VERSION "HNNBNNNYNNNNNNNNNNNNNNNNNNNNNNNNNNNNNNNNNN/4/%%%/4/'%**4NNN///"

NS_ :

BS_:

BU_: ABT_1_MIB_ab_Gen3 ABT_1_MQB BAP_Tester BT_1_MQB DU_1_MQB DU_2 DU_3 DU_4 ExBox Kombi_TT3 LSR_1 SCC1 SCC2 SDC1 SDC2 SFA TVTuner_ab_Gen3_JPN WLC_01 WLC_02 ZR_Entry ZR_High ZR_High_Korea ZR_High_TT3 ZR_MIB_OPTION_ab_Gen3 ZR_MIB_TOP_ab_Gen3 ZR_Standard

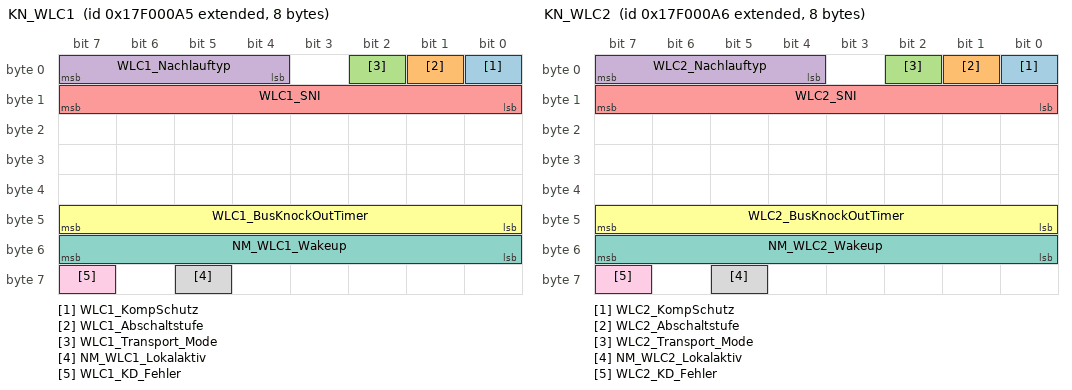
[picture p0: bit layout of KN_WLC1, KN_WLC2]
BO_ 2549088421 KN_WLC1: 8 WLC_01
 SG_ WLC1_KompSchutz : 0|1@1+ (1,0) [0|1] "" Vector__XXX
 SG_ WLC1_Abschaltstufe : 1|1@1+ (1,0) [0|1] "" Vector__XXX
 SG_ WLC1_Transport_Mode : 2|1@1+ (1,0) [0|1] "" Vector__XXX
 SG_ WLC1_Nachlauftyp : 4|4@1+ (1,0) [0|15] ""  ZR_High,ZR_High_Korea,ZR_MIB_OPTION_ab_Gen3,ZR_MIB_TOP_ab_Gen3,ZR_Standard
 SG_ WLC1_SNI : 8|8@1+ (1,0) [0|255] ""  ZR_High,ZR_High_Korea,ZR_MIB_OPTION_ab_Gen3,ZR_MIB_TOP_ab_Gen3,ZR_Standard
 SG_ WLC1_BusKnockOutTimer : 40|8@1+ (1,0) [0|254] "" Vector__XXX
 SG_ NM_WLC1_Wakeup : 48|8@1+ (1,0) [0|255] "" Vector__XXX
 SG_ NM_WLC1_Lokalaktiv : 61|1@1+ (1,0) [0|1] ""  ZR_High,ZR_High_Korea,ZR_MIB_OPTION_ab_Gen3,ZR_MIB_TOP_ab_Gen3,ZR_Standard
 SG_ WLC1_KD_Fehler : 63|1@1+ (1,0) [0|1] ""  ZR_High,ZR_High_Korea,ZR_MIB_OPTION_ab_Gen3,ZR_MIB_TOP_ab_Gen3,ZR_Standard

BO_ 2549088422 KN_WLC2: 8 WLC_02
 SG_ WLC2_KompSchutz : 0|1@1+ (1,0) [0|1] "" Vector__XXX
 SG_ WLC2_Abschaltstufe : 1|1@1+ (1,0) [0|1] "" Vector__XXX
 SG_ WLC2_Transport_Mode : 2|1@1+ (1,0) [0|1] "" Vector__XXX
 SG_ WLC2_Nachlauftyp : 4|4@1+ (1,0) [0|15] ""  ZR_High,ZR_High_Korea,ZR_MIB_OPTION_ab_Gen3,ZR_MIB_TOP_ab_Gen3,ZR_Standard
 SG_ WLC2_SNI : 8|8@1+ (1,0) [0|255] ""  ZR_High,ZR_High_Korea,ZR_MIB_OPTION_ab_Gen3,ZR_MIB_TOP_ab_Gen3,ZR_Standard
 SG_ WLC2_BusKnockOutTimer : 40|8@1+ (1,0) [0|254] "" Vector__XXX
 SG_ NM_WLC2_Wakeup : 48|8@1+ (1,0) [0|255] "" Vector__XXX
 SG_ NM_WLC2_Lokalaktiv : 61|1@1+ (1,0) [0|1] ""  ZR_High,ZR_High_Korea,ZR_MIB_OPTION_ab_Gen3,ZR_MIB_TOP_ab_Gen3,ZR_Standard
 SG_ WLC2_KD_Fehler : 63|1@1+ (1,0) [0|1] ""  ZR_High,ZR_High_Korea,ZR_MIB_OPTION_ab_Gen3,ZR_MIB_TOP_ab_Gen3,ZR_Standard

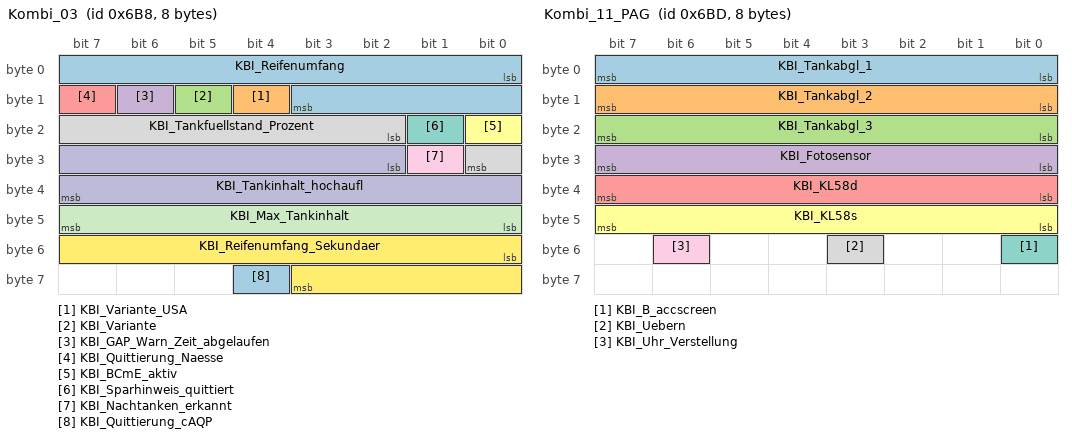
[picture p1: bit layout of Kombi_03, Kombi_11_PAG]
BO_ 1720 Kombi_03: 8 ZR_High_Korea
 SG_ KBI_Reifenumfang : 0|12@1+ (1,0) [0|4095] "Unit_MilliMeter"  ExBox
 SG_ KBI_Variante_USA : 12|1@1+ (1,0) [0|1] "" Vector__XXX
 SG_ KBI_Variante : 13|1@1+ (1,0) [0|1] "" Vector__XXX
 SG_ KBI_GAP_Warn_Zeit_abgelaufen : 14|1@1+ (1,0) [0|1] "" Vector__XXX
 SG_ KBI_Quittierung_Naesse : 15|1@1+ (1,0) [0|1] "" Vector__XXX
 SG_ KBI_BCmE_aktiv : 16|1@1+ (1,0) [0|1] "" Vector__XXX
 SG_ KBI_Sparhinweis_quittiert : 17|1@1+ (1,0) [0|1] "" Vector__XXX
 SG_ KBI_Tankfuellstand_Prozent : 18|7@1+ (1,0) [0|100] "Unit_PerCent" Vector__XXX
 SG_ KBI_Nachtanken_erkannt : 25|1@1+ (1,0) [0|1] "" Vector__XXX
 SG_ KBI_Tankinhalt_hochaufl : 26|14@1+ (0.01,0) [0|163.81] "Unit_Liter" Vector__XXX
 SG_ KBI_Max_Tankinhalt : 40|8@1+ (0.5,0) [0|126.5] "" Vector__XXX
 SG_ KBI_Reifenumfang_Sekundaer : 48|12@1+ (1,0) [0|4095] "Unit_MilliMeter" Vector__XXX
 SG_ KBI_Quittierung_cAQP : 60|1@1+ (1,0) [0|1] "" Vector__XXX

BO_ 1725 Kombi_11_PAG: 8 ZR_High
 SG_ KBI_Tankabgl_1 : 0|8@1+ (1,0) [0|255] "" Vector__XXX
 SG_ KBI_Tankabgl_2 : 8|8@1+ (1,0) [0|255] "" Vector__XXX
 SG_ KBI_Tankabgl_3 : 16|8@1+ (1,0) [0|255] "" Vector__XXX
 SG_ KBI_Fotosensor : 24|8@1+ (0.1,0) [0|25.3] "Unit_WattPerMeterSquar"  ABT_1_MQB
 SG_ KBI_KL58d : 32|8@1+ (0.4,0) [0|100] "Unit_PerCent" Vector__XXX
 SG_ KBI_KL58s : 40|8@1+ (1,0) [0|100] "Unit_PerCent"  ABT_1_MQB
 SG_ KBI_B_accscreen : 48|1@1+ (1,0) [0|1] "" Vector__XXX
 SG_ KBI_Uebern : 51|1@1+ (1,0) [0|1] "" Vector__XXX
 SG_ KBI_Uhr_Verstellung : 54|1@1+ (1,0) [0|1] "" Vector__XXX

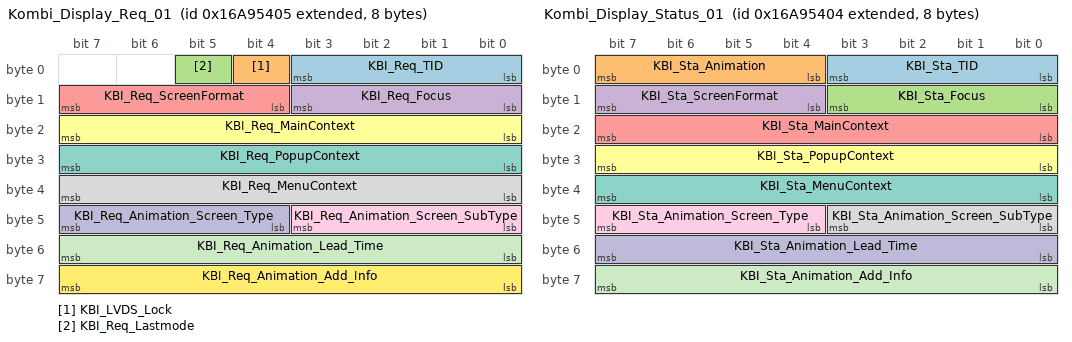
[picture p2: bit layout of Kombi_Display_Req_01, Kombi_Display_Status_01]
BO_ 2527679493 Kombi_Display_Req_01: 8 Kombi_TT3
 SG_ KBI_Req_TID : 0|4@1+ (1,0) [1|15] ""  ZR_High_TT3
 SG_ KBI_LVDS_Lock : 4|1@1+ (1,0) [0|1] ""  ZR_High_TT3
 SG_ KBI_Req_Lastmode : 5|1@1+ (1,0) [0|1] ""  ZR_High_TT3
 SG_ KBI_Req_Focus : 8|4@1+ (1,0) [0|15] ""  ZR_High_TT3
 SG_ KBI_Req_ScreenFormat : 12|4@1+ (1,0) [0|15] ""  ZR_High_TT3
 SG_ KBI_Req_MainContext : 16|8@1+ (1,0) [0|255] ""  ZR_High_TT3
 SG_ KBI_Req_PopupContext : 24|8@1+ (1,0) [2|255] ""  ZR_High_TT3
 SG_ KBI_Req_MenuContext : 32|8@1+ (1,0) [0|255] ""  ZR_High_TT3
 SG_ KBI_Req_Animation_Screen_SubType : 40|4@1+ (1,0) [0|15] ""  ZR_High_TT3
 SG_ KBI_Req_Animation_Screen_Type : 44|4@1+ (1,0) [0|15] ""  ZR_High_TT3
 SG_ KBI_Req_Animation_Lead_Time : 48|8@1+ (10,0) [0|2540] "Unit_MilliSecon"  ZR_High_TT3
 SG_ KBI_Req_Animation_Add_Info : 56|8@1+ (1,0) [0|255] ""  ZR_High_TT3

BO_ 2527679492 Kombi_Display_Status_01: 8 Kombi_TT3
 SG_ KBI_Sta_TID : 0|4@1+ (1,0) [1|15] ""  ZR_High_TT3
 SG_ KBI_Sta_Animation : 4|4@1+ (1,0) [0|15] ""  ZR_High_TT3
 SG_ KBI_Sta_Focus : 8|4@1+ (1,0) [0|15] ""  ZR_High_TT3
 SG_ KBI_Sta_ScreenFormat : 12|4@1+ (1,0) [0|15] ""  ZR_High_TT3
 SG_ KBI_Sta_MainContext : 16|8@1+ (1,0) [0|255] ""  ZR_High_TT3
 SG_ KBI_Sta_PopupContext : 24|8@1+ (1,0) [0|255] ""  ZR_High_TT3
 SG_ KBI_Sta_MenuContext : 32|8@1+ (1,0) [0|255] ""  ZR_High_TT3
 SG_ KBI_Sta_Animation_Screen_SubType : 40|4@1+ (1,0) [0|15] ""  ZR_High_TT3
 SG_ KBI_Sta_Animation_Screen_Type : 44|4@1+ (1,0) [0|15] ""  ZR_High_TT3
 SG_ KBI_Sta_Animation_Lead_Time : 48|8@1+ (10,0) [0|2540] "Unit_MilliSecon"  ZR_High_TT3
 SG_ KBI_Sta_Animation_Add_Info : 56|8@1+ (1,0) [0|255] ""  ZR_High_TT3

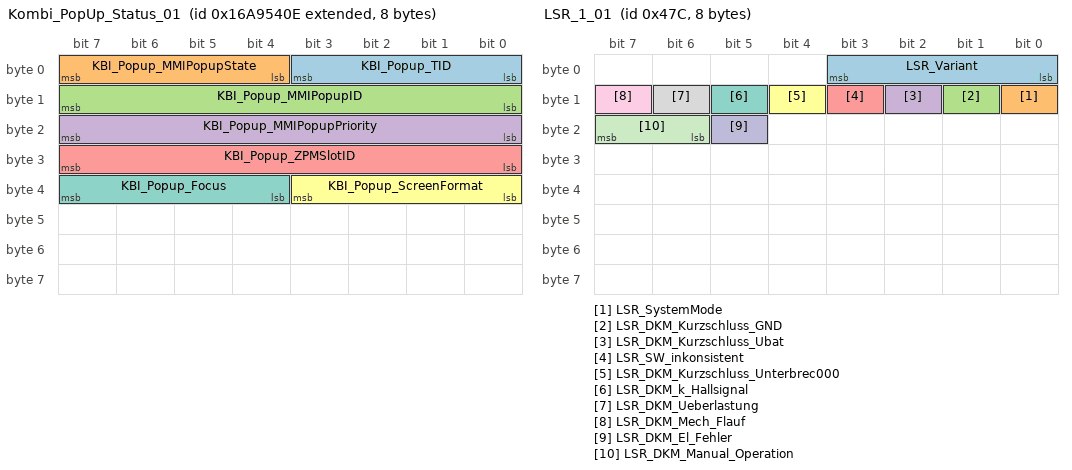
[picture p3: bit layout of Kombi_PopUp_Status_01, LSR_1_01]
BO_ 2527679502 Kombi_PopUp_Status_01: 8 Kombi_TT3
 SG_ KBI_Popup_TID : 0|4@1+ (1,0) [0|15] ""  ZR_High_TT3
 SG_ KBI_Popup_MMIPopupState : 4|4@1+ (1,0) [0|15] ""  ZR_High_TT3
 SG_ KBI_Popup_MMIPopupID : 8|8@1+ (1,0) [0|255] ""  ZR_High_TT3
 SG_ KBI_Popup_MMIPopupPriority : 16|8@1+ (1,0) [0|255] ""  ZR_High_TT3
 SG_ KBI_Popup_ZPMSlotID : 24|8@1+ (1,0) [0|255] ""  ZR_High_TT3
 SG_ KBI_Popup_ScreenFormat : 32|4@1+ (1,0) [0|15] ""  ZR_High_TT3
 SG_ KBI_Popup_Focus : 36|4@1+ (1,0) [0|15] ""  ZR_High_TT3

BO_ 2549899278 KS_SSN_ABT_1_Req: 8 Vector__XXX
 SG_ KS_SSN_ABT_1_Req_Data : 0|64@1+ (1,0) [0|1.84467440737096E+019] ""  ABT_1_MIB_ab_Gen3

BO_ 2550030350 KS_SSN_ABT_1_Resp: 8 ABT_1_MIB_ab_Gen3
 SG_ KS_SSN_ABT_1_Resp_Data : 0|64@1+ (1,0) [0|1.84467440737096E+019] "" Vector__XXX

BO_ 1148 LSR_1_01: 8 LSR_1
 SG_ LSR_Variant : 0|4@1+ (1,0) [1|15] ""  ZR_High,ZR_MIB_OPTION_ab_Gen3,ZR_MIB_TOP_ab_Gen3,ZR_Standard
 SG_ LSR_SystemMode : 8|1@1+ (1,0) [0|1] ""  ZR_High,ZR_MIB_OPTION_ab_Gen3,ZR_MIB_TOP_ab_Gen3,ZR_Standard
 SG_ LSR_DKM_Kurzschluss_GND : 9|1@1+ (1,0) [0|1] ""  ZR_High,ZR_MIB_OPTION_ab_Gen3,ZR_MIB_TOP_ab_Gen3,ZR_Standard
 SG_ LSR_DKM_Kurzschluss_Ubat : 10|1@1+ (1,0) [0|1] ""  ZR_High,ZR_MIB_OPTION_ab_Gen3,ZR_MIB_TOP_ab_Gen3,ZR_Standard
 SG_ LSR_SW_inkonsistent : 11|1@1+ (1,0) [0|1] ""  ZR_High,ZR_MIB_OPTION_ab_Gen3,ZR_MIB_TOP_ab_Gen3,ZR_Standard
 SG_ LSR_DKM_Kurzschluss_Unterbrec000 : 12|1@1+ (1,0) [0|1] ""  ZR_High,ZR_MIB_OPTION_ab_Gen3,ZR_MIB_TOP_ab_Gen3,ZR_Standard
 SG_ LSR_DKM_k_Hallsignal : 13|1@1+ (1,0) [0|1] ""  ZR_High,ZR_MIB_OPTION_ab_Gen3,ZR_MIB_TOP_ab_Gen3,ZR_Standard
 SG_ LSR_DKM_Ueberlastung : 14|1@1+ (1,0) [0|1] ""  ZR_High,ZR_MIB_OPTION_ab_Gen3,ZR_MIB_TOP_ab_Gen3,ZR_Standard
 SG_ LSR_DKM_Mech_Flauf : 15|1@1+ (1,0) [0|1] ""  ZR_High,ZR_MIB_OPTION_ab_Gen3,ZR_MIB_TOP_ab_Gen3,ZR_Standard
 SG_ LSR_DKM_El_Fehler : 21|1@1+ (1,0) [0|1] ""  ZR_High,ZR_MIB_OPTION_ab_Gen3,ZR_MIB_TOP_ab_Gen3,ZR_Standard
 SG_ LSR_DKM_Manual_Operation : 22|2@1+ (1,0) [0|3] ""  ZR_High,ZR_MIB_OPTION_ab_Gen3,ZR_MIB_TOP_ab_Gen3,ZR_Standard

BO_ 2583754245 LSR_1_SWDL_Req: 8 LSR_1
 SG_ LSR_1_SWDL_Req_Data : 0|64@1+ (1,0) [0|1.84467440737096E+019] ""  ZR_High,ZR_MIB_OPTION_ab_Gen3,ZR_MIB_TOP_ab_Gen3,ZR_Standard

BO_ 2583885317 LSR_1_SWDL_Resp: 8 ZR_High
 SG_ LSR_1_SWDL_Resp_Data : 0|64@1+ (1,0) [0|1.84467440737096E+019] ""  LSR_1

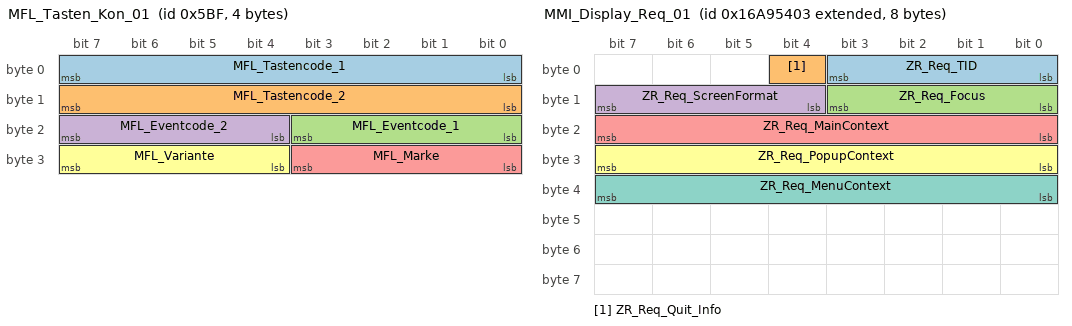
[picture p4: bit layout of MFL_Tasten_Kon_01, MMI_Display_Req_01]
BO_ 1471 MFL_Tasten_Kon_01: 4 ZR_High_Korea
 SG_ MFL_Tastencode_1 : 0|8@1+ (1,0) [0|255] ""  Kombi_TT3
 SG_ MFL_Tastencode_2 : 8|8@1+ (1,0) [0|255] ""  ExBox,Kombi_TT3
 SG_ MFL_Eventcode_1 : 16|4@1+ (1,0) [0|15] ""  ExBox,Kombi_TT3
 SG_ MFL_Eventcode_2 : 20|4@1+ (1,0) [0|15] ""  ExBox,Kombi_TT3
 SG_ MFL_Marke : 24|4@1+ (1,0) [0|15] ""  ExBox,Kombi_TT3
 SG_ MFL_Variante : 28|4@1+ (1,0) [0|15] ""  ExBox,Kombi_TT3

BO_ 2527679491 MMI_Display_Req_01: 8 ZR_High_TT3
 SG_ ZR_Req_TID : 0|4@1+ (1,0) [1|15] ""  Kombi_TT3
 SG_ ZR_Req_Quit_Info : 4|1@1+ (1,0) [0|1] ""  Kombi_TT3
 SG_ ZR_Req_Focus : 8|4@1+ (1,0) [0|15] ""  Kombi_TT3
 SG_ ZR_Req_ScreenFormat : 12|4@1+ (1,0) [0|15] ""  Kombi_TT3
 SG_ ZR_Req_MainContext : 16|8@1+ (1,0) [0|255] ""  Kombi_TT3
 SG_ ZR_Req_PopupContext : 24|8@1+ (1,0) [0|255] ""  Kombi_TT3
 SG_ ZR_Req_MenuContext : 32|8@1+ (1,0) [0|255] ""  Kombi_TT3

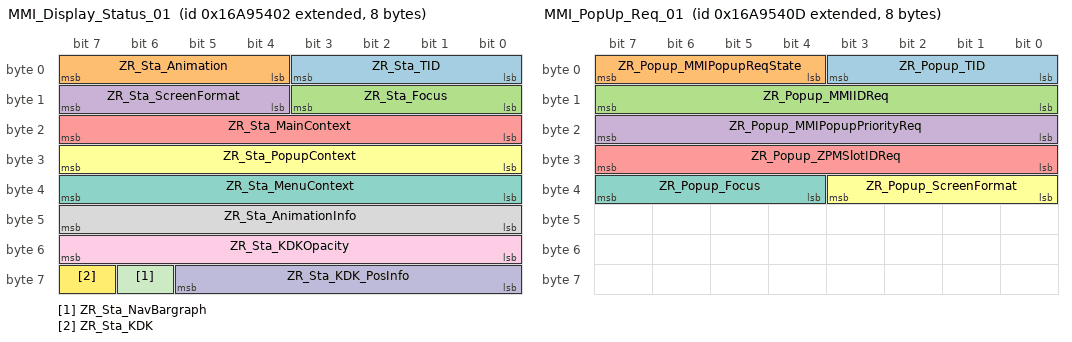
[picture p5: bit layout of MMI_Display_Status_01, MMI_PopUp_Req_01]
BO_ 2527679490 MMI_Display_Status_01: 8 ZR_High_TT3
 SG_ ZR_Sta_TID : 0|4@1+ (1,0) [1|15] ""  Kombi_TT3
 SG_ ZR_Sta_Animation : 4|4@1+ (1,0) [0|15] ""  Kombi_TT3
 SG_ ZR_Sta_Focus : 8|4@1+ (1,0) [0|15] ""  Kombi_TT3
 SG_ ZR_Sta_ScreenFormat : 12|4@1+ (1,0) [0|15] ""  Kombi_TT3
 SG_ ZR_Sta_MainContext : 16|8@1+ (1,0) [0|255] ""  Kombi_TT3
 SG_ ZR_Sta_PopupContext : 24|8@1+ (1,0) [0|255] ""  Kombi_TT3
 SG_ ZR_Sta_MenuContext : 32|8@1+ (1,0) [0|255] ""  Kombi_TT3
 SG_ ZR_Sta_AnimationInfo : 40|8@1+ (1,0) [1|255] ""  Kombi_TT3
 SG_ ZR_Sta_KDKOpacity : 48|8@1+ (1,0) [1|255] ""  Kombi_TT3
 SG_ ZR_Sta_KDK_PosInfo : 56|6@1+ (1,0) [1|63] ""  Kombi_TT3
 SG_ ZR_Sta_NavBargraph : 62|1@1+ (1,0) [0|1] ""  Kombi_TT3
 SG_ ZR_Sta_KDK : 63|1@1+ (1,0) [0|1] ""  Kombi_TT3

BO_ 2527679501 MMI_PopUp_Req_01: 8 ZR_High_TT3
 SG_ ZR_Popup_TID : 0|4@1+ (1,0) [0|15] ""  Kombi_TT3
 SG_ ZR_Popup_MMIPopupReqState : 4|4@1+ (1,0) [0|15] ""  Kombi_TT3
 SG_ ZR_Popup_MMIIDReq : 8|8@1+ (1,0) [0|255] ""  Kombi_TT3
 SG_ ZR_Popup_MMIPopupPriorityReq : 16|8@1+ (1,0) [0|255] ""  Kombi_TT3
 SG_ ZR_Popup_ZPMSlotIDReq : 24|8@1+ (1,0) [0|255] ""  Kombi_TT3
 SG_ ZR_Popup_ScreenFormat : 32|4@1+ (1,0) [0|15] ""  Kombi_TT3
 SG_ ZR_Popup_Focus : 36|4@1+ (1,0) [0|15] ""  Kombi_TT3

BO_ 2527679499 MMI_Status: 8 ZR_High_TT3
 SG_ ZR_Sta_360_View : 0|2@1+ (1,0) [0|3] ""  Kombi_TT3
 SG_ ZR_Sta_Favoriten : 2|2@1+ (1,0) [0|3] ""  Kombi_TT3
 SG_ ZR_Sta_Laden : 4|2@1+ (1,0) [0|3] ""  Kombi_TT3
 SG_ ZR_Sta_FAS : 6|2@1+ (1,0) [0|3] ""  Kombi_TT3
 SG_ ZR_Sta_Fzg_Einst : 8|2@1+ (1,0) [0|3] ""  Kombi_TT3
 SG_ ZR_Sta_Klima : 10|2@1+ (1,0) [0|3] ""  Kombi_TT3
 SG_ ZR_Sta_Standhzg : 12|2@1+ (1,0) [0|3] ""  Kombi_TT3
 SG_ ZR_Sta_Service : 14|2@1+ (1,0) [0|3] ""  Kombi_TT3
 SG_ ZR_Sta_Fahrprofil : 16|2@1+ (1,0) [0|3] ""  Kombi_TT3
 SG_ ZR_Sta_Race : 18|2@1+ (1,0) [0|3] ""  Kombi_TT3
 SG_ ZR_Sta_Office : 20|2@1+ (1,0) [0|3] ""  Kombi_TT3
 SG_ ZR_Sta_Bordbuch : 22|2@1+ (1,0) [0|3] ""  Kombi_TT3
 SG_ ZR_Sta_Profile : 24|2@1+ (1,0) [0|3] ""  Kombi_TT3
 SG_ ZR_Sta_Connect : 26|2@1+ (1,0) [0|3] ""  Kombi_TT3
 SG_ ZR_Sta_Klang : 28|2@1+ (1,0) [0|3] ""  Kombi_TT3
 SG_ ZR_Sta_Systemeinst : 30|2@1+ (1,0) [0|3] ""  Kombi_TT3
 SG_ ZR_Sta_ConnectivityManager : 32|2@1+ (1,0) [0|3] ""  Kombi_TT3
 SG_ ZR_Sta_ETC : 34|2@1+ (1,0) [0|3] ""  Kombi_TT3
 SG_ ZR_Sta_SmartPhone : 36|2@1+ (1,0) [0|3] ""  Kombi_TT3
 SG_ ZR_Sta_B_Call : 40|2@1+ (1,0) [0|3] ""  Kombi_TT3
 SG_ ZR_Sta_C_Call : 42|2@1+ (1,0) [0|3] ""  Kombi_TT3
 SG_ ZR_Sta_VICS : 44|2@1+ (1,0) [0|3] ""  Kombi_TT3
 SG_ ZR_Sta_TPEG : 46|2@1+ (1,0) [0|3] ""  Kombi_TT3

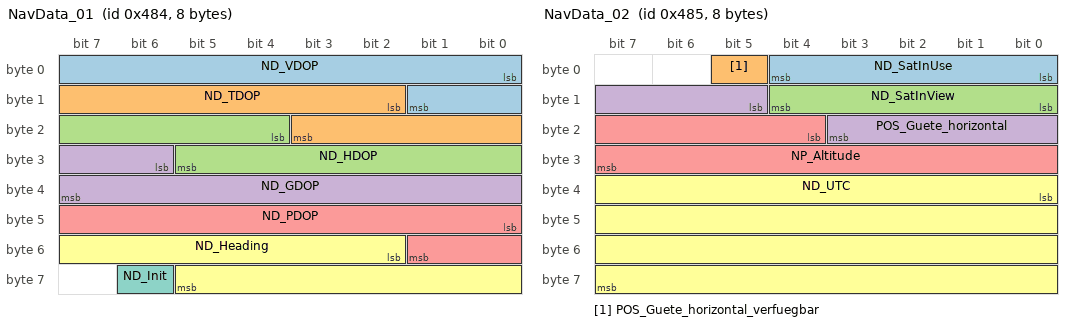
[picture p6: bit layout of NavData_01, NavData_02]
BO_ 1156 NavData_01: 8 ExBox
 SG_ ND_VDOP : 0|10@1+ (0.025,0) [0|25] ""  ZR_High_Korea
 SG_ ND_TDOP : 10|10@1+ (0.025,0) [0|25] ""  ZR_High_Korea
 SG_ ND_HDOP : 20|10@1+ (0.025,0) [0|25] ""  ZR_High_Korea
 SG_ ND_GDOP : 30|10@1+ (0.025,0) [0|25] ""  ZR_High_Korea
 SG_ ND_PDOP : 40|10@1+ (0.025,0) [0|25] ""  ZR_High_Korea
 SG_ ND_Heading : 50|12@1+ (0.1,0) [0|359.9] "Unit_DegreOfArc"  ZR_High_Korea
 SG_ ND_Init : 62|1@1+ (1,0) [0|1] ""  ZR_High_Korea

BO_ 1157 NavData_02: 8 ExBox
 SG_ ND_SatInUse : 0|5@1+ (1,0) [0|29] ""  ZR_High_Korea
 SG_ POS_Guete_horizontal_verfuegbar : 5|1@1+ (1,0) [0|1] ""  ZR_High_Korea
 SG_ ND_SatInView : 8|5@1+ (1,0) [0|29] ""  ZR_High_Korea
 SG_ POS_Guete_horizontal : 13|7@1+ (2,0) [0|246] "Unit_Meter"  ZR_High_Korea
 SG_ NP_Altitude : 20|12@1+ (2,-500) [-500|7686] "Unit_Meter"  ZR_High_Korea
 SG_ ND_UTC : 32|32@1+ (1,0) [0|4294967293] "Unit_Secon"  ZR_High_Korea

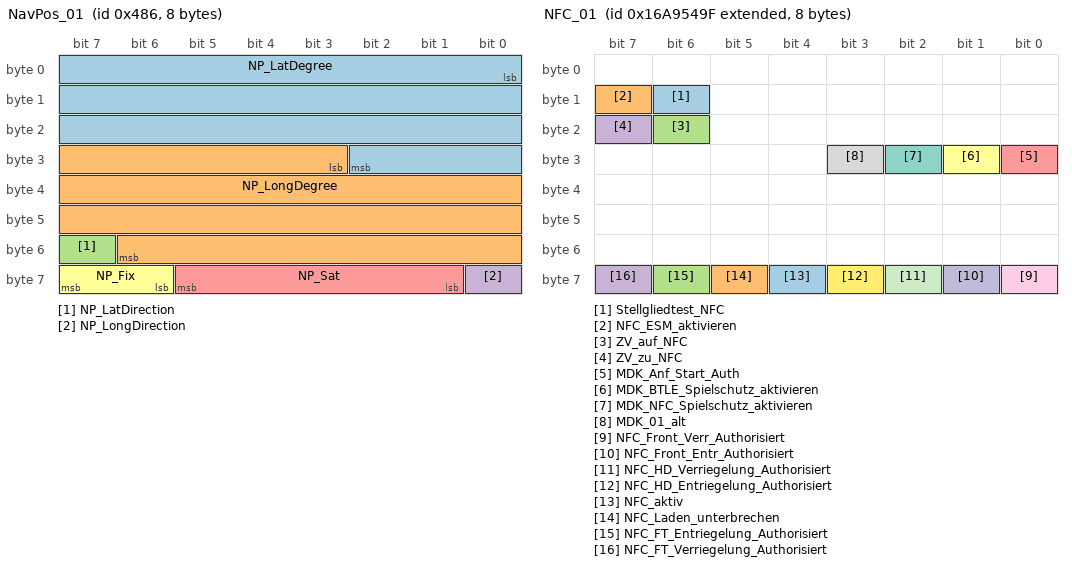
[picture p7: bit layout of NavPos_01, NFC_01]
BO_ 1158 NavPos_01: 8 ExBox
 SG_ NP_LatDegree : 0|27@1+ (1E-006,0) [0|90] "Unit_DegreOfArc"  ZR_High_Korea
 SG_ NP_LongDegree : 27|28@1+ (1E-006,0) [0|180] "Unit_DegreOfArc"  ZR_High_Korea
 SG_ NP_LatDirection : 55|1@1+ (1,0) [0|1] ""  ZR_High_Korea
 SG_ NP_LongDirection : 56|1@1+ (1,0) [0|1] ""  ZR_High_Korea
 SG_ NP_Sat : 57|5@1+ (1,0) [0|29] ""  ZR_High_Korea
 SG_ NP_Fix : 62|2@1+ (1,0) [0|3] ""  ZR_High_Korea

BO_ 2589283496 NavPos_02_Map_Matched: 8 ExBox
 SG_ POS_MUX M : 0|2@1+ (1,0) [0|3] ""  ZR_High_Korea
 SG_ POS_ODD_EVEN : 2|1@1+ (1,0) [0|1] ""  ZR_High_Korea
 SG_ POS_PosStati m0 : 3|4@1+ (1,0) [0|15] ""  ZR_High_Korea
 SG_ POS_Heading m1 : 4|12@1+ (0.1,0) [0|409.5] "Unit_DegreOfArc"  ZR_High_Korea
 SG_ POS_LatDirection m0 : 7|1@1+ (1,0) [0|1] ""  ZR_High_Korea
 SG_ POS_LatDegree m0 : 8|27@1+ (1E-006,0) [0|90] "Unit_DegreOfArc"  ZR_High_Korea
 SG_ POS_Last_GPS_Sync m1 : 16|14@1+ (1,0) [0|16383] "Unit_Secon"  ZR_High_Korea
 SG_ POS_Heading_Trust m1 : 30|2@1+ (1,0) [0|3] ""  ZR_High_Korea
 SG_ POS_UTC_REF m1 : 32|32@1+ (1,0) [0|4294967295] "Unit_Secon"  ZR_High_Korea
 SG_ POS_LongDirection m0 : 35|1@1+ (1,0) [0|1] ""  ZR_High_Korea
 SG_ POS_LongDegree m0 : 36|28@1+ (1E-006,0) [0|180] "Unit_DegreOfArc"  ZR_High_Korea

BO_ 2527679647 NFC_01: 8 ZR_High
 SG_ Stellgliedtest_NFC : 14|1@1+ (1,0) [0|1] "" Vector__XXX
 SG_ NFC_ESM_aktivieren : 15|1@1+ (1,0) [0|1] "" Vector__XXX
 SG_ ZV_auf_NFC : 22|1@1+ (1,0) [0|1] "" Vector__XXX
 SG_ ZV_zu_NFC : 23|1@1+ (1,0) [0|1] "" Vector__XXX
 SG_ MDK_Anf_Start_Auth : 24|1@1+ (1,0) [0|1] "" Vector__XXX
 SG_ MDK_BTLE_Spielschutz_aktivieren : 25|1@1+ (1,0) [0|1] "" Vector__XXX
 SG_ MDK_NFC_Spielschutz_aktivieren : 26|1@1+ (1,0) [0|1] "" Vector__XXX
 SG_ MDK_01_alt : 27|1@1+ (1,0) [0|1] "" Vector__XXX
 SG_ NFC_Front_Verr_Authorisiert : 56|1@1+ (1,0) [0|1] "" Vector__XXX
 SG_ NFC_Front_Entr_Authorisiert : 57|1@1+ (1,0) [0|1] "" Vector__XXX
 SG_ NFC_HD_Verriegelung_Authorisiert : 58|1@1+ (1,0) [0|1] "" Vector__XXX
 SG_ NFC_HD_Entriegelung_Authorisiert : 59|1@1+ (1,0) [0|1] "" Vector__XXX
 SG_ NFC_aktiv : 60|1@1+ (1,0) [0|1] "" Vector__XXX
 SG_ NFC_Laden_unterbrechen : 61|1@1+ (1,0) [0|1] ""  WLC_02,WLC_01
 SG_ NFC_FT_Entriegelung_Authorisiert : 62|1@1+ (1,0) [0|1] "" Vector__XXX
 SG_ NFC_FT_Verriegelung_Authorisiert : 63|1@1+ (1,0) [0|1] "" Vector__XXX

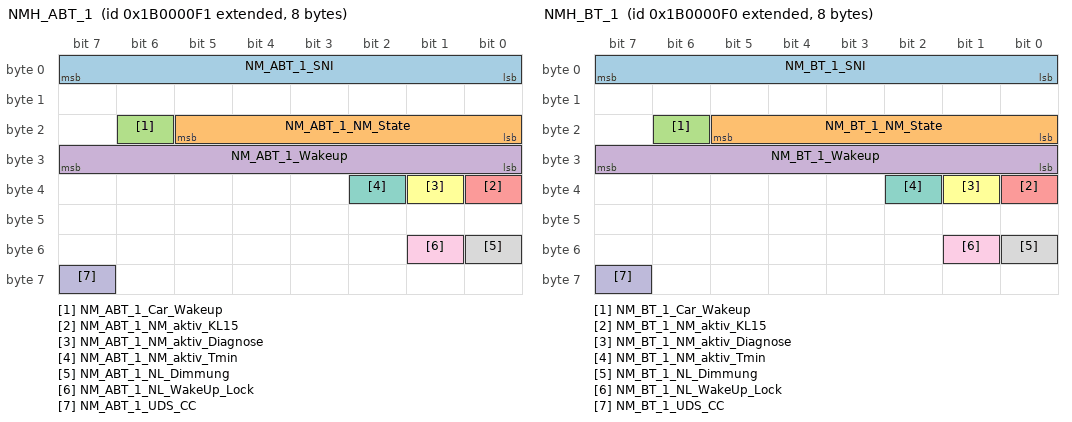
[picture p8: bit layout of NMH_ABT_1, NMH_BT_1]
BO_ 2600468721 NMH_ABT_1: 8 ABT_1_MIB_ab_Gen3
 SG_ NM_ABT_1_SNI : 0|8@1+ (1,0) [0|255] "" Vector__XXX
 SG_ NM_ABT_1_NM_State : 16|6@1+ (1,0) [0|63] ""  ABT_1_MIB_ab_Gen3,ABT_1_MQB,BT_1_MQB,DU_1_MQB,DU_2,DU_3,DU_4,ExBox,Kombi_TT3,LSR_1,SCC1,SCC2,SDC1,SDC2,SFA,TVTuner_ab_Gen3_JPN,WLC_01,WLC_02,ZR_Entry,ZR_High,ZR_High_Korea,ZR_High_TT3,ZR_MIB_OPTION_ab_Gen3,ZR_MIB_TOP_ab_Gen3,ZR_Standard
 SG_ NM_ABT_1_Car_Wakeup : 22|1@1+ (1,0) [0|1] "" Vector__XXX
 SG_ NM_ABT_1_Wakeup : 24|8@1+ (1,0) [0|255] "" Vector__XXX
 SG_ NM_ABT_1_NM_aktiv_KL15 : 32|1@1+ (1,0) [0|1] "" Vector__XXX
 SG_ NM_ABT_1_NM_aktiv_Diagnose : 33|1@1+ (1,0) [0|1] "" Vector__XXX
 SG_ NM_ABT_1_NM_aktiv_Tmin : 34|1@1+ (1,0) [0|1] "" Vector__XXX
 SG_ NM_ABT_1_NL_Dimmung : 48|1@1+ (1,0) [0|1] "" Vector__XXX
 SG_ NM_ABT_1_NL_WakeUp_Lock : 49|1@1+ (1,0) [0|1] "" Vector__XXX
 SG_ NM_ABT_1_UDS_CC : 63|1@1+ (1,0) [0|1] "" Vector__XXX

BO_ 2600468720 NMH_BT_1: 8 BT_1_MQB
 SG_ NM_BT_1_SNI : 0|8@1+ (1,0) [0|255] "" Vector__XXX
 SG_ NM_BT_1_NM_State : 16|6@1+ (1,0) [0|63] ""  ABT_1_MIB_ab_Gen3,ABT_1_MQB,BT_1_MQB,DU_1_MQB,DU_2,DU_3,DU_4,ExBox,Kombi_TT3,LSR_1,SCC1,SCC2,SDC1,SDC2,SFA,TVTuner_ab_Gen3_JPN,WLC_01,WLC_02,ZR_Entry,ZR_High,ZR_High_Korea,ZR_High_TT3,ZR_MIB_OPTION_ab_Gen3,ZR_MIB_TOP_ab_Gen3,ZR_Standard
 SG_ NM_BT_1_Car_Wakeup : 22|1@1+ (1,0) [0|1] "" Vector__XXX
 SG_ NM_BT_1_Wakeup : 24|8@1+ (1,0) [0|255] "" Vector__XXX
 SG_ NM_BT_1_NM_aktiv_KL15 : 32|1@1+ (1,0) [0|1] "" Vector__XXX
 SG_ NM_BT_1_NM_aktiv_Diagnose : 33|1@1+ (1,0) [0|1] "" Vector__XXX
 SG_ NM_BT_1_NM_aktiv_Tmin : 34|1@1+ (1,0) [0|1] "" Vector__XXX
 SG_ NM_BT_1_NL_Dimmung : 48|1@1+ (1,0) [0|1] "" Vector__XXX
 SG_ NM_BT_1_NL_WakeUp_Lock : 49|1@1+ (1,0) [0|1] "" Vector__XXX
 SG_ NM_BT_1_UDS_CC : 63|1@1+ (1,0) [0|1] "" Vector__XXX

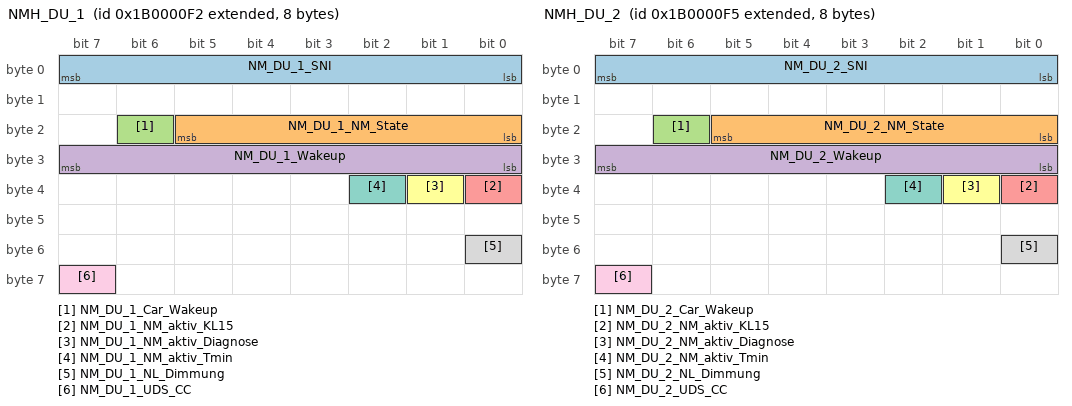
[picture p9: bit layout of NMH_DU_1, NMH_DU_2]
BO_ 2600468722 NMH_DU_1: 8 DU_1_MQB
 SG_ NM_DU_1_SNI : 0|8@1+ (1,0) [0|255] "" Vector__XXX
 SG_ NM_DU_1_NM_State : 16|6@1+ (1,0) [0|63] ""  ABT_1_MIB_ab_Gen3,ABT_1_MQB,BT_1_MQB,DU_1_MQB,DU_2,DU_3,DU_4,ExBox,Kombi_TT3,LSR_1,SCC1,SCC2,SDC1,SDC2,SFA,TVTuner_ab_Gen3_JPN,WLC_01,WLC_02,ZR_Entry,ZR_High,ZR_High_Korea,ZR_High_TT3,ZR_MIB_OPTION_ab_Gen3,ZR_MIB_TOP_ab_Gen3,ZR_Standard
 SG_ NM_DU_1_Car_Wakeup : 22|1@1+ (1,0) [0|1] "" Vector__XXX
 SG_ NM_DU_1_Wakeup : 24|8@1+ (1,0) [0|255] "" Vector__XXX
 SG_ NM_DU_1_NM_aktiv_KL15 : 32|1@1+ (1,0) [0|1] "" Vector__XXX
 SG_ NM_DU_1_NM_aktiv_Diagnose : 33|1@1+ (1,0) [0|1] "" Vector__XXX
 SG_ NM_DU_1_NM_aktiv_Tmin : 34|1@1+ (1,0) [0|1] "" Vector__XXX
 SG_ NM_DU_1_NL_Dimmung : 48|1@1+ (1,0) [0|1] "" Vector__XXX
 SG_ NM_DU_1_UDS_CC : 63|1@1+ (1,0) [0|1] "" Vector__XXX

BO_ 2600468725 NMH_DU_2: 8 DU_2
 SG_ NM_DU_2_SNI : 0|8@1+ (1,0) [0|255] "" Vector__XXX
 SG_ NM_DU_2_NM_State : 16|6@1+ (1,0) [0|63] ""  ABT_1_MIB_ab_Gen3,ABT_1_MQB,BT_1_MQB,DU_1_MQB,DU_2,DU_3,DU_4,ExBox,Kombi_TT3,LSR_1,SCC1,SCC2,SDC1,SDC2,SFA,TVTuner_ab_Gen3_JPN,WLC_01,WLC_02,ZR_Entry,ZR_High,ZR_High_Korea,ZR_High_TT3,ZR_MIB_OPTION_ab_Gen3,ZR_MIB_TOP_ab_Gen3,ZR_Standard
 SG_ NM_DU_2_Car_Wakeup : 22|1@1+ (1,0) [0|1] "" Vector__XXX
 SG_ NM_DU_2_Wakeup : 24|8@1+ (1,0) [0|255] "" Vector__XXX
 SG_ NM_DU_2_NM_aktiv_KL15 : 32|1@1+ (1,0) [0|1] "" Vector__XXX
 SG_ NM_DU_2_NM_aktiv_Diagnose : 33|1@1+ (1,0) [0|1] "" Vector__XXX
 SG_ NM_DU_2_NM_aktiv_Tmin : 34|1@1+ (1,0) [0|1] "" Vector__XXX
 SG_ NM_DU_2_NL_Dimmung : 48|1@1+ (1,0) [0|1] "" Vector__XXX
 SG_ NM_DU_2_UDS_CC : 63|1@1+ (1,0) [0|1] "" Vector__XXX

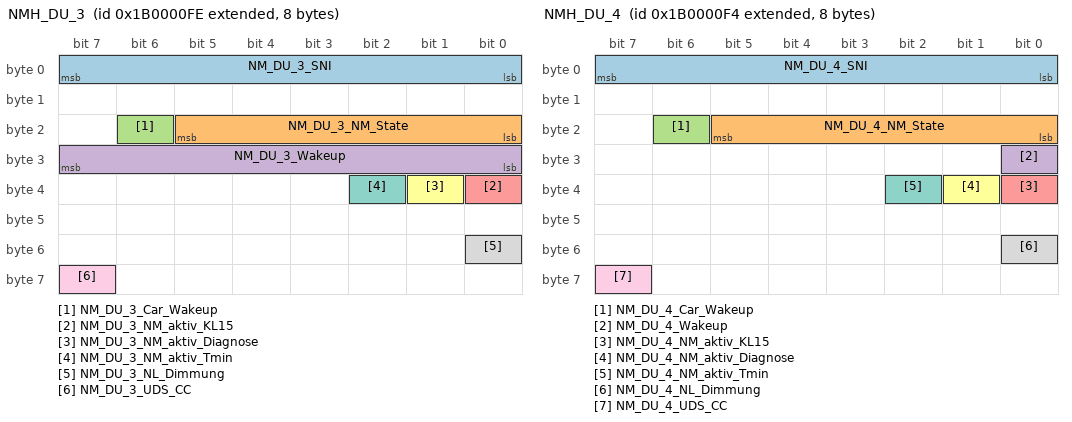
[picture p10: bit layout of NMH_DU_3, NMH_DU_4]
BO_ 2600468734 NMH_DU_3: 8 DU_3
 SG_ NM_DU_3_SNI : 0|8@1+ (1,0) [0|255] "" Vector__XXX
 SG_ NM_DU_3_NM_State : 16|6@1+ (1,0) [0|63] ""  ABT_1_MIB_ab_Gen3,ABT_1_MQB,BT_1_MQB,DU_1_MQB,DU_2,DU_3,DU_4,ExBox,Kombi_TT3,LSR_1,SCC1,SCC2,SDC1,SDC2,SFA,TVTuner_ab_Gen3_JPN,WLC_01,WLC_02,ZR_Entry,ZR_High,ZR_High_Korea,ZR_High_TT3,ZR_MIB_OPTION_ab_Gen3,ZR_MIB_TOP_ab_Gen3,ZR_Standard
 SG_ NM_DU_3_Car_Wakeup : 22|1@1+ (1,0) [0|1] "" Vector__XXX
 SG_ NM_DU_3_Wakeup : 24|8@1+ (1,0) [0|255] "" Vector__XXX
 SG_ NM_DU_3_NM_aktiv_KL15 : 32|1@1+ (1,0) [0|1] "" Vector__XXX
 SG_ NM_DU_3_NM_aktiv_Diagnose : 33|1@1+ (1,0) [0|1] "" Vector__XXX
 SG_ NM_DU_3_NM_aktiv_Tmin : 34|1@1+ (1,0) [0|1] "" Vector__XXX
 SG_ NM_DU_3_NL_Dimmung : 48|1@1+ (1,0) [0|1] "" Vector__XXX
 SG_ NM_DU_3_UDS_CC : 63|1@1+ (1,0) [0|1] "" Vector__XXX

BO_ 2600468724 NMH_DU_4: 8 DU_4
 SG_ NM_DU_4_SNI : 0|8@1+ (1,0) [0|255] "" Vector__XXX
 SG_ NM_DU_4_NM_State : 16|6@1+ (1,0) [0|63] ""  ABT_1_MIB_ab_Gen3,ABT_1_MQB,BT_1_MQB,DU_1_MQB,DU_2,DU_3,DU_4,ExBox,Kombi_TT3,LSR_1,SCC1,SCC2,SDC1,SDC2,SFA,TVTuner_ab_Gen3_JPN,WLC_01,WLC_02,ZR_Entry,ZR_High,ZR_High_Korea,ZR_High_TT3,ZR_MIB_OPTION_ab_Gen3,ZR_MIB_TOP_ab_Gen3,ZR_Standard
 SG_ NM_DU_4_Car_Wakeup : 22|1@1+ (1,0) [0|1] "" Vector__XXX
 SG_ NM_DU_4_Wakeup : 24|1@1+ (1,0) [0|1] "" Vector__XXX
 SG_ NM_DU_4_NM_aktiv_KL15 : 32|1@1+ (1,0) [0|1] "" Vector__XXX
 SG_ NM_DU_4_NM_aktiv_Diagnose : 33|1@1+ (1,0) [0|1] "" Vector__XXX
 SG_ NM_DU_4_NM_aktiv_Tmin : 34|1@1+ (1,0) [0|1] "" Vector__XXX
 SG_ NM_DU_4_NL_Dimmung : 48|1@1+ (1,0) [0|1] "" Vector__XXX
 SG_ NM_DU_4_UDS_CC : 63|1@1+ (1,0) [0|1] "" Vector__XXX

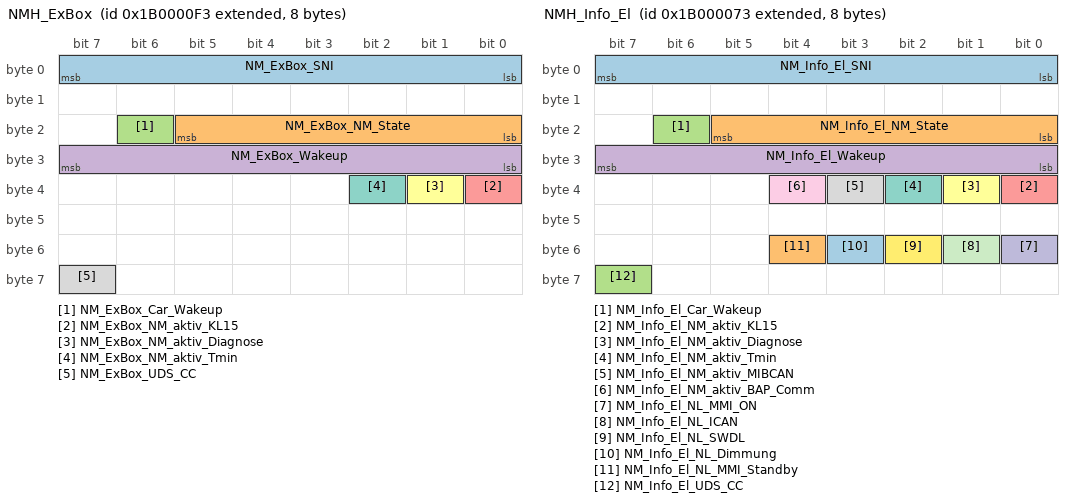
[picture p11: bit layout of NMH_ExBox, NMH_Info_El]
BO_ 2600468723 NMH_ExBox: 8 ExBox
 SG_ NM_ExBox_SNI : 0|8@1+ (1,0) [0|255] "" Vector__XXX
 SG_ NM_ExBox_NM_State : 16|6@1+ (1,0) [0|63] ""  ABT_1_MIB_ab_Gen3,ABT_1_MQB,BT_1_MQB,DU_1_MQB,DU_2,DU_3,DU_4,ExBox,Kombi_TT3,LSR_1,SCC1,SCC2,SDC1,SDC2,SFA,TVTuner_ab_Gen3_JPN,WLC_01,WLC_02,ZR_Entry,ZR_High,ZR_High_Korea,ZR_High_TT3,ZR_MIB_OPTION_ab_Gen3,ZR_MIB_TOP_ab_Gen3,ZR_Standard
 SG_ NM_ExBox_Car_Wakeup : 22|1@1+ (1,0) [0|1] "" Vector__XXX
 SG_ NM_ExBox_Wakeup : 24|8@1+ (1,0) [0|255] "" Vector__XXX
 SG_ NM_ExBox_NM_aktiv_KL15 : 32|1@1+ (1,0) [0|1] "" Vector__XXX
 SG_ NM_ExBox_NM_aktiv_Diagnose : 33|1@1+ (1,0) [0|1] "" Vector__XXX
 SG_ NM_ExBox_NM_aktiv_Tmin : 34|1@1+ (1,0) [0|1] "" Vector__XXX
 SG_ NM_ExBox_UDS_CC : 63|1@1+ (1,0) [0|1] "" Vector__XXX

BO_ 2600468595 NMH_Info_El: 8 ZR_Entry
 SG_ NM_Info_El_SNI : 0|8@1+ (1,0) [0|255] "" Vector__XXX
 SG_ NM_Info_El_NM_State : 16|6@1+ (1,0) [0|63] ""  ABT_1_MIB_ab_Gen3,ABT_1_MQB,BT_1_MQB,DU_1_MQB,DU_2,DU_3,DU_4,ExBox,Kombi_TT3,LSR_1,SCC1,SCC2,SDC1,SDC2,SFA,TVTuner_ab_Gen3_JPN,WLC_01,WLC_02,ZR_Entry,ZR_High,ZR_High_Korea,ZR_High_TT3,ZR_MIB_OPTION_ab_Gen3,ZR_MIB_TOP_ab_Gen3,ZR_Standard
 SG_ NM_Info_El_Car_Wakeup : 22|1@1+ (1,0) [0|1] "" Vector__XXX
 SG_ NM_Info_El_Wakeup : 24|8@1+ (1,0) [0|255] "" Vector__XXX
 SG_ NM_Info_El_NM_aktiv_KL15 : 32|1@1+ (1,0) [0|1] "" Vector__XXX
 SG_ NM_Info_El_NM_aktiv_Diagnose : 33|1@1+ (1,0) [0|1] "" Vector__XXX
 SG_ NM_Info_El_NM_aktiv_Tmin : 34|1@1+ (1,0) [0|1] "" Vector__XXX
 SG_ NM_Info_El_NM_aktiv_MIBCAN : 35|1@1+ (1,0) [0|1] "" Vector__XXX
 SG_ NM_Info_El_NM_aktiv_BAP_Comm : 36|1@1+ (1,0) [0|1] "" Vector__XXX
 SG_ NM_Info_El_NL_MMI_ON : 48|1@1+ (1,0) [0|1] "" Vector__XXX
 SG_ NM_Info_El_NL_ICAN : 49|1@1+ (1,0) [0|1] "" Vector__XXX
 SG_ NM_Info_El_NL_SWDL : 50|1@1+ (1,0) [0|1] "" Vector__XXX
 SG_ NM_Info_El_NL_Dimmung : 51|1@1+ (1,0) [0|1] "" Vector__XXX
 SG_ NM_Info_El_NL_MMI_Standby : 52|1@1+ (1,0) [0|1] "" Vector__XXX
 SG_ NM_Info_El_UDS_CC : 63|1@1+ (1,0) [0|1] "" Vector__XXX

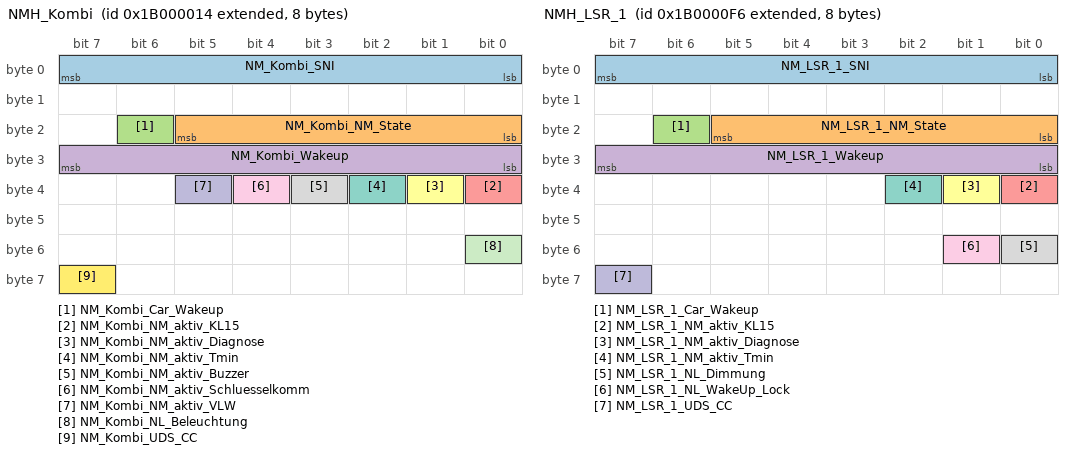
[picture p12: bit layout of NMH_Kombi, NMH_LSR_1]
BO_ 2600468500 NMH_Kombi: 8 Kombi_TT3
 SG_ NM_Kombi_SNI : 0|8@1+ (1,0) [0|255] "" Vector__XXX
 SG_ NM_Kombi_NM_State : 16|6@1+ (1,0) [0|63] ""  ABT_1_MIB_ab_Gen3,ABT_1_MQB,BT_1_MQB,DU_1_MQB,DU_2,DU_3,DU_4,ExBox,Kombi_TT3,LSR_1,SCC1,SCC2,SDC1,SDC2,SFA,TVTuner_ab_Gen3_JPN,WLC_01,WLC_02,ZR_Entry,ZR_High,ZR_High_Korea,ZR_High_TT3,ZR_MIB_OPTION_ab_Gen3,ZR_MIB_TOP_ab_Gen3,ZR_Standard
 SG_ NM_Kombi_Car_Wakeup : 22|1@1+ (1,0) [0|1] "" Vector__XXX
 SG_ NM_Kombi_Wakeup : 24|8@1+ (1,0) [0|255] "" Vector__XXX
 SG_ NM_Kombi_NM_aktiv_KL15 : 32|1@1+ (1,0) [0|1] "" Vector__XXX
 SG_ NM_Kombi_NM_aktiv_Diagnose : 33|1@1+ (1,0) [0|1] "" Vector__XXX
 SG_ NM_Kombi_NM_aktiv_Tmin : 34|1@1+ (1,0) [0|1] "" Vector__XXX
 SG_ NM_Kombi_NM_aktiv_Buzzer : 35|1@1+ (1,0) [0|1] "" Vector__XXX
 SG_ NM_Kombi_NM_aktiv_Schluesselkomm : 36|1@1+ (1,0) [0|1] "" Vector__XXX
 SG_ NM_Kombi_NM_aktiv_VLW : 37|1@1+ (1,0) [0|1] "" Vector__XXX
 SG_ NM_Kombi_NL_Beleuchtung : 48|1@1+ (1,0) [0|1] "" Vector__XXX
 SG_ NM_Kombi_UDS_CC : 63|1@1+ (1,0) [0|1] "" Vector__XXX

BO_ 2600468726 NMH_LSR_1: 8 LSR_1
 SG_ NM_LSR_1_SNI : 0|8@1+ (1,0) [0|255] "" Vector__XXX
 SG_ NM_LSR_1_NM_State : 16|6@1+ (1,0) [0|63] ""  ABT_1_MIB_ab_Gen3,ABT_1_MQB,BT_1_MQB,DU_1_MQB,DU_2,DU_3,DU_4,ExBox,Kombi_TT3,LSR_1,SCC1,SCC2,SDC1,SDC2,SFA,TVTuner_ab_Gen3_JPN,WLC_01,WLC_02,ZR_Entry,ZR_High,ZR_High_Korea,ZR_High_TT3,ZR_MIB_OPTION_ab_Gen3,ZR_MIB_TOP_ab_Gen3,ZR_Standard
 SG_ NM_LSR_1_Car_Wakeup : 22|1@1+ (1,0) [0|1] "" Vector__XXX
 SG_ NM_LSR_1_Wakeup : 24|8@1+ (1,0) [0|255] "" Vector__XXX
 SG_ NM_LSR_1_NM_aktiv_KL15 : 32|1@1+ (1,0) [0|1] "" Vector__XXX
 SG_ NM_LSR_1_NM_aktiv_Diagnose : 33|1@1+ (1,0) [0|1] "" Vector__XXX
 SG_ NM_LSR_1_NM_aktiv_Tmin : 34|1@1+ (1,0) [0|1] "" Vector__XXX
 SG_ NM_LSR_1_NL_Dimmung : 48|1@1+ (1,0) [0|1] "" Vector__XXX
 SG_ NM_LSR_1_NL_WakeUp_Lock : 49|1@1+ (1,0) [0|1] "" Vector__XXX
 SG_ NM_LSR_1_UDS_CC : 63|1@1+ (1,0) [0|1] "" Vector__XXX

BO_TX_BU_ 1725 : ZR_High,ZR_MIB_OPTION_ab_Gen3,ZR_MIB_TOP_ab_Gen3,ZR_Standard;
BO_TX_BU_ 2583885317 : ZR_High,ZR_MIB_OPTION_ab_Gen3,ZR_MIB_TOP_ab_Gen3,ZR_Standard;
BO_TX_BU_ 1471 : ZR_High_Korea,ZR_High_TT3,ZR_MIB_OPTION_ab_Gen3,ZR_MIB_TOP_ab_Gen3;
BO_TX_BU_ 2527679647 : ZR_High,ZR_High_Korea,ZR_MIB_OPTION_ab_Gen3,ZR_MIB_TOP_ab_Gen3,ZR_Standard;
BO_TX_BU_ 2600468721 : ABT_1_MIB_ab_Gen3,ABT_1_MQB;
BO_TX_BU_ 2600468595 : ZR_Entry,ZR_High,ZR_High_Korea,ZR_High_TT3,ZR_MIB_OPTION_ab_Gen3,ZR_MIB_TOP_ab_Gen3,ZR_Standard;
CM_ SG_ 2549088421 WLC1_KompSchutz "Funktionseinschränkung aufgrund Komponentenschutz aktiv";
CM_ SG_ 2549088421 WLC1_Abschaltstufe "Funktionseinschränkung aufgrund aktiver Abschaltstufe";
CM_ SG_ 2549088421 WLC1_Transport_Mode "Funktionseinschränkung aufgrund aktivem Transport Mode und/oder Transport Schutz";
CM_ SG_ 2549088421 WLC1_Nachlauftyp "Abgebildet wird die von der Hardware vorgegebene Möglichkeit, die Kommunikation nach Klemme 15 = AUS aufrecht zu erhalten. Es wird ein Init-Wert gesendet.
0 = Kommunikation nur bei KL15=EIN (kein Nachlauf, nicht weckfähig)
1 = Kommunikation nach KL15=AU";
CM_ SG_ 2549088421 WLC1_SNI "Das Signal beinhaltet den Source Node Identifier (Knotenadresse, die auch in der Abbildungsvorschrift zur CAN-ID für die NM-High Botschaft verwendet wird).";
CM_ SG_ 2549088421 WLC1_BusKnockOutTimer "Ausgabe des BusKnockOut-Timer in der Knotenbotschaft";
CM_ SG_ 2549088421 NM_WLC1_Wakeup "
    enth&#228;lt die Weckursache; stehen mehrere Weckursachen parallel an, dann 
    muss der kleinste Wert &#252;bertragen werden
  ";
CM_ SG_ 2549088421 NM_WLC1_Lokalaktiv "Zeigt an ob das SG nach Klemme15 AUS und nach entsprechender MAX Aktivzeit noch aktiv war";
CM_ SG_ 2549088422 WLC2_KompSchutz "Funktionseinschränkung aufgrund Komponentenschutz aktiv";
CM_ SG_ 2549088422 WLC2_Abschaltstufe "Funktionseinschränkung aufgrund aktiver Abschaltstufe";
CM_ SG_ 2549088422 WLC2_Transport_Mode "Funktionseinschränkung aufgrund aktivem Transport Mode und/oder Transport Schutz";
CM_ SG_ 2549088422 WLC2_Nachlauftyp "Abgebildet wird die von der Hardware vorgegebene Möglichkeit, die Kommunikation nach Klemme 15 = AUS aufrecht zu erhalten. Es wird ein Init-Wert gesendet.
0 = Kommunikation nur bei KL15=EIN (kein Nachlauf, nicht weckfähig)
1 = Kommunikation nach KL15=AU";
CM_ SG_ 2549088422 WLC2_SNI "Das Signal beinhaltet den Source Node Identifier (Knotenadresse, die auch in der Abbildungsvorschrift zur CAN-ID für die NM-High Botschaft verwendet wird).";
CM_ SG_ 2549088422 WLC2_BusKnockOutTimer "Ausgabe des BusKnockOut-Timer in der Knotenbotschaft";
CM_ SG_ 2549088422 NM_WLC2_Wakeup "enthält die Weckursache; stehen mehrere Weckursachen parallel an, dann muss der kleinste Wert übertragen werden";
CM_ SG_ 2549088422 NM_WLC2_Lokalaktiv "Zeigt an ob das SG nach Klemme15 AUS und nach entsprechender MAX Aktivzeit noch aktiv war";
CM_ SG_ 1720 KBI_Reifenumfang "Mittlerer Radumfang aus der K-Zahl gerechnet in Millimeter.  Byte 2 Bit 5,4 reserviert, Byte 2 Bit 3..0 und Byte 1 Bit 7..0; Wertebereich 0..4096 mm
";
CM_ SG_ 1720 KBI_Variante_USA "In diesem Signal wird die HW-Variante des Kombis ausgegeben, ACC plausibilisiert auf dieses Signal hin seine US-Codierung";
CM_ SG_ 1720 KBI_Variante "Zeigt an ob es sich um ein konventionelles Zeiger-Kombiinstrument handelt oder um eine Volldisplay-Kombiinstrument";
CM_ SG_ 1720 KBI_GAP_Warn_Zeit_abgelaufen "Die Zeit, z.B. 1460 Tage, bis zur finalen Warnstufe der Gasanlagenprüfung wurde berechnet. Berechnung erfolgt auf Basis der aktuellen Uhrzeit mit einem Tageszähler. Keine Berechnung des Zählers bei Kl.30 AUS.";
CM_ SG_ 1720 KBI_Quittierung_Naesse "Quittierungsbestätigung vom Fahrer";
CM_ SG_ 1720 KBI_BCmE_aktiv "Anzeige BCmE aktiv (BCmE-Screen oder Einsparhinweis in der Anzeige)";
CM_ SG_ 1720 KBI_Sparhinweis_quittiert "angezeigter Sparhinweis ist quittiert. Signal wird nach zwei Sendebotschaften wieder auf '0' gesetzt.";
CM_ SG_ 1720 KBI_Tankfuellstand_Prozent "Tankfüllstand in %";
CM_ SG_ 1720 KBI_Nachtanken_erkannt "Statusinformation Nachtankmodus";
CM_ SG_ 1720 KBI_Tankinhalt_hochaufl "angezeigter Tankinhalt hochauflösend zur Restreichweitenberechnung";
CM_ SG_ 1720 KBI_Max_Tankinhalt "Mitteilung des maximalen Tankinhalts an das Reichweitenmodul";
CM_ SG_ 1720 KBI_Reifenumfang_Sekundaer "Fahrzeuge mit unterschiedlichen Reifenumfängen Vorderachse / Hinterachse:

Primärachse: KBI_Reifenumfang
Sekundärachse: KBI_Reifenumfang_Sekundaer
";
CM_ SG_ 1720 KBI_Quittierung_cAQP "Quittierungsbestätigung vom Fahrer für Funktion cAQP";
CM_ SG_ 1725 KBI_Tankabgl_1 "Tankabgleichswert Kombi (Geber 1)
";
CM_ SG_ 1725 KBI_Tankabgl_2 "Tankabgleichswert Kombi (Geber 2)
";
CM_ SG_ 1725 KBI_Tankabgl_3 "Tankabgleichswert Kombi (Geber 3)

																		 
";
CM_ SG_ 1725 KBI_Fotosensor "Sonnenintensität Kombi";
CM_ SG_ 1725 KBI_KL58d "Kombi-Display-Dimmung
";
CM_ SG_ 1725 KBI_KL58s "Auffindbeleuchtung 
Jede Änderung löst OnChange Versand aus!
";
CM_ SG_ 1725 KBI_B_accscreen "ACC_Screen im Kombi aktivieren/deaktivieren
";
CM_ SG_ 1725 KBI_Uebern "Zeit im Gateway übernehmen
";
CM_ SG_ 1725 KBI_Uhr_Verstellung "Eine Uhrzeitverstellung im Kombi erfordert eine sofortige Übernahme der Zeit im Gateway (ausserhalb der Synchronisation beim Übergang von 29 nach 30 Sek.) ";
CM_ SG_ 2527679493 KBI_Req_TID "Transaktions ID 
0x0: Init / Aktion ohne Request
0x1- 0xF: Gültige TIDs für Request";
CM_ SG_ 2527679493 KBI_LVDS_Lock "Dient zur Synchronisation der Anzeige zwischen Kombi und ZR";
CM_ SG_ 2527679493 KBI_Req_Lastmode "0 =  KBI_Req_MainContext wird ganz normal als Request interpretiert
1 =  KBI_Req_MainContext ist lediglich als Lastmode-Info zu interpretieren
";
CM_ SG_ 2527679493 KBI_Req_Focus "Mit dem Focus teilt das Kombi der Head-Unit mit, wer für den neu angeforderten Screen die Tasten auswerten soll (Tastenfocus).";
CM_ SG_ 2527679493 KBI_Req_ScreenFormat "Geforderter Anzeigeview im Kombi-Display";
CM_ SG_ 2527679493 KBI_Req_MainContext "Rückspiegelung Aktueller bzw aktuell geforderter Hauptcontext an MainUnit
0x00 = keine Anzeige / Init 0x10 = Navi
0x20 = Media / Radio
0x30 = Telefon
0x50 = Klangeinstellung
0x60 = Apps
0x70 = Connect / Office
0x81 = CAR-360°-View
0x82 = CAR-Favor";
CM_ SG_ 2527679493 KBI_Req_PopupContext "Liefert aktuell überlagerte Popup Anzeigen, falls vorhanden
0x00 = kein Pop-Up gefordert
0x2x = geöffnete Audio-Statusleiste 
0x3x = geöffnete Telefon-Statusleiste 
0x46 = teilflächiger Pop-Up hochprior Typ A
0x47 = teilflächiger Pop-Up hochprior Typ";
CM_ SG_ 2527679493 KBI_Req_MenuContext "Mittels MenuContext übermittelt das Kombi dem MMI, wie für den angeforderten Main- oder auch Popup-Kontext die Seitenmenüs bzw. das Audio-Menü angefordert werden";
CM_ SG_ 2527679493 KBI_Req_Animation_Screen_SubType "Anzeige Animationssubtyp";
CM_ SG_ 2527679493 KBI_Req_Animation_Screen_Type "Anzeige Animationstyp";
CM_ SG_ 2527679493 KBI_Req_Animation_Lead_Time "Animationszeit für Animationssynchronisation";
CM_ SG_ 2527679493 KBI_Req_Animation_Add_Info "Animationsinformation";
CM_ SG_ 2527679492 KBI_Sta_TID "Transaktions ID 
0x0: Init / Aktion ohne Request
0x1- 0xF: Gültige TIDs für Request";
CM_ SG_ 2527679492 KBI_Sta_Animation "0x0 = Faktor 1 (normale Animationsgeschwindigkeit) (dreifache Animationsgeschwindigkeit)
0x1 = Faktor 1,25 
0x2 = Faktor 1,5 
0x3 = Faktor 1,75 
0x4 = Faktor 2 (doppelte Animationsgeschwindigkeit)
0x5 = Faktor 2,25 
0x6 = Faktor 2,5 
0x7 = Faktor 2";
CM_ SG_ 2527679492 KBI_Sta_Focus "Anzeige der Bedienhoheit im Kombi-Display";
CM_ SG_ 2527679492 KBI_Sta_ScreenFormat "Geforderter Anzeigeview im Kombi-Display";
CM_ SG_ 2527679492 KBI_Sta_MainContext "Aktueller bzw aktuell geforderter Hauptcontext.
0x00 = keine Anzeige / Init 
0x10 ¿ 0x1F = Navi
0x20 ¿ 0x2F = Media / Radio
0x30 ¿ 0x3F = Telefon
0x40 ¿ 0x45 = vollflächiger PopUp 
0x4A = Entwicklerframe MMI
0x4B = SW-Download-Frame MMI
0x50 ¿ 0x5";
CM_ SG_ 2527679492 KBI_Sta_PopupContext "Liefert aktuell überlagerte Popup Anzeigen, falls vorhanden
0x00 = kein Pop-Up vorhanden
0x01 = Kombi-PopUp
0x02 ... 0XFF = MMI-PopUp (MMI-PopUp-ID)";
CM_ SG_ 2527679492 KBI_Sta_MenuContext "Gibt das angezeigte Menu wieder";
CM_ SG_ 2527679492 KBI_Sta_Animation_Screen_SubType "Anzeige Animationssubtyp";
CM_ SG_ 2527679492 KBI_Sta_Animation_Screen_Type "Anzeige Animationstyp";
CM_ SG_ 2527679492 KBI_Sta_Animation_Lead_Time "Animationszeit zur Anzeigesynchronisation";
CM_ SG_ 2527679492 KBI_Sta_Animation_Add_Info "Animationsinformation";
CM_ SG_ 2527679502 KBI_Popup_TID "Die Transaction-ID (TID) in der Botschaft KombiPopUpStatus enthält die TID der Anforderung über MMIPopUpRequest";
CM_ SG_ 2527679502 KBI_Popup_MMIPopupState "Dieses Signal kennzeichnet den Status des jeweiligen PopUps. ";
CM_ SG_ 2527679502 KBI_Popup_MMIPopupID "Die MMI_PopupID kennzeichnet eindeutig den PopUp lt. Head-Unit Nomenklatur. ";
CM_ SG_ 2527679502 KBI_Popup_MMIPopupPriority "Mit MMI_PopupPriority spiegelt nochmal die zuletzt angeforderte Priorität zur PopUp-ID lt. MMI_PopUp_ID zurück.";
CM_ SG_ 2527679502 KBI_Popup_ZPMSlotID "Mit ZPM_SlotID spiegelt das Kombi nochmal die zuletzt für den PopUp-ID lt. MMI_PopUp_ID angeforderte Slot-ID zurück.";
CM_ SG_ 2527679502 KBI_Popup_ScreenFormat "Geforderter Anzeigeview im Kombi-Display";
CM_ SG_ 2527679502 KBI_Popup_Focus "Signal gibt den angemeldeten Tastenfocus zum Popup an.";
CM_ SG_ 2549899278 KS_SSN_ABT_1_Req_Data "Kompontenschutz DK2 ABT1";
CM_ SG_ 2550030350 KS_SSN_ABT_1_Resp_Data "Komponentenschutz DK2 ABT";
CM_ SG_ 1148 LSR_Variant "Identifiziert die Variante des MMI-Bedienteils";
CM_ SG_ 1148 LSR_DKM_Kurzschluss_GND "Drehkinematik Fehler - Rechte oder Linke Seite an GND kurzgeschlossen";
CM_ SG_ 1148 LSR_DKM_Kurzschluss_Ubat "Drehkinematik Fehler - Rechte oder Linke Seite an Ubat kurzgeschlossen";
CM_ SG_ 1148 LSR_SW_inkonsistent "SW_inkonsistent= 1 SW Status ist inkonsistent - Fehler
SW_inkonsistent = 0 kien Fehler - SW ist konsistent";
CM_ SG_ 1148 LSR_DKM_Kurzschluss_Unterbrec000 "Drehkinematik Fehler- Unterbrechung der Motorleitung
Bürsten abgenutzt; Bedingung: Minimalstrom wird nicht erreicht";
CM_ SG_ 1148 LSR_DKM_k_Hallsignal "Drehkinematik Fehler- Mechanik Blockade / kein Hallsignal";
CM_ SG_ 1148 LSR_DKM_Ueberlastung "Drehkinematik Fehler- Motor-Übertemperatur
Schwergängigkeit, zu häufige Benutzung";
CM_ SG_ 1148 LSR_DKM_Mech_Flauf "Drehkinematik Fehler - Mechanischer Fehler: Gerissenes Seil, Zahnrad lose auf Achse, etc.";
CM_ SG_ 1148 LSR_DKM_El_Fehler "Drehkinematik Fehler - Kurzschluss Motorleitung";
CM_ SG_ 1148 LSR_DKM_Manual_Operation "(1) Der Benutzer hat am ausgefahrenen Display gedrückt und die DKM fährt selbsttätig ein. !!! Spec Änderung: Display fährt selber ein !!!
(2) Der Benutzer hat das eingefahrene Display berührt und die DKM fährt selbsttätig aus. !!! Vorhalt für zukünftige ";
CM_ SG_ 2583754245 LSR_1_SWDL_Req_Data "Softwaredownload über ISO TP.";
CM_ SG_ 2583885317 LSR_1_SWDL_Resp_Data "Softwaredownload über ISO TP.";
CM_ SG_ 1471 MFL_Tastencode_1 "Beschreibt die Funktion einer fest zugeordneten Taste/Walze auf dem MFL. Bei Betätigung ändert sich der Wert von 0x0 auf den jeweiligen Tastencode.";
CM_ SG_ 1471 MFL_Tastencode_2 "Beschreibt die Funktion einer fest zugeordneten Taste/Walze auf dem MFL. Ist MFL_Tastencode_1 wegen Betätigung einer Taste/Walze bereits mit einem Wert ungleich 0x0 belegt, so ändert sich bei Betätigung einer weiteren Taste/Walze der Wert dieses Signals v";
CM_ SG_ 1471 MFL_Eventcode_1 "Siehe Q-LAH MFL-Protokoll";
CM_ SG_ 1471 MFL_Eventcode_2 "Siehe Q-LAH MFL-Protokoll";
CM_ SG_ 1471 MFL_Variante "Markenspezifische Variantennummer des MFL";
CM_ SG_ 2527679491 ZR_Req_TID "Transaktions ID 
0x0: Init / Aktion ohne Request
0x1- 0xF: Gültige TIDs für Request";
CM_ SG_ 2527679491 ZR_Req_Quit_Info "Signalisierung ob zusätzliche Quittierung zum Kontext/PopUp-Request gefordert ist";
CM_ SG_ 2527679491 ZR_Req_Focus "Mit dem Focus teilt die Head-Unit dem Kombi mit, wer für den neu angeforderten Screen die Tasten auswerten soll (Tastenfocus).";
CM_ SG_ 2527679491 ZR_Req_ScreenFormat "Feedback Anzeigeview für Kombi-Display";
CM_ SG_ 2527679491 ZR_Req_MainContext "Aktueller bzw aktuell geforderter Hauptcontext.
0x00 = keine Anzeige (Init bzw. Kombi-Display aus)
0x10 = Navi
0x20 = Media / Radio
0x30 = Telefon
0x41 = Vollflächiger Pop-Up (mittlere Prio) 
0x42 = Vollflächiger Pop-Up (niedrige Prio) 
0x4A = Entw";
CM_ SG_ 2527679491 ZR_Req_PopupContext "Quittierwunsch wird normal über ZR_Req_Quit_Info gesteuert
0x00 = kein Pop-Up vorhanden
0x01 = Kombi-PopUp in Verbindung mit Kontextwechselanforderung beibehalten
0x02 = MMI-PopUp in Verbindung mit Kontextwechselanforderung beibehalten
0x41 = Vollf. P";
CM_ SG_ 2527679491 ZR_Req_MenuContext "Mittels MenuContext übermittelt die Headunit (MMI) dem Kombi, wie für den angeforderten Main- oder auch Popup-Kontext die Seitenmenüs bzw. das Audio-Menü angefordert werden.";
CM_ SG_ 2527679490 ZR_Sta_TID "Transaktions ID 
											   
0x0: Init / Aktion ohne Request
0x1- 0xF: Gültige TIDs für Request";
CM_ SG_ 2527679490 ZR_Sta_Animation "0x0 = Faktor 1 (normale Animationsgeschwindigkeit) (dreifache Animationsgeschwindigkeit)
0x1 = Faktor 1,25 
0x2 = Faktor 1,5 
0x3 = Faktor 1,75 
0x4 = Faktor 2 (doppelte Animationsgeschwindigkeit)
0x5 = Faktor 2,25 
0x6 = Faktor 2,5 
0x7 = Faktor 2";
CM_ SG_ 2527679490 ZR_Sta_Focus "Der Focus im MMIDisplayStatus teilt dem Kombi mit, mit welchem (Tasten-)Focus das MMI gerade arbeitet. ";
CM_ SG_ 2527679490 ZR_Sta_ScreenFormat "Feedback Anzeigeview für Kombi-Display";
CM_ SG_ 2527679490 ZR_Sta_MainContext "Aktueller bzw aktuell geforderter Hauptcontext.
0x00 = keine Anzeige / Init
0x10 = Navi
0x20 = Media / Radio
0x30 = Telefon
0x40 ¿ 0x45 = vollflächiger PopUp 
0x4A = Entwicklerframe MMI
0x4B = SW-Download-Frame MMI
0x50 = Klangeinstellung
0x60 = ";
CM_ SG_ 2527679490 ZR_Sta_PopupContext "Liefert aktuell überlagerte Popup Anzeigen, falls vorhanden
0x00 = kein Pop-Up vorhanden
0x01 = Kombi PopUp";
CM_ SG_ 2527679490 ZR_Sta_MenuContext "Mittels MenuContext übermittelt die Headunit (MMI) dem Kombi den aktuellen Status der Seiten- bzw. des Audiomenüs.";
CM_ SG_ 2527679490 ZR_Sta_AnimationInfo "Fortschritt der aktuell laufenden Hauptanimation";
CM_ SG_ 2527679490 ZR_Sta_KDKOpacity "Transparenzfaktor für KDK-Ausstanzung in Kombitube.";
CM_ SG_ 2527679490 ZR_Sta_KDK_PosInfo "Position der KDK in Abhängigkeit große/kleine Bühne.";
CM_ SG_ 2527679490 ZR_Sta_NavBargraph "Info ob Navi-Bargraph aktiv ist.";
CM_ SG_ 2527679490 ZR_Sta_KDK "Info ob KDK aktiv ist oder nicht";
CM_ SG_ 2527679501 ZR_Popup_TID "Die Transaction-ID (TID) im MMIPopupRequest dient der späteren Zuordenbarkeit der Antwort vom Kombi (im KombiPopupStatus)";
CM_ SG_ 2527679501 ZR_Popup_MMIPopupReqState "Dieses Signal kennzeichnet, ob der PopUp angefordert oder gelöscht (zurückgenommen) werden soll.";
CM_ SG_ 2527679501 ZR_Popup_MMIIDReq "Die MMI_PopupID_Req kennzeichnet eindeutig den von der Head-Unit angeforderten PopUp";
CM_ SG_ 2527679501 ZR_Popup_MMIPopupPriorityReq "Mit MMI_PopupPriority_Req gibt das MMI die Priorität an, mit der ein Popup für den Slot angefordert wird.";
CM_ SG_ 2527679501 ZR_Popup_ZPMSlotIDReq "Das Signal ZPM_SlotID_Req bestimmt, als welcher Typ und mit welcher globalen Priorität der PopUp
im Zentralen-Prio-Manager angemeldet wird. Der Slot-ID wird vom Kombi auf die für das MMI reservierten ZPM-ID's gemappt.
0=ungültige Anforderung";
CM_ SG_ 2527679501 ZR_Popup_ScreenFormat "Geforderter Anzeigeview im Kombi-Display";
CM_ SG_ 2527679501 ZR_Popup_Focus "Signal stellt den benötigten Tastenfocus für den angemeldeten Popup dar.";
CM_ SG_ 2527679499 ZR_Sta_360_View "Info von ZR an Kombi ob 360_View Auswahlmenü im Konfigurationsstatus des Fzg anwählbar ist.";
CM_ SG_ 2527679499 ZR_Sta_Favoriten "Info von ZR an Kombi ob Favoriten Auswahlmenü im Konfigurationsstatus des Fzg anwählbar ist.";
CM_ SG_ 2527679499 ZR_Sta_Laden "Info von ZR an Kombi ob Laden Auswahlmenü im Konfigurationsstatus des Fzg anwählbar ist.";
CM_ SG_ 2527679499 ZR_Sta_FAS "Info von ZR an Kombi ob FAS  Auswahlmenü im Konfigurationsstatus des Fzg anwählbar ist.";
CM_ SG_ 2527679499 ZR_Sta_Fzg_Einst "Info von ZR an Kombi ob Fahrzeug Einstellungen Auswahlmenü im Konfigurationsstatus des Fzg anwählbar ist.";
CM_ SG_ 2527679499 ZR_Sta_Klima "Info von ZR an Kombi ob Klima Auswahlmenü im Konfigurationsstatus des Fzg anwählbar ist.";
CM_ SG_ 2527679499 ZR_Sta_Standhzg "Info von ZR an Kombi ob Standheizung Auswahlmenü im Konfigurationsstatus des Fzg anwählbar ist.";
CM_ SG_ 2527679499 ZR_Sta_Service "Info von ZR an Kombi ob Service Auswahlmenü im Konfigurationsstatus des Fzg anwählbar ist.";
CM_ SG_ 2527679499 ZR_Sta_Fahrprofil "Info von ZR an Kombi ob Fahrprofil Auswahlmenü im Konfigurationsstatus des Fzg anwählbar ist.

--> Signal ersetzt ZR_Sta_Statistik";
CM_ SG_ 2527679499 ZR_Sta_Race "Info von ZR an Kombi ob Race Auswahlmenü im Konfigurationsstatus des Fzg anwählbar ist.";
CM_ SG_ 2527679499 ZR_Sta_Office "Info von ZR an Kombi ob Office Auswahlmenü im Konfigurationsstatus des Fzg anwählbar ist.";
CM_ SG_ 2527679499 ZR_Sta_Bordbuch "Info von ZR an Kombi, ob die Funktion zur Anzeige in Menüs verbaut und verfügbar ist.";
CM_ SG_ 2527679499 ZR_Sta_Profile "Info von ZR an Kombi ob Profile Auswahlmenü im Konfigurationsstatus des Fzg anwählbar ist";
CM_ SG_ 2527679499 ZR_Sta_Connect "Info von ZR an Kombi ob Connect Auswahlmenü im Konfigurationsstatus des Fzg anwählbar ist";
CM_ SG_ 2527679499 ZR_Sta_Klang "Info von ZR an Kombi ob Klang Auswahlmenü im Konfigurationsstatus des Fzg anwählbar ist";
CM_ SG_ 2527679499 ZR_Sta_Systemeinst "Info von ZR an Kombi ob Systemeinstellung Auswahlmenü im Konfigurationsstatus des Fzg anwählbar ist.";
CM_ SG_ 2527679499 ZR_Sta_ConnectivityManager "Info von ZR an Kombi, ob die Funktion zur Anzeige in Menüs verbaut und verfügbar ist.";
CM_ SG_ 2527679499 ZR_Sta_ETC "Info von ZR an Kombi ob ETC Auswahlmenü im Konfigurationsstatus des Fzg anwählbar ist";
CM_ SG_ 2527679499 ZR_Sta_SmartPhone "Info von ZR an Kombi ob SmartPhone im Konfigurationsstatus des Fzg anwählbar ist";
CM_ SG_ 2527679499 ZR_Sta_B_Call "Info von ZR an Kombi ob B-Call Auswahlmenü im Konfigurationsstatus des Fzg anwählbar ist";
CM_ SG_ 2527679499 ZR_Sta_C_Call "Info von ZR an Kombi ob C-Call Auswahlmenü im Konfigurationsstatus des Fzg anwählbar ist";
CM_ SG_ 2527679499 ZR_Sta_VICS "Info von ZR an Kombi ob VICS Auswahlmenü im Konfigurationsstatus des Fzg anwählbar ist";
CM_ SG_ 2527679499 ZR_Sta_TPEG "Info von ZR an Kombi ob TPEG Auswahlmenü im Konfigurationsstatus des Fzg anwählbar ist";
CM_ SG_ 1156 ND_VDOP "vertical dilution of precision (Vertikalrichtung, 1D)
";
CM_ SG_ 1156 ND_TDOP "time dilution of precision (Zeitgenauigkeit)
";
CM_ SG_ 1156 ND_HDOP "horizontal dilution of precision (Horizontalrichtung, 2D)
";
CM_ SG_ 1156 ND_GDOP "geometric dilution of precision (Gesamtgenauigkeit, 3D und Zeit) 
";
CM_ SG_ 1156 ND_PDOP "positional dilution of precision (Positionsgenauigkeit, 3D) 
";
CM_ SG_ 1156 ND_Heading "Fahrtrichtung";
CM_ SG_ 1156 ND_Init "Initialisierung";
CM_ SG_ 1157 ND_SatInUse "Anzahl der zur Berechnung verwendeten Satelliten";
CM_ SG_ 1157 POS_Guete_horizontal_verfuegbar "Bei gesetztem Bit wird das Signal POS_Guete_horizontal befüllt und ist verfügbar.";
CM_ SG_ 1157 ND_SatInView "Anzahl der sichtbaren Satelliten";
CM_ SG_ 1157 POS_Guete_horizontal "Horizontale Genauigkeit der Position in der Botschaft NavPos_02_MapMatched (Signale
POS_LatDegree, POS_LongDegree)

Abhängig vom Signal
POS_Guete_horizontal_verfuegbar";
CM_ SG_ 1157 NP_Altitude "Hoehe ueber NN
0xFFF = Fehler bei der Berechnung der Höhe über NN";
CM_ SG_ 1157 ND_UTC "UTC-Zeit, verstrichene Sekunden seit 01.01.1970 00:00
0xFFFFFFFE = Init
0xFFFFFFFF = Fehler bei Berechnung der UTC-Time";
CM_ SG_ 1158 NP_LatDegree "Latitude (Nord-Süd Wert)";
CM_ SG_ 1158 NP_LongDegree "Longitude (Ost-West Wert)";
CM_ SG_ 1158 NP_LatDirection "Hemisphäre Nord/Süd";
CM_ SG_ 1158 NP_LongDirection "Hemisphäre Ost/West";
CM_ SG_ 1158 NP_Sat "Nummer der verwendeten Sateliten beim letzten Fix";
CM_ SG_ 2589283496 POS_MUX "Multiplex-Signal zum schalten des Signals der Positionen von der Navigation.
MUX(0/1)";
CM_ SG_ 2589283496 POS_ODD_EVEN "Synchronisation der MUX Pos Signale
MUX(0/1)";
CM_ SG_ 2589283496 POS_PosStati "Aktueller Status der Navgation:
MUX(0)
0   init
1   no nav available (ready_4_nav)
2   no map available (sd_removed, not_enabled)
3   nav booting
4   nav error
5   nav calibrating
6   nav no gps resync since 1h
7   nav offroad  parkgarage ramp of";
CM_ SG_ 2589283496 POS_Heading "Heading of current position
MUX(1)";
CM_ SG_ 2589283496 POS_LatDirection "latitude direction nav position
MUX(0)";
CM_ SG_ 2589283496 POS_LatDegree "latitude - position data of navigation
MUX(0)";
CM_ SG_ 2589283496 POS_Last_GPS_Sync "Letztes bekannte GPS Sync in [s]
MUX(1)";
CM_ SG_ 2589283496 POS_Heading_Trust "Vertrauenswert Heading 
MUX(1) ";
CM_ SG_ 2589283496 POS_UTC_REF "Zeitstempel der Nav
MUX(1)

UTC-Zeit, verstrichene Sekunden seit 01.01.1970 00:00
0xFFFFFFFE = Init
0xFFFFFFFF = Fehler bei Berechnung der UTC-Time";
CM_ SG_ 2589283496 POS_LongDirection "longitude direction nav position
MUX(0)";
CM_ SG_ 2589283496 POS_LongDegree "long - position data of navigation
MUX(0)";
CM_ SG_ 2527679647 Stellgliedtest_NFC "Applikationssignal um NFC Stellgliedtest abzubilden";
CM_ SG_ 2527679647 NFC_ESM_aktivieren "Energiesparmodus aktivieren, da z.B. Batterie kritisch";
CM_ SG_ 2527679647 ZV_auf_NFC "ZV Schliessstelle";
CM_ SG_ 2527679647 ZV_zu_NFC "ZV Schliessstelle";
CM_ SG_ 2527679647 MDK_Anf_Start_Auth "Anforderung vom MDK, um die Authentifizierung für den Motorstart zu triggern.";
CM_ SG_ 2527679647 MDK_BTLE_Spielschutz_aktivieren "Aktivierung Spielschutz Richtung BTLE-TrM";
CM_ SG_ 2527679647 MDK_NFC_Spielschutz_aktivieren "Aktivierung Spielschutz Richtung NFC-STGs";
CM_ SG_ 2527679647 NFC_Front_Verr_Authorisiert "Erkennung / Authorisierung NFC-Handy Front";
CM_ SG_ 2527679647 NFC_Front_Entr_Authorisiert "Erkennung / Authorisierung NFC-Handy Front";
CM_ SG_ 2527679647 NFC_HD_Verriegelung_Authorisiert "Autorisierung der Schließanforderung über NFC-Handy";
CM_ SG_ 2527679647 NFC_HD_Entriegelung_Authorisiert "Erkennung / Authorisierung NFC-Handy Heck";
CM_ SG_ 2527679647 NFC_aktiv "NFC-Gerät erkannt";
CM_ SG_ 2527679647 NFC_Laden_unterbrechen "Kommunikation zur Phonebox, das Laden zu unterbrechen";
CM_ SG_ 2527679647 NFC_FT_Entriegelung_Authorisiert "Erkennung / Authorisierung NFC-Handy FT
";
CM_ SG_ 2527679647 NFC_FT_Verriegelung_Authorisiert "Authorisierung Verriegelungssensor NFC-Handy FT";
CM_ SG_ 2600468721 NM_ABT_1_SNI "Source Node-Identifier (SNI) identifiziert den Sender der NM-Botschaft (Knotenadresse) eindeutig im Fahrzeug";
CM_ SG_ 2600468721 NM_ABT_1_NM_State "1 = Zustand Repeat Message (<-- Bus-Sleep Mode)
2 = Zustand Repeat Message (<-- Prepare Bus-Sleep Mode)
4 = Zustand Normal Operation (<-- Repeat Message)
8 = Zustand Normal Operation (<-- Ready Sleep)";
CM_ SG_ 2600468721 NM_ABT_1_Car_Wakeup "Car Wakeup (Gateway wertet aus)
";
CM_ SG_ 2600468721 NM_ABT_1_Wakeup "enthält die Weckursache; stehen mehrere Weckursachen parallel an, dann muss der kleinste Wert übertragen werden
";
CM_ SG_ 2600468721 NM_ABT_1_NM_aktiv_KL15 "Steuergerät hat KL15-EIN erkannt";
CM_ SG_ 2600468721 NM_ABT_1_NM_aktiv_Diagnose "Diagnose befindet sich nach VW80124 in einer NonDefaultDiagnostic-Session, z.B. ExtendedDiagnostic-Session";
CM_ SG_ 2600468721 NM_ABT_1_NM_aktiv_Tmin "Mindestaktivzeit ist noch nicht abgelaufen (bei jedem Weckereignis wird die Mindestaktivzeit neu gestartet)";
CM_ SG_ 2600468721 NM_ABT_1_NL_Dimmung "lokale / interne Aktivität vor WakeUp: Dimmung aktiv";
CM_ SG_ 2600468721 NM_ABT_1_NL_WakeUp_Lock "lokale / interne Aktivität vor WakeUp:
HID ist aufgrund des Transportmodus, Q_critical oder WU_lock gesperrt.";
CM_ SG_ 2600468721 NM_ABT_1_UDS_CC "Funktionseinschränkung aufgrund aktivem UDS-Communication Control; siehe VW80124";
CM_ SG_ 2600468720 NM_BT_1_SNI "Source Node-Identifier (SNI) identifiziert den Sender der NM-Botschaft (Knotenadresse) eindeutig im Fahrzeug";
CM_ SG_ 2600468720 NM_BT_1_NM_State "1 = Zustand Repeat Message (<-- Bus-Sleep Mode)
																					 
2 = Zustand Repeat Message (<-- Prepare Bus-Sleep Mode)
4 = Zustand Normal Operation (<-- Repeat Message)
8 = Zustand Normal Operation (<-- Ready Sleep)";
CM_ SG_ 2600468720 NM_BT_1_Car_Wakeup "Car Wakeup (Gateway wertet aus)
																													  
																																				   
";
CM_ SG_ 2600468720 NM_BT_1_Wakeup "enthält die Weckursache; stehen mehrere Weckursachen parallel an, dann muss der kleinste Wert übertragen werden

																	  
";
CM_ SG_ 2600468720 NM_BT_1_NM_aktiv_KL15 "Steuergerät hat KL15-EIN erkannt";
CM_ SG_ 2600468720 NM_BT_1_NM_aktiv_Diagnose "Diagnose befindet sich nach VW80124 in einer NonDefaultDiagnostic-Session, z.B. ExtendedDiagnostic-Session";
CM_ SG_ 2600468720 NM_BT_1_NM_aktiv_Tmin "Mindestaktivzeit ist noch nicht abgelaufen (bei jedem Weckereignis wird die Mindestaktivzeit neu gestartet)";
CM_ SG_ 2600468720 NM_BT_1_NL_Dimmung "lokale / interne Aktivität vor WakeUp: Dimmung aktiv";
CM_ SG_ 2600468720 NM_BT_1_NL_WakeUp_Lock "lokale / interne Aktivität vor WakeUp:
HID ist aufgrund des Transportmodus, Q_critical oder WU_lock gesperrt.";
CM_ SG_ 2600468720 NM_BT_1_UDS_CC "Funktionseinschränkung aufgrund aktivem UDS-Communication Control; siehe VW80124";
CM_ SG_ 2600468722 NM_DU_1_SNI "Source Node-Identifier (SNI) identifiziert den Sender der NM-Botschaft (Knotenadresse) eindeutig im Fahrzeug";
CM_ SG_ 2600468722 NM_DU_1_NM_State "1 = Zustand Repeat Message (<-- Bus-Sleep Mode)
																					
2 = Zustand Repeat Message (<-- Prepare Bus-Sleep Mode)
4 = Zustand Normal Operation (<-- Repeat Message)
8 = Zustand Normal Operation (<-- Ready Sleep)";
CM_ SG_ 2600468722 NM_DU_1_Car_Wakeup "Car Wakeup (Gateway wertet aus)
";
CM_ SG_ 2600468722 NM_DU_1_Wakeup "enthält die Weckursache; stehen mehrere Weckursachen parallel an, dann muss der kleinste Wert übertragen werden";
CM_ SG_ 2600468722 NM_DU_1_NM_aktiv_KL15 "Steuergerät hat KL15-EIN erkannt";
CM_ SG_ 2600468722 NM_DU_1_NM_aktiv_Diagnose "Diagnose befindet sich nach VW80124 in einer NonDefaultDiagnostic-Session, z.B. ExtendedDiagnostic-Session";
CM_ SG_ 2600468722 NM_DU_1_NM_aktiv_Tmin "Mindestaktivzeit ist noch nicht abgelaufen (bei jedem Weckereignis wird die Mindestaktivzeit neu gestartet)";
CM_ SG_ 2600468722 NM_DU_1_NL_Dimmung "lokale / interne Aktivität vor WakeUp: Dimmung aktiv";
CM_ SG_ 2600468722 NM_DU_1_UDS_CC "Funktionseinschränkung aufgrund aktivem UDS-Communication Control; siehe VW80124";
CM_ SG_ 2600468725 NM_DU_2_SNI "Source Node-Identifier (SNI) identifiziert den Sender der NM-Botschaft (Knotenadresse) eindeutig im Fahrzeug";
CM_ SG_ 2600468725 NM_DU_2_NM_State "1 = Zustand Repeat Message (<-- Bus-Sleep Mode)
2 = Zustand Repeat Message (<-- Prepare Bus-Sleep Mode)
4 = Zustand Normal Operation (<-- Repeat Message)
8 = Zustand Normal Operation (<-- Ready Sleep)";
CM_ SG_ 2600468725 NM_DU_2_Car_Wakeup "Car Wakeup (Gateway wertet aus)
";
CM_ SG_ 2600468725 NM_DU_2_Wakeup "enthält die Weckursache; stehen mehrere Weckursachen parallel an, dann muss der kleinste Wert übertragen werden";
CM_ SG_ 2600468725 NM_DU_2_NM_aktiv_KL15 "Steuergerät hat KL15-EIN erkannt";
CM_ SG_ 2600468725 NM_DU_2_NM_aktiv_Diagnose "Diagnose befindet sich nach VW80124 in einer NonDefaultDiagnostic-Session, z.B. ExtendedDiagnostic-Session";
CM_ SG_ 2600468725 NM_DU_2_NM_aktiv_Tmin "Mindestaktivzeit ist noch nicht abgelaufen (bei jedem Weckereignis wird die Mindestaktivzeit neu gestartet)";
CM_ SG_ 2600468725 NM_DU_2_NL_Dimmung "lokale / interne Aktivität vor WakeUp: Dimmung aktiv";
CM_ SG_ 2600468725 NM_DU_2_UDS_CC "Funktionseinschränkung aufgrund aktivem UDS-Communication Control; siehe VW80124";
CM_ SG_ 2600468734 NM_DU_3_SNI "Source Node-Identifier (SNI) identifiziert den Sender der NM-Botschaft (Knotenadresse) eindeutig im Fahrzeug";
CM_ SG_ 2600468734 NM_DU_3_NM_State "1 = Zustand Repeat Message (<-- Bus-Sleep Mode)
2 = Zustand Repeat Message (<-- Prepare Bus-Sleep Mode)
4 = Zustand Normal Operation (<-- Repeat Message)
8 = Zustand Normal Operation (<-- Ready Sleep)";
CM_ SG_ 2600468734 NM_DU_3_Car_Wakeup "Car Wakeup (Gateway wertet aus)
";
CM_ SG_ 2600468734 NM_DU_3_Wakeup "enthält die Weckursache; stehen mehrere Weckursachen parallel an, dann muss der kleinste Wert übertragen werden";
CM_ SG_ 2600468734 NM_DU_3_NM_aktiv_KL15 "Steuergerät hat KL15-EIN erkannt";
CM_ SG_ 2600468734 NM_DU_3_NM_aktiv_Diagnose "Diagnose befindet sich nach VW80124 in einer NonDefaultDiagnostic-Session, z.B. ExtendedDiagnostic-Session";
CM_ SG_ 2600468734 NM_DU_3_NM_aktiv_Tmin "Mindestaktivzeit ist noch nicht abgelaufen (bei jedem Weckereignis wird die Mindestaktivzeit neu gestartet)";
CM_ SG_ 2600468734 NM_DU_3_NL_Dimmung "lokale / interne Aktivität vor WakeUp: Dimmung aktiv";
CM_ SG_ 2600468734 NM_DU_3_UDS_CC "Funktionseinschränkung aufgrund aktivem UDS-Communication Control; siehe VW80124";
CM_ SG_ 2600468724 NM_DU_4_SNI "Source Node-Identifier (SNI) identifiziert den Sender der NM-Botschaft (Knotenadresse) eindeutig im Fahrzeug";
CM_ SG_ 2600468724 NM_DU_4_NM_State "1 = Zustand Repeat Message (<-- Bus-Sleep Mode)
2 = Zustand Repeat Message (<-- Prepare Bus-Sleep Mode)
4 = Zustand Normal Operation (<-- Repeat Message)
8 = Zustand Normal Operation (<-- Ready Sleep)";
CM_ SG_ 2600468724 NM_DU_4_Car_Wakeup "Car Wakeup (Gateway wertet aus)
";
CM_ SG_ 2600468724 NM_DU_4_Wakeup "Steuergerät hat KL15-EIN erkannt";
CM_ SG_ 2600468724 NM_DU_4_NM_aktiv_KL15 "Steuergerät hat KL15-EIN erkannt";
CM_ SG_ 2600468724 NM_DU_4_NM_aktiv_Diagnose "Diagnose befindet sich nach VW80124 in einer NonDefaultDiagnostic-Session, z.B. ExtendedDiagnostic-Session";
CM_ SG_ 2600468724 NM_DU_4_NM_aktiv_Tmin "Mindestaktivzeit ist noch nicht abgelaufen (bei jedem Weckereignis wird die Mindestaktivzeit neu gestartet)";
CM_ SG_ 2600468724 NM_DU_4_NL_Dimmung "lokale / interne Aktivität vor WakeUp: Dimmung aktiv";
CM_ SG_ 2600468724 NM_DU_4_UDS_CC "Funktionseinschränkung aufgrund aktivem UDS-Communication Control; siehe VW80124";
CM_ SG_ 2600468723 NM_ExBox_SNI "Source Node-Identifier (SNI) identifiziert den Sender der NM-Botschaft (Knotenadresse) eindeutig im Fahrzeug";
CM_ SG_ 2600468723 NM_ExBox_NM_State "1 = Zustand Repeat Message (<-- Bus-Sleep Mode)
2 = Zustand Repeat Message (<-- Prepare Bus-Sleep Mode)
4 = Zustand Normal Operation (<-- Repeat Message)
8 = Zustand Normal Operation (<-- Ready Sleep)";
CM_ SG_ 2600468723 NM_ExBox_Car_Wakeup "Car Wakeup (Gateway wertet aus)
";
CM_ SG_ 2600468723 NM_ExBox_Wakeup "enthält die Weckursache; stehen mehrere Weckursachen parallel an, dann muss der kleinste Wert übertragen werden";
CM_ SG_ 2600468723 NM_ExBox_NM_aktiv_KL15 "Steuergerät hat KL15-EIN erkannt";
CM_ SG_ 2600468723 NM_ExBox_NM_aktiv_Diagnose "Diagnose befindet sich nach VW80124 in einer NonDefaultDiagnostic-Session, z.B. ExtendedDiagnostic-Session";
CM_ SG_ 2600468723 NM_ExBox_NM_aktiv_Tmin "Mindestaktivzeit ist noch nicht abgelaufen (bei jedem Weckereignis wird die Mindestaktivzeit neu gestartet)";
CM_ SG_ 2600468723 NM_ExBox_UDS_CC "Funktionseinschränkung aufgrund aktivem UDS-Communication Control; siehe VW80124";
CM_ SG_ 2600468595 NM_Info_El_SNI "Source Node-Identifier (SNI) identifiziert den Sender der NM-Botschaft (Knotenadresse) eindeutig im Fahrzeug";
CM_ SG_ 2600468595 NM_Info_El_NM_State "1 = Zustand Repeat Message (<-- Bus-Sleep Mode)
2 = Zustand Repeat Message (<-- Prepare Bus-Sleep Mode)
4 = Zustand Normal Operation (<-- Repeat Message)
8 = Zustand Normal Operation (<-- Ready Sleep)";
CM_ SG_ 2600468595 NM_Info_El_Car_Wakeup "Car Wakeup (Gateway wertet aus)

MLBevo:
- Remote Lock/Unlock
- Remote STH

MQB (MIB ab Gen3):
- OCU Download";
CM_ SG_ 2600468595 NM_Info_El_Wakeup "enthält die Weckursache; stehen mehrere Weckursachen parallel an, dann muss der kleinste Wert übertragen werden";
CM_ SG_ 2600468595 NM_Info_El_NM_aktiv_KL15 "Steuergerät hat KL15-EIN erkannt";
CM_ SG_ 2600468595 NM_Info_El_NM_aktiv_Diagnose "Diagnose befindet sich nach VW80124 in einer NonDefaultDiagnostic-Session, z.B. ExtendedDiagnostic-Session";
CM_ SG_ 2600468595 NM_Info_El_NM_aktiv_Tmin "Mindestaktivzeit ist noch nicht abgelaufen (bei jedem Weckereignis wird die Mindestaktivzeit neu gestartet)";
CM_ SG_ 2600468595 NM_Info_El_NM_aktiv_MIBCAN "MIB-CAN länger als Mindestaktivzeit aktiv für: SWDL, TEL, Radio_On/Hour_Mode, Mute_Mode
TT3: ICAN länger als Mindestaktivzeit aktiv für MFL-Bedienung";
CM_ SG_ 2600468595 NM_Info_El_NM_aktiv_BAP_Comm "MQB:
CAN wird zum Betrieb des BAP CAN Verstärkers wachgehalten";
CM_ SG_ 2600468595 NM_Info_El_NL_MMI_ON "lokale / interne Aktivität vor WakeUp: MMI_ON (MIBCAN aktiv)
(auf ICAN senden; z.B. für SWDL, TEL, Radio_On/Hour Mode, Mute_Mode)";
CM_ SG_ 2600468595 NM_Info_El_NL_ICAN "lokale / interne Aktivität vor WakeUp: ICAN aktiv (auf MIBCAN senden)";
CM_ SG_ 2600468595 NM_Info_El_NL_SWDL "lokale / interne Aktivität vor WakeUp: SW Download aktiv";
CM_ SG_ 2600468595 NM_Info_El_NL_Dimmung "lokale / interne Aktivität vor WakeUp: Dimmung aktiv (z.B. Eject-Taste)";
CM_ SG_ 2600468595 NM_Info_El_NL_MMI_Standby "lokale / interne Aktivität vor WakeUp: MMI_Standby oder MMI_STANDBY_PWR_SAVE (Nachlauf 30s inkl. TEL-/NAVI-Nachlauf)";
CM_ SG_ 2600468595 NM_Info_El_UDS_CC "Funktionseinschränkung aufgrund aktivem UDS-Communication Control; siehe VW80124";
CM_ SG_ 2600468500 NM_Kombi_SNI "Source Node-Identifier (SNI) identifiziert den Sender der NM-Botschaft (Knotenadresse) eindeutig im Fahrzeug";
CM_ SG_ 2600468500 NM_Kombi_NM_State "1 = Zustand Repeat Message (<-- Bus-Sleep Mode)
																																							 
																							  
																			   
																																	  
															   
																							   
																																						  
																					   
2 = Zustand Repeat Message (<-- Prepare Bus-Sleep Mode)
4 = Zustand Normal Operation (<-- Repeat Message)
8 = Zustand Normal Operation (<-- Ready Sleep)";
CM_ SG_ 2600468500 NM_Kombi_Car_Wakeup "Car Wakeup (Gateway wertet aus)
MQB: Timer abgelaufen, Zeitverstellung manuell oder automatisch (>5Min) beim aktiven Timer, Verlassenswarnung

MLBevo: Timer abgelaufen, Zeitverstellung manuell oder automatisch (>5Min) beim aktiven Timer
Berechnung Tan";
CM_ SG_ 2600468500 NM_Kombi_Wakeup "enthält die Weckursache; stehen mehrere Weckursachen parallel an, dann muss der kleinste Wert übertragen werden";
CM_ SG_ 2600468500 NM_Kombi_NM_aktiv_KL15 "Steuergerät hat KL15-EIN erkannt";
CM_ SG_ 2600468500 NM_Kombi_NM_aktiv_Diagnose "Diagnose befindet sich nach VW80124 in einer NonDefaultDiagnostic-Session, z.B. ExtendedDiagnostic-Session";
CM_ SG_ 2600468500 NM_Kombi_NM_aktiv_Tmin "Mindestaktivzeit ist noch nicht abgelaufen (bei jedem Weckereignis wird die Mindestaktivzeit neu gestartet)";
CM_ SG_ 2600468500 NM_Kombi_NM_aktiv_Buzzer "Buzzer Weckereignis aktiv (1 Minute)";
CM_ SG_ 2600468500 NM_Kombi_NM_aktiv_Schluesselkomm "Schlüsselkommunikation aktiv (WFS)";
CM_ SG_ 2600468500 NM_Kombi_NM_aktiv_VLW "Nachlaufursache des CAN. Es findet ein CAN Nachlauf für Dauer von max 5 Min statt, sofern Auslösebedingungen für die Verlassenswarnung (VLW) erfüllt sind. Die VLW ist im Kombi umgesetzt. Auslösebedingungen der VLW sind:
- Fahrzeugstillstand (v < 3km/h)
";
CM_ SG_ 2600468500 NM_Kombi_NL_Beleuchtung "lokale / interne Aktivität vor WakeUp: Beleuchtung aktiv";
CM_ SG_ 2600468500 NM_Kombi_UDS_CC "Funktionseinschränkung aufgrund aktivem UDS-Communication Control; siehe VW80124";
CM_ SG_ 2600468726 NM_LSR_1_SNI "Source Node-Identifier (SNI) identifiziert den Sender der NM-Botschaft (Knotenadresse) eindeutig im Fahrzeug";
CM_ SG_ 2600468726 NM_LSR_1_NM_State "1 = Zustand Repeat Message (<-- Bus-Sleep Mode)
2 = Zustand Repeat Message (<-- Prepare Bus-Sleep Mode)
4 = Zustand Normal Operation (<-- Repeat Message)
8 = Zustand Normal Operation (<-- Ready Sleep)";
CM_ SG_ 2600468726 NM_LSR_1_Car_Wakeup "Car Wakeup (Gateway wertet aus)
";
CM_ SG_ 2600468726 NM_LSR_1_Wakeup "enthält die Weckursache; stehen mehrere Weckursachen parallel an, dann muss der kleinste Wert übertragen werden";
CM_ SG_ 2600468726 NM_LSR_1_NM_aktiv_KL15 "Steuergerät hat KL15-EIN erkannt";
CM_ SG_ 2600468726 NM_LSR_1_NM_aktiv_Diagnose "Diagnose befindet sich nach VW80124 in einer NonDefaultDiagnostic-Session, z.B. ExtendedDiagnostic-Session";
CM_ SG_ 2600468726 NM_LSR_1_NM_aktiv_Tmin "Mindestaktivzeit ist noch nicht abgelaufen (bei jedem Weckereignis wird die Mindestaktivzeit neu gestartet)";
CM_ SG_ 2600468726 NM_LSR_1_NL_Dimmung "lokale / interne Aktivität vor WakeUp: Dimmung aktiv";
CM_ SG_ 2600468726 NM_LSR_1_NL_WakeUp_Lock "lokale / interne Aktivität vor WakeUp:
HID ist aufgrund des Transportmodus, Q_critical oder WU_lock gesperrt.";
CM_ SG_ 2600468726 NM_LSR_1_UDS_CC "Funktionseinschränkung aufgrund aktivem UDS-Communication Control; siehe VW80124";
BA_DEF_ BO_  "DiagRequest" ENUM  "No","Yes";
BA_DEF_ BO_  "DiagResponse" ENUM  "No","Yes";
BA_DEF_ BO_  "DiagState" ENUM  "No","Yes";
BA_DEF_ BO_  "GenMsgChkConstant" HEX 0 4095;
BA_DEF_ BO_  "GenMsgCycleTime" INT 0 65535;
BA_DEF_ BO_  "GenMsgCycleTimeFast" INT 0 65535;
BA_DEF_ BO_  "GenMsgDelayTime" INT 0 100000;
BA_DEF_ BO_  "GenMsgILSupport" ENUM  "No","Yes";
BA_DEF_ BO_  "GenMsgNrOfRepetition" INT 0 100;
BA_DEF_ BO_  "GenMsgPDUConstants" STRING ;
BA_DEF_ BO_  "GenMsgSendType" ENUM  "Cyclic","not_used","not_used","not_used","not_used","not_used","not_used","IfActive","NoMsgSendType";
BA_DEF_ BO_  "GenMsgStartDelayTime" INT 0 100000;
BA_DEF_ BO_  "NmMessage" ENUM  "No","Yes";
BA_DEF_ BO_  "NmhMessage" ENUM  "No","Yes";
BA_DEF_ BO_  "MsgType" ENUM  "Application","NM ","NMH","TP2.0","ISO-TP ","BAP","EID","KS";
BA_DEF_ BO_  "VAGTP20_API" HEX 0 255;
BA_DEF_ BO_  "VAGTP20_DynConnection" ENUM  "No","Yes";
BA_DEF_ BO_  "VAGTP20_DynSetup" ENUM  "No","Yes";
BA_DEF_ BO_  "VAGTP20_StatConnection" ENUM  "No","Yes";
BA_DEF_ SG_  "GenSigActiveRepetitions" INT -2147483648 2147483647;
BA_DEF_ SG_  "GenSigInactiveValue" INT -2147483648 2147483647;
BA_DEF_ SG_  "GenSigSendType" ENUM  "Cyclic","OnWrite","OnWriteWithRepetition","OnChange","OnChangeWithRepetition","IfActive","IfActiveWithRepetition","NoSigSendType","OnChangeAndIfActive","OnChangeAndIfActiveWithRepetition";
BA_DEF_ SG_  "GenSigStartValue" INT -2147483648 2147483647;
BA_DEF_ SG_  "NWM-WakeupAllowed" ENUM  "No","Yes";
BA_DEF_ SG_  "GenSigFuncType" ENUM  "NoFunction","MsgCounter","CRC-8","XOR","XOR-2","DatedBit","SW-Kl15","CHK","Constant","Protocol","CRC-8-SAE_J1850","CRC-32","DataLength","DataID","MsgCounter16","SOK-Signatur";
BA_DEF_ SG_  "GenSigSwitchedByIgnition" ENUM  "No","Yes";
BA_DEF_ SG_  "Fehlerwert" HEX 0 2147483647;
BA_DEF_ SG_  "GenSigMissingSourceValue" HEX 0 2147483647;
BA_DEF_REL_ BU_SG_REL_  "GenSigTimeoutTime" INT 0 65535;
BA_DEF_DEF_  "DiagRequest" "No";
BA_DEF_DEF_  "DiagResponse" "No";
BA_DEF_DEF_  "DiagState" "No";
BA_DEF_DEF_  "GenMsgChkConstant" 0;
BA_DEF_DEF_  "GenMsgCycleTime" 0;
BA_DEF_DEF_  "GenMsgCycleTimeFast" 0;
BA_DEF_DEF_  "GenMsgDelayTime" 0;
BA_DEF_DEF_  "GenMsgILSupport" "No";
BA_DEF_DEF_  "GenMsgNrOfRepetition" 0;
BA_DEF_DEF_  "GenMsgPDUConstants" "";
BA_DEF_DEF_  "GenMsgSendType" "NoMsgSendType";
BA_DEF_DEF_  "GenMsgStartDelayTime" 0;
BA_DEF_DEF_  "NmMessage" "No";
BA_DEF_DEF_  "NmhMessage" "No";
BA_DEF_DEF_  "MsgType" "Application";
BA_DEF_DEF_  "VAGTP20_API" 0;
BA_DEF_DEF_  "VAGTP20_DynConnection" "No";
BA_DEF_DEF_  "VAGTP20_DynSetup" "No";
BA_DEF_DEF_  "VAGTP20_StatConnection" "No";
BA_DEF_DEF_  "GenSigActiveRepetitions" 0;
BA_DEF_DEF_  "GenSigInactiveValue" 0;
BA_DEF_DEF_  "GenSigSendType" "NoSigSendType";
BA_DEF_DEF_  "GenSigStartValue" 0;
BA_DEF_DEF_  "NWM-WakeupAllowed" "No";
BA_DEF_DEF_  "GenSigFuncType" "NoFunction";
BA_DEF_DEF_  "GenSigSwitchedByIgnition" "Yes";
BA_DEF_DEF_  "Fehlerwert" 0;
BA_DEF_DEF_  "GenSigMissingSourceValue" 0;
BA_DEF_DEF_REL_ "GenSigTimeoutTime" 0;
BA_ "GenMsgSendType" BO_ 2549088421 0;
BA_ "GenMsgILSupport" BO_ 2549088421 1;
BA_ "GenMsgCycleTime" BO_ 2549088421 500;
BA_ "GenMsgSendType" BO_ 2549088422 0;
BA_ "GenMsgILSupport" BO_ 2549088422 1;
BA_ "GenMsgCycleTime" BO_ 2549088422 500;
BA_ "GenMsgSendType" BO_ 1720 0;
BA_ "GenMsgILSupport" BO_ 1720 1;
BA_ "GenMsgCycleTime" BO_ 1720 1000;
BA_ "GenMsgSendType" BO_ 1725 0;
BA_ "GenMsgILSupport" BO_ 1725 1;
BA_ "GenMsgDelayTime" BO_ 1725 50;
BA_ "GenMsgCycleTime" BO_ 1725 500;
BA_ "GenMsgSendType" BO_ 2527679493 0;
BA_ "GenMsgILSupport" BO_ 2527679493 1;
BA_ "GenMsgDelayTime" BO_ 2527679493 10;
BA_ "GenMsgCycleTime" BO_ 2527679493 1000;
BA_ "GenMsgSendType" BO_ 2527679492 0;
BA_ "GenMsgILSupport" BO_ 2527679492 1;
BA_ "GenMsgDelayTime" BO_ 2527679492 10;
BA_ "GenMsgCycleTime" BO_ 2527679492 1000;
BA_ "GenMsgSendType" BO_ 2527679502 0;
BA_ "GenMsgILSupport" BO_ 2527679502 1;
BA_ "GenMsgDelayTime" BO_ 2527679502 10;
BA_ "GenMsgCycleTime" BO_ 2527679502 1000;
BA_ "MsgType" BO_ 2549899278 4;
BA_ "MsgType" BO_ 2550030350 4;
BA_ "GenMsgSendType" BO_ 1148 0;
BA_ "GenMsgILSupport" BO_ 1148 1;
BA_ "GenMsgDelayTime" BO_ 1148 40;
BA_ "GenMsgCycleTime" BO_ 1148 1000;
BA_ "MsgType" BO_ 2583754245 4;
BA_ "MsgType" BO_ 2583885317 4;
BA_ "GenMsgNrOfRepetition" BO_ 1471 5;
BA_ "GenMsgILSupport" BO_ 1471 1;
BA_ "GenMsgDelayTime" BO_ 1471 30;
BA_ "GenMsgCycleTimeFast" BO_ 1471 1000;
BA_ "GenMsgSendType" BO_ 2527679491 0;
BA_ "GenMsgILSupport" BO_ 2527679491 1;
BA_ "GenMsgDelayTime" BO_ 2527679491 10;
BA_ "GenMsgCycleTime" BO_ 2527679491 1000;
BA_ "GenMsgSendType" BO_ 2527679490 0;
BA_ "GenMsgILSupport" BO_ 2527679490 1;
BA_ "GenMsgDelayTime" BO_ 2527679490 10;
BA_ "GenMsgCycleTime" BO_ 2527679490 1000;
BA_ "GenMsgSendType" BO_ 2527679501 0;
BA_ "GenMsgILSupport" BO_ 2527679501 1;
BA_ "GenMsgDelayTime" BO_ 2527679501 10;
BA_ "GenMsgCycleTime" BO_ 2527679501 1000;
BA_ "GenMsgSendType" BO_ 2527679499 0;
BA_ "GenMsgILSupport" BO_ 2527679499 1;
BA_ "GenMsgDelayTime" BO_ 2527679499 10;
BA_ "GenMsgCycleTime" BO_ 2527679499 1000;
BA_ "GenMsgSendType" BO_ 1156 0;
BA_ "GenMsgILSupport" BO_ 1156 1;
BA_ "GenMsgCycleTime" BO_ 1156 200;
BA_ "GenMsgSendType" BO_ 1157 0;
BA_ "GenMsgILSupport" BO_ 1157 1;
BA_ "GenMsgCycleTime" BO_ 1157 200;
BA_ "GenMsgSendType" BO_ 1158 0;
BA_ "GenMsgILSupport" BO_ 1158 1;
BA_ "GenMsgCycleTime" BO_ 1158 200;
BA_ "GenMsgSendType" BO_ 2589283496 0;
BA_ "GenMsgILSupport" BO_ 2589283496 1;
BA_ "GenMsgCycleTime" BO_ 2589283496 500;
BA_ "GenMsgSendType" BO_ 2527679647 0;
BA_ "GenMsgILSupport" BO_ 2527679647 1;
BA_ "GenMsgCycleTime" BO_ 2527679647 200;
BA_ "MsgType" BO_ 2600468721 2;
BA_ "NmhMessage" BO_ 2600468721 1;
BA_ "GenMsgCycleTime" BO_ 2600468721 200;
BA_ "MsgType" BO_ 2600468720 2;
BA_ "NmhMessage" BO_ 2600468720 1;
BA_ "GenMsgCycleTime" BO_ 2600468720 200;
BA_ "MsgType" BO_ 2600468722 2;
BA_ "NmhMessage" BO_ 2600468722 1;
BA_ "GenMsgCycleTime" BO_ 2600468722 200;
BA_ "MsgType" BO_ 2600468725 2;
BA_ "NmhMessage" BO_ 2600468725 1;
BA_ "GenMsgCycleTime" BO_ 2600468725 200;
BA_ "MsgType" BO_ 2600468734 2;
BA_ "NmhMessage" BO_ 2600468734 1;
BA_ "GenMsgCycleTime" BO_ 2600468734 200;
BA_ "MsgType" BO_ 2600468723 2;
BA_ "NmhMessage" BO_ 2600468723 1;
BA_ "GenMsgCycleTime" BO_ 2600468723 200;
BA_ "MsgType" BO_ 2600468595 2;
BA_ "NmhMessage" BO_ 2600468595 1;
BA_ "GenMsgCycleTime" BO_ 2600468595 200;
BA_ "MsgType" BO_ 2600468500 2;
BA_ "NmhMessage" BO_ 2600468500 1;
BA_ "GenMsgCycleTime" BO_ 2600468500 200;
BA_ "MsgType" BO_ 2600468726 2;
BA_ "NmhMessage" BO_ 2600468726 1;
BA_ "GenMsgCycleTime" BO_ 2600468726 200;
BA_ "GenSigSwitchedByIgnition" SG_ 2549088421 WLC1_KompSchutz 0;
BA_ "GenSigSendType" SG_ 2549088421 WLC1_KompSchutz 0;
BA_ "GenSigSwitchedByIgnition" SG_ 2549088421 WLC1_Abschaltstufe 0;
BA_ "GenSigSendType" SG_ 2549088421 WLC1_Abschaltstufe 0;
BA_ "GenSigSwitchedByIgnition" SG_ 2549088421 WLC1_Transport_Mode 0;
BA_ "GenSigSendType" SG_ 2549088421 WLC1_Transport_Mode 0;
BA_ "GenSigSwitchedByIgnition" SG_ 2549088421 WLC1_Nachlauftyp 0;
BA_ "GenSigStartValue" SG_ 2549088421 WLC1_Nachlauftyp 2;
BA_ "GenSigSendType" SG_ 2549088421 WLC1_Nachlauftyp 0;
BA_ "GenSigSwitchedByIgnition" SG_ 2549088421 WLC1_SNI 0;
BA_ "GenSigStartValue" SG_ 2549088421 WLC1_SNI 165;
BA_ "GenSigSendType" SG_ 2549088421 WLC1_SNI 0;
BA_ "GenSigSwitchedByIgnition" SG_ 2549088421 WLC1_BusKnockOutTimer 0;
BA_ "GenSigStartValue" SG_ 2549088421 WLC1_BusKnockOutTimer 255;
BA_ "GenSigSendType" SG_ 2549088421 WLC1_BusKnockOutTimer 0;
BA_ "GenSigSwitchedByIgnition" SG_ 2549088421 NM_WLC1_Wakeup 0;
BA_ "GenSigSendType" SG_ 2549088421 NM_WLC1_Wakeup 0;
BA_ "GenSigSwitchedByIgnition" SG_ 2549088421 NM_WLC1_Lokalaktiv 0;
BA_ "GenSigSendType" SG_ 2549088421 NM_WLC1_Lokalaktiv 0;
BA_ "GenSigSwitchedByIgnition" SG_ 2549088421 WLC1_KD_Fehler 0;
BA_ "GenSigSendType" SG_ 2549088421 WLC1_KD_Fehler 0;
BA_ "GenSigSwitchedByIgnition" SG_ 2549088422 WLC2_KompSchutz 0;
BA_ "GenSigSwitchedByIgnition" SG_ 2549088422 WLC2_Abschaltstufe 0;
BA_ "GenSigSwitchedByIgnition" SG_ 2549088422 WLC2_Transport_Mode 0;
BA_ "GenSigSwitchedByIgnition" SG_ 2549088422 WLC2_Nachlauftyp 0;
BA_ "GenSigStartValue" SG_ 2549088422 WLC2_Nachlauftyp 2;
BA_ "GenSigSwitchedByIgnition" SG_ 2549088422 WLC2_SNI 0;
BA_ "GenSigStartValue" SG_ 2549088422 WLC2_SNI 166;
BA_ "GenSigSwitchedByIgnition" SG_ 2549088422 WLC2_BusKnockOutTimer 0;
BA_ "GenSigStartValue" SG_ 2549088422 WLC2_BusKnockOutTimer 255;
BA_ "GenSigSwitchedByIgnition" SG_ 2549088422 NM_WLC2_Wakeup 0;
BA_ "GenSigSendType" SG_ 2549088422 NM_WLC2_Wakeup 0;
BA_ "GenSigSwitchedByIgnition" SG_ 2549088422 NM_WLC2_Lokalaktiv 0;
BA_ "GenSigSwitchedByIgnition" SG_ 2549088422 WLC2_KD_Fehler 0;
BA_ "GenSigSwitchedByIgnition" SG_ 1720 KBI_Reifenumfang 0;
BA_ "GenSigFuncType" SG_ 1720 KBI_Reifenumfang 8;
BA_ "GenSigSendType" SG_ 1720 KBI_Reifenumfang 0;
BA_ "GenSigSwitchedByIgnition" SG_ 1720 KBI_Variante_USA 0;
BA_ "GenSigSendType" SG_ 1720 KBI_Variante_USA 0;
BA_ "GenSigSwitchedByIgnition" SG_ 1720 KBI_Variante 0;
BA_ "GenSigSendType" SG_ 1720 KBI_Variante 0;
BA_ "GenSigSwitchedByIgnition" SG_ 1720 KBI_GAP_Warn_Zeit_abgelaufen 0;
BA_ "GenSigSwitchedByIgnition" SG_ 1720 KBI_Quittierung_Naesse 0;
BA_ "GenSigSwitchedByIgnition" SG_ 1720 KBI_BCmE_aktiv 0;
BA_ "GenSigSendType" SG_ 1720 KBI_BCmE_aktiv 0;
BA_ "GenSigSwitchedByIgnition" SG_ 1720 KBI_Sparhinweis_quittiert 0;
BA_ "GenSigSendType" SG_ 1720 KBI_Sparhinweis_quittiert 0;
BA_ "Fehlerwert" SG_ 1720 KBI_Tankfuellstand_Prozent 127;
BA_ "GenSigSwitchedByIgnition" SG_ 1720 KBI_Tankfuellstand_Prozent 0;
BA_ "GenSigStartValue" SG_ 1720 KBI_Tankfuellstand_Prozent 126;
BA_ "GenSigSendType" SG_ 1720 KBI_Tankfuellstand_Prozent 0;
BA_ "GenSigSwitchedByIgnition" SG_ 1720 KBI_Nachtanken_erkannt 0;
BA_ "GenSigSendType" SG_ 1720 KBI_Nachtanken_erkannt 0;
BA_ "Fehlerwert" SG_ 1720 KBI_Tankinhalt_hochaufl 16383;
BA_ "GenSigSwitchedByIgnition" SG_ 1720 KBI_Tankinhalt_hochaufl 0;
BA_ "GenSigStartValue" SG_ 1720 KBI_Tankinhalt_hochaufl 16382;
BA_ "GenSigSendType" SG_ 1720 KBI_Tankinhalt_hochaufl 0;
BA_ "Fehlerwert" SG_ 1720 KBI_Max_Tankinhalt 255;
BA_ "GenSigSwitchedByIgnition" SG_ 1720 KBI_Max_Tankinhalt 0;
BA_ "GenSigStartValue" SG_ 1720 KBI_Max_Tankinhalt 254;
BA_ "GenSigSendType" SG_ 1720 KBI_Max_Tankinhalt 0;
BA_ "GenSigSwitchedByIgnition" SG_ 1720 KBI_Reifenumfang_Sekundaer 0;
BA_ "GenSigSendType" SG_ 1720 KBI_Reifenumfang_Sekundaer 0;
BA_ "GenSigSwitchedByIgnition" SG_ 1720 KBI_Quittierung_cAQP 0;
BA_ "GenSigSwitchedByIgnition" SG_ 1725 KBI_Tankabgl_1 0;
BA_ "GenSigStartValue" SG_ 1725 KBI_Tankabgl_1 128;
BA_ "GenSigSendType" SG_ 1725 KBI_Tankabgl_1 0;
BA_ "GenSigSwitchedByIgnition" SG_ 1725 KBI_Tankabgl_2 0;
BA_ "GenSigStartValue" SG_ 1725 KBI_Tankabgl_2 128;
BA_ "GenSigSendType" SG_ 1725 KBI_Tankabgl_2 0;
BA_ "GenSigSwitchedByIgnition" SG_ 1725 KBI_Tankabgl_3 0;
BA_ "GenSigStartValue" SG_ 1725 KBI_Tankabgl_3 128;
BA_ "GenSigSendType" SG_ 1725 KBI_Tankabgl_3 0;
BA_ "GenSigMissingSourceValue" SG_ 1725 KBI_Fotosensor 255;
BA_ "Fehlerwert" SG_ 1725 KBI_Fotosensor 255;
BA_ "GenSigSwitchedByIgnition" SG_ 1725 KBI_Fotosensor 0;
BA_ "GenSigStartValue" SG_ 1725 KBI_Fotosensor 254;
BA_ "GenSigSendType" SG_ 1725 KBI_Fotosensor 0;
BA_ "Fehlerwert" SG_ 1725 KBI_KL58d 255;
BA_ "GenSigSwitchedByIgnition" SG_ 1725 KBI_KL58d 0;
BA_ "GenSigStartValue" SG_ 1725 KBI_KL58d 254;
BA_ "GenSigSendType" SG_ 1725 KBI_KL58d 0;
BA_ "Fehlerwert" SG_ 1725 KBI_KL58s 127;
BA_ "GenSigSwitchedByIgnition" SG_ 1725 KBI_KL58s 0;
BA_ "GenSigStartValue" SG_ 1725 KBI_KL58s 126;
BA_ "GenSigSendType" SG_ 1725 KBI_KL58s 3;
BA_ "GenSigSwitchedByIgnition" SG_ 1725 KBI_B_accscreen 0;
BA_ "NWM-WakeupAllowed" SG_ 1725 KBI_B_accscreen 1;
BA_ "GenSigSendType" SG_ 1725 KBI_B_accscreen 0;
BA_ "GenSigSwitchedByIgnition" SG_ 1725 KBI_Uebern 0;
BA_ "GenSigSendType" SG_ 1725 KBI_Uebern 0;
BA_ "GenSigSwitchedByIgnition" SG_ 1725 KBI_Uhr_Verstellung 0;
BA_ "GenSigSendType" SG_ 1725 KBI_Uhr_Verstellung 3;
BA_ "GenSigSwitchedByIgnition" SG_ 2527679493 KBI_Req_TID 0;
BA_ "GenSigSendType" SG_ 2527679493 KBI_Req_TID 3;
BA_ "GenSigSwitchedByIgnition" SG_ 2527679493 KBI_LVDS_Lock 0;
BA_ "GenSigSendType" SG_ 2527679493 KBI_LVDS_Lock 3;
BA_ "GenSigSwitchedByIgnition" SG_ 2527679493 KBI_Req_Lastmode 0;
BA_ "GenSigSendType" SG_ 2527679493 KBI_Req_Lastmode 3;
BA_ "GenSigSwitchedByIgnition" SG_ 2527679493 KBI_Req_Focus 0;
BA_ "GenSigSendType" SG_ 2527679493 KBI_Req_Focus 3;
BA_ "GenSigSwitchedByIgnition" SG_ 2527679493 KBI_Req_ScreenFormat 0;
BA_ "GenSigSendType" SG_ 2527679493 KBI_Req_ScreenFormat 3;
BA_ "GenSigSwitchedByIgnition" SG_ 2527679493 KBI_Req_MainContext 0;
BA_ "GenSigSendType" SG_ 2527679493 KBI_Req_MainContext 3;
BA_ "GenSigSwitchedByIgnition" SG_ 2527679493 KBI_Req_PopupContext 0;
BA_ "GenSigSendType" SG_ 2527679493 KBI_Req_PopupContext 3;
BA_ "GenSigSwitchedByIgnition" SG_ 2527679493 KBI_Req_MenuContext 0;
BA_ "GenSigSendType" SG_ 2527679493 KBI_Req_MenuContext 3;
BA_ "GenSigSwitchedByIgnition" SG_ 2527679493 KBI_Req_Animation_Screen_SubType 0;
BA_ "GenSigSendType" SG_ 2527679493 KBI_Req_Animation_Screen_SubType 3;
BA_ "GenSigSwitchedByIgnition" SG_ 2527679493 KBI_Req_Animation_Screen_Type 0;
BA_ "GenSigSendType" SG_ 2527679493 KBI_Req_Animation_Screen_Type 3;
BA_ "GenSigSwitchedByIgnition" SG_ 2527679493 KBI_Req_Animation_Lead_Time 0;
BA_ "GenSigStartValue" SG_ 2527679493 KBI_Req_Animation_Lead_Time 255;
BA_ "GenSigSendType" SG_ 2527679493 KBI_Req_Animation_Lead_Time 3;
BA_ "GenSigSwitchedByIgnition" SG_ 2527679493 KBI_Req_Animation_Add_Info 0;
BA_ "GenSigSendType" SG_ 2527679493 KBI_Req_Animation_Add_Info 3;
BA_ "GenSigSwitchedByIgnition" SG_ 2527679492 KBI_Sta_TID 0;
BA_ "GenSigSendType" SG_ 2527679492 KBI_Sta_TID 3;
BA_ "GenSigSwitchedByIgnition" SG_ 2527679492 KBI_Sta_Animation 0;
BA_ "GenSigSendType" SG_ 2527679492 KBI_Sta_Animation 3;
BA_ "GenSigSwitchedByIgnition" SG_ 2527679492 KBI_Sta_Focus 0;
BA_ "GenSigSendType" SG_ 2527679492 KBI_Sta_Focus 3;
BA_ "GenSigSwitchedByIgnition" SG_ 2527679492 KBI_Sta_ScreenFormat 0;
BA_ "GenSigSendType" SG_ 2527679492 KBI_Sta_ScreenFormat 3;
BA_ "GenSigSwitchedByIgnition" SG_ 2527679492 KBI_Sta_MainContext 0;
BA_ "GenSigSendType" SG_ 2527679492 KBI_Sta_MainContext 3;
BA_ "GenSigSwitchedByIgnition" SG_ 2527679492 KBI_Sta_PopupContext 0;
BA_ "GenSigSendType" SG_ 2527679492 KBI_Sta_PopupContext 3;
BA_ "GenSigSwitchedByIgnition" SG_ 2527679492 KBI_Sta_MenuContext 0;
BA_ "GenSigSendType" SG_ 2527679492 KBI_Sta_MenuContext 3;
BA_ "GenSigSwitchedByIgnition" SG_ 2527679492 KBI_Sta_Animation_Screen_SubType 0;
BA_ "GenSigSendType" SG_ 2527679492 KBI_Sta_Animation_Screen_SubType 3;
BA_ "GenSigSwitchedByIgnition" SG_ 2527679492 KBI_Sta_Animation_Screen_Type 0;
BA_ "GenSigSendType" SG_ 2527679492 KBI_Sta_Animation_Screen_Type 3;
BA_ "GenSigSwitchedByIgnition" SG_ 2527679492 KBI_Sta_Animation_Lead_Time 0;
BA_ "GenSigStartValue" SG_ 2527679492 KBI_Sta_Animation_Lead_Time 255;
BA_ "GenSigSendType" SG_ 2527679492 KBI_Sta_Animation_Lead_Time 3;
BA_ "GenSigSwitchedByIgnition" SG_ 2527679492 KBI_Sta_Animation_Add_Info 0;
BA_ "GenSigSendType" SG_ 2527679492 KBI_Sta_Animation_Add_Info 3;
BA_ "GenSigSwitchedByIgnition" SG_ 2527679502 KBI_Popup_TID 0;
BA_ "GenSigSendType" SG_ 2527679502 KBI_Popup_TID 3;
BA_ "GenSigSwitchedByIgnition" SG_ 2527679502 KBI_Popup_MMIPopupState 0;
BA_ "GenSigSendType" SG_ 2527679502 KBI_Popup_MMIPopupState 3;
BA_ "GenSigSwitchedByIgnition" SG_ 2527679502 KBI_Popup_MMIPopupID 0;
BA_ "GenSigSendType" SG_ 2527679502 KBI_Popup_MMIPopupID 3;
BA_ "GenSigSwitchedByIgnition" SG_ 2527679502 KBI_Popup_MMIPopupPriority 0;
BA_ "GenSigSendType" SG_ 2527679502 KBI_Popup_MMIPopupPriority 3;
BA_ "GenSigSwitchedByIgnition" SG_ 2527679502 KBI_Popup_ZPMSlotID 0;
BA_ "GenSigSendType" SG_ 2527679502 KBI_Popup_ZPMSlotID 3;
BA_ "GenSigSwitchedByIgnition" SG_ 2527679502 KBI_Popup_ScreenFormat 0;
BA_ "GenSigSendType" SG_ 2527679502 KBI_Popup_ScreenFormat 3;
BA_ "GenSigSwitchedByIgnition" SG_ 2527679502 KBI_Popup_Focus 0;
BA_ "GenSigSendType" SG_ 2527679502 KBI_Popup_Focus 3;
BA_ "GenSigSwitchedByIgnition" SG_ 2549899278 KS_SSN_ABT_1_Req_Data 0;
BA_ "GenSigSendType" SG_ 2549899278 KS_SSN_ABT_1_Req_Data 3;
BA_ "GenSigSwitchedByIgnition" SG_ 2550030350 KS_SSN_ABT_1_Resp_Data 0;
BA_ "GenSigSendType" SG_ 2550030350 KS_SSN_ABT_1_Resp_Data 3;
BA_ "GenSigSwitchedByIgnition" SG_ 1148 LSR_Variant 0;
BA_ "GenSigSendType" SG_ 1148 LSR_Variant 0;
BA_ "GenSigSwitchedByIgnition" SG_ 1148 LSR_SystemMode 0;
BA_ "GenSigSendType" SG_ 1148 LSR_SystemMode 0;
BA_ "Fehlerwert" SG_ 1148 LSR_DKM_Kurzschluss_GND 1;
BA_ "GenSigSwitchedByIgnition" SG_ 1148 LSR_DKM_Kurzschluss_GND 0;
BA_ "GenSigSendType" SG_ 1148 LSR_DKM_Kurzschluss_GND 3;
BA_ "Fehlerwert" SG_ 1148 LSR_DKM_Kurzschluss_Ubat 1;
BA_ "GenSigSwitchedByIgnition" SG_ 1148 LSR_DKM_Kurzschluss_Ubat 0;
BA_ "GenSigSendType" SG_ 1148 LSR_DKM_Kurzschluss_Ubat 3;
BA_ "Fehlerwert" SG_ 1148 LSR_SW_inkonsistent 1;
BA_ "GenSigSwitchedByIgnition" SG_ 1148 LSR_SW_inkonsistent 0;
BA_ "GenSigSendType" SG_ 1148 LSR_SW_inkonsistent 3;
BA_ "Fehlerwert" SG_ 1148 LSR_DKM_Kurzschluss_Unterbrec000 1;
BA_ "GenSigSwitchedByIgnition" SG_ 1148 LSR_DKM_Kurzschluss_Unterbrec000 0;
BA_ "Fehlerwert" SG_ 1148 LSR_DKM_k_Hallsignal 1;
BA_ "GenSigSwitchedByIgnition" SG_ 1148 LSR_DKM_k_Hallsignal 0;
BA_ "GenSigSendType" SG_ 1148 LSR_DKM_k_Hallsignal 3;
BA_ "Fehlerwert" SG_ 1148 LSR_DKM_Ueberlastung 1;
BA_ "GenSigSwitchedByIgnition" SG_ 1148 LSR_DKM_Ueberlastung 0;
BA_ "GenSigSendType" SG_ 1148 LSR_DKM_Ueberlastung 3;
BA_ "Fehlerwert" SG_ 1148 LSR_DKM_Mech_Flauf 1;
BA_ "GenSigSwitchedByIgnition" SG_ 1148 LSR_DKM_Mech_Flauf 0;
BA_ "GenSigSendType" SG_ 1148 LSR_DKM_Mech_Flauf 3;
BA_ "Fehlerwert" SG_ 1148 LSR_DKM_El_Fehler 1;
BA_ "GenSigSwitchedByIgnition" SG_ 1148 LSR_DKM_El_Fehler 0;
BA_ "GenSigSendType" SG_ 1148 LSR_DKM_El_Fehler 3;
BA_ "GenSigSwitchedByIgnition" SG_ 1148 LSR_DKM_Manual_Operation 0;
BA_ "GenSigSwitchedByIgnition" SG_ 2583754245 LSR_1_SWDL_Req_Data 0;
BA_ "GenSigSwitchedByIgnition" SG_ 2583885317 LSR_1_SWDL_Resp_Data 0;
BA_ "GenSigSwitchedByIgnition" SG_ 1471 MFL_Tastencode_1 0;
BA_ "GenSigSendType" SG_ 1471 MFL_Tastencode_1 9;
BA_ "GenSigSwitchedByIgnition" SG_ 1471 MFL_Tastencode_2 0;
BA_ "GenSigSendType" SG_ 1471 MFL_Tastencode_2 9;
BA_ "GenSigSwitchedByIgnition" SG_ 1471 MFL_Eventcode_1 0;
BA_ "GenSigSendType" SG_ 1471 MFL_Eventcode_1 9;
BA_ "GenSigSwitchedByIgnition" SG_ 1471 MFL_Eventcode_2 0;
BA_ "GenSigSendType" SG_ 1471 MFL_Eventcode_2 9;
BA_ "GenSigSwitchedByIgnition" SG_ 1471 MFL_Marke 0;
BA_ "GenSigFuncType" SG_ 1471 MFL_Marke 8;
BA_ "GenSigSwitchedByIgnition" SG_ 1471 MFL_Variante 0;
BA_ "GenSigFuncType" SG_ 1471 MFL_Variante 8;
BA_ "GenSigSwitchedByIgnition" SG_ 2527679491 ZR_Req_TID 0;
BA_ "GenSigSendType" SG_ 2527679491 ZR_Req_TID 3;
BA_ "GenSigSwitchedByIgnition" SG_ 2527679491 ZR_Req_Quit_Info 0;
BA_ "GenSigSendType" SG_ 2527679491 ZR_Req_Quit_Info 3;
BA_ "GenSigSwitchedByIgnition" SG_ 2527679491 ZR_Req_Focus 0;
BA_ "GenSigSendType" SG_ 2527679491 ZR_Req_Focus 3;
BA_ "GenSigSwitchedByIgnition" SG_ 2527679491 ZR_Req_ScreenFormat 0;
BA_ "GenSigSendType" SG_ 2527679491 ZR_Req_ScreenFormat 3;
BA_ "GenSigSwitchedByIgnition" SG_ 2527679491 ZR_Req_MainContext 0;
BA_ "GenSigSendType" SG_ 2527679491 ZR_Req_MainContext 3;
BA_ "GenSigSwitchedByIgnition" SG_ 2527679491 ZR_Req_PopupContext 0;
BA_ "GenSigSendType" SG_ 2527679491 ZR_Req_PopupContext 3;
BA_ "GenSigSwitchedByIgnition" SG_ 2527679491 ZR_Req_MenuContext 0;
BA_ "GenSigSendType" SG_ 2527679491 ZR_Req_MenuContext 3;
BA_ "GenSigSwitchedByIgnition" SG_ 2527679490 ZR_Sta_TID 0;
BA_ "GenSigSendType" SG_ 2527679490 ZR_Sta_TID 3;
BA_ "GenSigSwitchedByIgnition" SG_ 2527679490 ZR_Sta_Animation 0;
BA_ "GenSigSendType" SG_ 2527679490 ZR_Sta_Animation 3;
BA_ "GenSigSwitchedByIgnition" SG_ 2527679490 ZR_Sta_Focus 0;
BA_ "GenSigSendType" SG_ 2527679490 ZR_Sta_Focus 3;
BA_ "GenSigSwitchedByIgnition" SG_ 2527679490 ZR_Sta_ScreenFormat 0;
BA_ "GenSigSendType" SG_ 2527679490 ZR_Sta_ScreenFormat 3;
BA_ "GenSigSwitchedByIgnition" SG_ 2527679490 ZR_Sta_MainContext 0;
BA_ "GenSigSendType" SG_ 2527679490 ZR_Sta_MainContext 3;
BA_ "GenSigSwitchedByIgnition" SG_ 2527679490 ZR_Sta_PopupContext 0;
BA_ "GenSigSendType" SG_ 2527679490 ZR_Sta_PopupContext 3;
BA_ "GenSigSwitchedByIgnition" SG_ 2527679490 ZR_Sta_MenuContext 0;
BA_ "GenSigSendType" SG_ 2527679490 ZR_Sta_MenuContext 3;
BA_ "GenSigSwitchedByIgnition" SG_ 2527679490 ZR_Sta_AnimationInfo 0;
BA_ "GenSigSendType" SG_ 2527679490 ZR_Sta_AnimationInfo 3;
BA_ "GenSigSwitchedByIgnition" SG_ 2527679490 ZR_Sta_KDKOpacity 0;
BA_ "GenSigSendType" SG_ 2527679490 ZR_Sta_KDKOpacity 3;
BA_ "GenSigSwitchedByIgnition" SG_ 2527679490 ZR_Sta_KDK_PosInfo 0;
BA_ "GenSigSendType" SG_ 2527679490 ZR_Sta_KDK_PosInfo 3;
BA_ "GenSigSwitchedByIgnition" SG_ 2527679490 ZR_Sta_NavBargraph 0;
BA_ "GenSigSendType" SG_ 2527679490 ZR_Sta_NavBargraph 3;
BA_ "GenSigSwitchedByIgnition" SG_ 2527679490 ZR_Sta_KDK 0;
BA_ "GenSigSendType" SG_ 2527679490 ZR_Sta_KDK 3;
BA_ "GenSigSwitchedByIgnition" SG_ 2527679501 ZR_Popup_TID 0;
BA_ "GenSigSendType" SG_ 2527679501 ZR_Popup_TID 3;
BA_ "GenSigSwitchedByIgnition" SG_ 2527679501 ZR_Popup_MMIPopupReqState 0;
BA_ "GenSigSendType" SG_ 2527679501 ZR_Popup_MMIPopupReqState 3;
BA_ "GenSigSwitchedByIgnition" SG_ 2527679501 ZR_Popup_MMIIDReq 0;
BA_ "GenSigSendType" SG_ 2527679501 ZR_Popup_MMIIDReq 3;
BA_ "GenSigSwitchedByIgnition" SG_ 2527679501 ZR_Popup_MMIPopupPriorityReq 0;
BA_ "GenSigSendType" SG_ 2527679501 ZR_Popup_MMIPopupPriorityReq 3;
BA_ "GenSigSwitchedByIgnition" SG_ 2527679501 ZR_Popup_ZPMSlotIDReq 0;
BA_ "GenSigSendType" SG_ 2527679501 ZR_Popup_ZPMSlotIDReq 3;
BA_ "GenSigSwitchedByIgnition" SG_ 2527679501 ZR_Popup_ScreenFormat 0;
BA_ "GenSigSendType" SG_ 2527679501 ZR_Popup_ScreenFormat 3;
BA_ "GenSigSwitchedByIgnition" SG_ 2527679501 ZR_Popup_Focus 0;
BA_ "GenSigSendType" SG_ 2527679501 ZR_Popup_Focus 3;
BA_ "GenSigSwitchedByIgnition" SG_ 2527679499 ZR_Sta_360_View 0;
BA_ "GenSigSendType" SG_ 2527679499 ZR_Sta_360_View 3;
BA_ "GenSigSwitchedByIgnition" SG_ 2527679499 ZR_Sta_Favoriten 0;
BA_ "GenSigSendType" SG_ 2527679499 ZR_Sta_Favoriten 3;
BA_ "GenSigSwitchedByIgnition" SG_ 2527679499 ZR_Sta_Laden 0;
BA_ "GenSigSendType" SG_ 2527679499 ZR_Sta_Laden 3;
BA_ "GenSigSwitchedByIgnition" SG_ 2527679499 ZR_Sta_FAS 0;
BA_ "GenSigSendType" SG_ 2527679499 ZR_Sta_FAS 3;
BA_ "GenSigSwitchedByIgnition" SG_ 2527679499 ZR_Sta_Fzg_Einst 0;
BA_ "GenSigSendType" SG_ 2527679499 ZR_Sta_Fzg_Einst 3;
BA_ "GenSigSwitchedByIgnition" SG_ 2527679499 ZR_Sta_Klima 0;
BA_ "GenSigSendType" SG_ 2527679499 ZR_Sta_Klima 3;
BA_ "GenSigSwitchedByIgnition" SG_ 2527679499 ZR_Sta_Standhzg 0;
BA_ "GenSigSendType" SG_ 2527679499 ZR_Sta_Standhzg 3;
BA_ "GenSigSwitchedByIgnition" SG_ 2527679499 ZR_Sta_Service 0;
BA_ "GenSigSendType" SG_ 2527679499 ZR_Sta_Service 3;
BA_ "GenSigSwitchedByIgnition" SG_ 2527679499 ZR_Sta_Fahrprofil 0;
BA_ "GenSigSendType" SG_ 2527679499 ZR_Sta_Fahrprofil 3;
BA_ "GenSigSwitchedByIgnition" SG_ 2527679499 ZR_Sta_Race 0;
BA_ "GenSigSendType" SG_ 2527679499 ZR_Sta_Race 3;
BA_ "GenSigSwitchedByIgnition" SG_ 2527679499 ZR_Sta_Office 0;
BA_ "GenSigSendType" SG_ 2527679499 ZR_Sta_Office 3;
BA_ "GenSigSwitchedByIgnition" SG_ 2527679499 ZR_Sta_Bordbuch 0;
BA_ "GenSigSendType" SG_ 2527679499 ZR_Sta_Bordbuch 3;
BA_ "GenSigSwitchedByIgnition" SG_ 2527679499 ZR_Sta_Profile 0;
BA_ "GenSigSendType" SG_ 2527679499 ZR_Sta_Profile 3;
BA_ "GenSigSwitchedByIgnition" SG_ 2527679499 ZR_Sta_Connect 0;
BA_ "GenSigSendType" SG_ 2527679499 ZR_Sta_Connect 3;
BA_ "GenSigSwitchedByIgnition" SG_ 2527679499 ZR_Sta_Klang 0;
BA_ "GenSigSendType" SG_ 2527679499 ZR_Sta_Klang 3;
BA_ "GenSigSwitchedByIgnition" SG_ 2527679499 ZR_Sta_Systemeinst 0;
BA_ "GenSigSendType" SG_ 2527679499 ZR_Sta_Systemeinst 3;
BA_ "GenSigSwitchedByIgnition" SG_ 2527679499 ZR_Sta_ConnectivityManager 0;
BA_ "GenSigSendType" SG_ 2527679499 ZR_Sta_ConnectivityManager 3;
BA_ "GenSigSwitchedByIgnition" SG_ 2527679499 ZR_Sta_ETC 0;
BA_ "GenSigSendType" SG_ 2527679499 ZR_Sta_ETC 3;
BA_ "GenSigSwitchedByIgnition" SG_ 2527679499 ZR_Sta_SmartPhone 0;
BA_ "GenSigSendType" SG_ 2527679499 ZR_Sta_SmartPhone 3;
BA_ "GenSigSwitchedByIgnition" SG_ 2527679499 ZR_Sta_B_Call 0;
BA_ "GenSigSendType" SG_ 2527679499 ZR_Sta_B_Call 3;
BA_ "GenSigSwitchedByIgnition" SG_ 2527679499 ZR_Sta_C_Call 0;
BA_ "GenSigSendType" SG_ 2527679499 ZR_Sta_C_Call 3;
BA_ "GenSigSwitchedByIgnition" SG_ 2527679499 ZR_Sta_VICS 0;
BA_ "GenSigSendType" SG_ 2527679499 ZR_Sta_VICS 3;
BA_ "GenSigSwitchedByIgnition" SG_ 2527679499 ZR_Sta_TPEG 0;
BA_ "GenSigSendType" SG_ 2527679499 ZR_Sta_TPEG 3;
BA_ "Fehlerwert" SG_ 1156 ND_VDOP 1023;
BA_ "GenSigSwitchedByIgnition" SG_ 1156 ND_VDOP 0;
BA_ "GenSigStartValue" SG_ 1156 ND_VDOP 1022;
BA_ "GenSigSendType" SG_ 1156 ND_VDOP 0;
BA_ "Fehlerwert" SG_ 1156 ND_TDOP 1023;
BA_ "GenSigSwitchedByIgnition" SG_ 1156 ND_TDOP 0;
BA_ "GenSigStartValue" SG_ 1156 ND_TDOP 1022;
BA_ "GenSigSendType" SG_ 1156 ND_TDOP 0;
BA_ "Fehlerwert" SG_ 1156 ND_HDOP 1023;
BA_ "GenSigSwitchedByIgnition" SG_ 1156 ND_HDOP 0;
BA_ "GenSigStartValue" SG_ 1156 ND_HDOP 1022;
BA_ "GenSigSendType" SG_ 1156 ND_HDOP 0;
BA_ "Fehlerwert" SG_ 1156 ND_GDOP 1023;
BA_ "GenSigSwitchedByIgnition" SG_ 1156 ND_GDOP 0;
BA_ "GenSigStartValue" SG_ 1156 ND_GDOP 1022;
BA_ "GenSigSendType" SG_ 1156 ND_GDOP 0;
BA_ "Fehlerwert" SG_ 1156 ND_PDOP 1023;
BA_ "GenSigSwitchedByIgnition" SG_ 1156 ND_PDOP 0;
BA_ "GenSigStartValue" SG_ 1156 ND_PDOP 1022;
BA_ "GenSigSendType" SG_ 1156 ND_PDOP 0;
BA_ "Fehlerwert" SG_ 1156 ND_Heading 4095;
BA_ "GenSigSwitchedByIgnition" SG_ 1156 ND_Heading 0;
BA_ "GenSigStartValue" SG_ 1156 ND_Heading 4094;
BA_ "GenSigSendType" SG_ 1156 ND_Heading 0;
BA_ "GenSigSwitchedByIgnition" SG_ 1156 ND_Init 0;
BA_ "GenSigSendType" SG_ 1156 ND_Init 0;
BA_ "Fehlerwert" SG_ 1157 ND_SatInUse 31;
BA_ "GenSigSwitchedByIgnition" SG_ 1157 ND_SatInUse 0;
BA_ "GenSigStartValue" SG_ 1157 ND_SatInUse 30;
BA_ "GenSigSendType" SG_ 1157 ND_SatInUse 0;
BA_ "GenSigSwitchedByIgnition" SG_ 1157 POS_Guete_horizontal_verfuegbar 0;
BA_ "GenSigSendType" SG_ 1157 POS_Guete_horizontal_verfuegbar 0;
BA_ "Fehlerwert" SG_ 1157 ND_SatInView 31;
BA_ "GenSigSwitchedByIgnition" SG_ 1157 ND_SatInView 0;
BA_ "GenSigStartValue" SG_ 1157 ND_SatInView 30;
BA_ "GenSigSendType" SG_ 1157 ND_SatInView 0;
BA_ "Fehlerwert" SG_ 1157 POS_Guete_horizontal 127;
BA_ "GenSigSwitchedByIgnition" SG_ 1157 POS_Guete_horizontal 0;
BA_ "GenSigStartValue" SG_ 1157 POS_Guete_horizontal 126;
BA_ "GenSigSendType" SG_ 1157 POS_Guete_horizontal 0;
BA_ "Fehlerwert" SG_ 1157 NP_Altitude 4095;
BA_ "GenSigSwitchedByIgnition" SG_ 1157 NP_Altitude 0;
BA_ "GenSigStartValue" SG_ 1157 NP_Altitude 4094;
BA_ "GenSigSendType" SG_ 1157 NP_Altitude 0;
BA_ "GenSigSwitchedByIgnition" SG_ 1157 ND_UTC 0;
BA_ "GenSigSendType" SG_ 1157 ND_UTC 0;
BA_ "Fehlerwert" SG_ 1158 NP_LatDegree 134217727;
BA_ "GenSigSwitchedByIgnition" SG_ 1158 NP_LatDegree 0;
BA_ "GenSigStartValue" SG_ 1158 NP_LatDegree 134217726;
BA_ "GenSigSendType" SG_ 1158 NP_LatDegree 0;
BA_ "Fehlerwert" SG_ 1158 NP_LongDegree 268435455;
BA_ "GenSigSwitchedByIgnition" SG_ 1158 NP_LongDegree 0;
BA_ "GenSigStartValue" SG_ 1158 NP_LongDegree 268435454;
BA_ "GenSigSendType" SG_ 1158 NP_LongDegree 0;
BA_ "GenSigSwitchedByIgnition" SG_ 1158 NP_LatDirection 0;
BA_ "GenSigStartValue" SG_ 1158 NP_LatDirection 1;
BA_ "GenSigSendType" SG_ 1158 NP_LatDirection 0;
BA_ "GenSigSwitchedByIgnition" SG_ 1158 NP_LongDirection 0;
BA_ "GenSigStartValue" SG_ 1158 NP_LongDirection 1;
BA_ "GenSigSendType" SG_ 1158 NP_LongDirection 0;
BA_ "Fehlerwert" SG_ 1158 NP_Sat 31;
BA_ "GenSigSwitchedByIgnition" SG_ 1158 NP_Sat 0;
BA_ "GenSigStartValue" SG_ 1158 NP_Sat 30;
BA_ "GenSigSendType" SG_ 1158 NP_Sat 0;
BA_ "GenSigSwitchedByIgnition" SG_ 1158 NP_Fix 0;
BA_ "GenSigSendType" SG_ 1158 NP_Fix 0;
BA_ "GenSigSwitchedByIgnition" SG_ 2589283496 POS_MUX 0;
BA_ "GenSigStartValue" SG_ 2589283496 POS_MUX 3;
BA_ "GenSigSendType" SG_ 2589283496 POS_MUX 0;
BA_ "GenSigSwitchedByIgnition" SG_ 2589283496 POS_ODD_EVEN 0;
BA_ "GenSigSendType" SG_ 2589283496 POS_ODD_EVEN 0;
BA_ "GenSigSwitchedByIgnition" SG_ 2589283496 POS_PosStati 0;
BA_ "GenSigSwitchedByIgnition" SG_ 2589283496 POS_Heading 0;
BA_ "GenSigSwitchedByIgnition" SG_ 2589283496 POS_LatDirection 0;
BA_ "Fehlerwert" SG_ 2589283496 POS_LatDegree 134217727;
BA_ "GenSigSwitchedByIgnition" SG_ 2589283496 POS_LatDegree 0;
BA_ "GenSigStartValue" SG_ 2589283496 POS_LatDegree 134217726;
BA_ "GenSigSwitchedByIgnition" SG_ 2589283496 POS_Last_GPS_Sync 0;
BA_ "Fehlerwert" SG_ 2589283496 POS_Heading_Trust 3;
BA_ "GenSigSwitchedByIgnition" SG_ 2589283496 POS_Heading_Trust 0;
BA_ "GenSigSwitchedByIgnition" SG_ 2589283496 POS_UTC_REF 0;
BA_ "GenSigSwitchedByIgnition" SG_ 2589283496 POS_LongDirection 0;
BA_ "Fehlerwert" SG_ 2589283496 POS_LongDegree 268435455;
BA_ "GenSigSwitchedByIgnition" SG_ 2589283496 POS_LongDegree 0;
BA_ "GenSigStartValue" SG_ 2589283496 POS_LongDegree 268435454;
BA_ "GenSigSwitchedByIgnition" SG_ 2527679647 Stellgliedtest_NFC 0;
BA_ "GenSigSendType" SG_ 2527679647 Stellgliedtest_NFC 0;
BA_ "GenSigSwitchedByIgnition" SG_ 2527679647 NFC_ESM_aktivieren 0;
BA_ "GenSigSendType" SG_ 2527679647 NFC_ESM_aktivieren 0;
BA_ "GenSigSwitchedByIgnition" SG_ 2527679647 ZV_auf_NFC 0;
BA_ "GenSigSendType" SG_ 2527679647 ZV_auf_NFC 0;
BA_ "GenSigSwitchedByIgnition" SG_ 2527679647 ZV_zu_NFC 0;
BA_ "GenSigSendType" SG_ 2527679647 ZV_zu_NFC 0;
BA_ "GenSigSwitchedByIgnition" SG_ 2527679647 MDK_Anf_Start_Auth 0;
BA_ "GenSigSwitchedByIgnition" SG_ 2527679647 MDK_BTLE_Spielschutz_aktivieren 0;
BA_ "GenSigSwitchedByIgnition" SG_ 2527679647 MDK_NFC_Spielschutz_aktivieren 0;
BA_ "GenSigSwitchedByIgnition" SG_ 2527679647 MDK_01_alt 0;
BA_ "GenSigFuncType" SG_ 2527679647 MDK_01_alt 5;
BA_ "GenSigStartValue" SG_ 2527679647 MDK_01_alt 1;
BA_ "GenSigSwitchedByIgnition" SG_ 2527679647 NFC_Front_Verr_Authorisiert 0;
BA_ "GenSigSendType" SG_ 2527679647 NFC_Front_Verr_Authorisiert 0;
BA_ "GenSigSwitchedByIgnition" SG_ 2527679647 NFC_Front_Entr_Authorisiert 0;
BA_ "GenSigSendType" SG_ 2527679647 NFC_Front_Entr_Authorisiert 0;
BA_ "GenSigSwitchedByIgnition" SG_ 2527679647 NFC_HD_Verriegelung_Authorisiert 0;
BA_ "GenSigSendType" SG_ 2527679647 NFC_HD_Verriegelung_Authorisiert 0;
BA_ "GenSigSwitchedByIgnition" SG_ 2527679647 NFC_HD_Entriegelung_Authorisiert 0;
BA_ "GenSigSendType" SG_ 2527679647 NFC_HD_Entriegelung_Authorisiert 0;
BA_ "GenSigSwitchedByIgnition" SG_ 2527679647 NFC_aktiv 0;
BA_ "GenSigSendType" SG_ 2527679647 NFC_aktiv 0;
BA_ "GenSigSwitchedByIgnition" SG_ 2527679647 NFC_Laden_unterbrechen 0;
BA_ "GenSigSendType" SG_ 2527679647 NFC_Laden_unterbrechen 0;
BA_ "GenSigSwitchedByIgnition" SG_ 2527679647 NFC_FT_Entriegelung_Authorisiert 0;
BA_ "GenSigSendType" SG_ 2527679647 NFC_FT_Entriegelung_Authorisiert 0;
BA_ "GenSigSwitchedByIgnition" SG_ 2527679647 NFC_FT_Verriegelung_Authorisiert 0;
BA_ "GenSigSendType" SG_ 2527679647 NFC_FT_Verriegelung_Authorisiert 0;
BA_ "GenSigSwitchedByIgnition" SG_ 2600468721 NM_ABT_1_SNI 0;
BA_ "GenSigStartValue" SG_ 2600468721 NM_ABT_1_SNI 241;
BA_ "GenSigSwitchedByIgnition" SG_ 2600468721 NM_ABT_1_NM_State 0;
BA_ "GenSigSwitchedByIgnition" SG_ 2600468721 NM_ABT_1_Car_Wakeup 0;
BA_ "GenSigSwitchedByIgnition" SG_ 2600468721 NM_ABT_1_Wakeup 0;
BA_ "NWM-WakeupAllowed" SG_ 2600468721 NM_ABT_1_Wakeup 1;
BA_ "GenSigSwitchedByIgnition" SG_ 2600468721 NM_ABT_1_NM_aktiv_KL15 0;
BA_ "GenSigSwitchedByIgnition" SG_ 2600468721 NM_ABT_1_NM_aktiv_Diagnose 0;
BA_ "GenSigSwitchedByIgnition" SG_ 2600468721 NM_ABT_1_NM_aktiv_Tmin 0;
BA_ "GenSigSwitchedByIgnition" SG_ 2600468721 NM_ABT_1_NL_Dimmung 0;
BA_ "GenSigSwitchedByIgnition" SG_ 2600468721 NM_ABT_1_NL_WakeUp_Lock 0;
BA_ "GenSigSwitchedByIgnition" SG_ 2600468721 NM_ABT_1_UDS_CC 0;
BA_ "GenSigSwitchedByIgnition" SG_ 2600468720 NM_BT_1_SNI 0;
BA_ "GenSigStartValue" SG_ 2600468720 NM_BT_1_SNI 240;
BA_ "GenSigSwitchedByIgnition" SG_ 2600468720 NM_BT_1_NM_State 0;
BA_ "GenSigSwitchedByIgnition" SG_ 2600468720 NM_BT_1_Car_Wakeup 0;
BA_ "GenSigSwitchedByIgnition" SG_ 2600468720 NM_BT_1_Wakeup 0;
BA_ "NWM-WakeupAllowed" SG_ 2600468720 NM_BT_1_Wakeup 1;
BA_ "GenSigSwitchedByIgnition" SG_ 2600468720 NM_BT_1_NM_aktiv_KL15 0;
BA_ "GenSigSwitchedByIgnition" SG_ 2600468720 NM_BT_1_NM_aktiv_Diagnose 0;
BA_ "GenSigSwitchedByIgnition" SG_ 2600468720 NM_BT_1_NM_aktiv_Tmin 0;
BA_ "GenSigSwitchedByIgnition" SG_ 2600468720 NM_BT_1_NL_Dimmung 0;
BA_ "GenSigSwitchedByIgnition" SG_ 2600468720 NM_BT_1_NL_WakeUp_Lock 0;
BA_ "GenSigSwitchedByIgnition" SG_ 2600468720 NM_BT_1_UDS_CC 0;
BA_ "GenSigSwitchedByIgnition" SG_ 2600468722 NM_DU_1_SNI 0;
BA_ "GenSigStartValue" SG_ 2600468722 NM_DU_1_SNI 242;
BA_ "GenSigSwitchedByIgnition" SG_ 2600468722 NM_DU_1_NM_State 0;
BA_ "GenSigSwitchedByIgnition" SG_ 2600468722 NM_DU_1_Car_Wakeup 0;
BA_ "GenSigSwitchedByIgnition" SG_ 2600468722 NM_DU_1_Wakeup 0;
BA_ "NWM-WakeupAllowed" SG_ 2600468722 NM_DU_1_Wakeup 1;
BA_ "GenSigSwitchedByIgnition" SG_ 2600468722 NM_DU_1_NM_aktiv_KL15 0;
BA_ "GenSigSwitchedByIgnition" SG_ 2600468722 NM_DU_1_NM_aktiv_Diagnose 0;
BA_ "GenSigSwitchedByIgnition" SG_ 2600468722 NM_DU_1_NM_aktiv_Tmin 0;
BA_ "GenSigSwitchedByIgnition" SG_ 2600468722 NM_DU_1_NL_Dimmung 0;
BA_ "GenSigSwitchedByIgnition" SG_ 2600468722 NM_DU_1_UDS_CC 0;
BA_ "GenSigSwitchedByIgnition" SG_ 2600468725 NM_DU_2_SNI 0;
BA_ "GenSigStartValue" SG_ 2600468725 NM_DU_2_SNI 245;
BA_ "GenSigSwitchedByIgnition" SG_ 2600468725 NM_DU_2_NM_State 0;
BA_ "GenSigSwitchedByIgnition" SG_ 2600468725 NM_DU_2_Car_Wakeup 0;
BA_ "GenSigSwitchedByIgnition" SG_ 2600468725 NM_DU_2_Wakeup 0;
BA_ "NWM-WakeupAllowed" SG_ 2600468725 NM_DU_2_Wakeup 1;
BA_ "GenSigSwitchedByIgnition" SG_ 2600468725 NM_DU_2_NM_aktiv_KL15 0;
BA_ "GenSigSwitchedByIgnition" SG_ 2600468725 NM_DU_2_NM_aktiv_Diagnose 0;
BA_ "GenSigSwitchedByIgnition" SG_ 2600468725 NM_DU_2_NM_aktiv_Tmin 0;
BA_ "GenSigSwitchedByIgnition" SG_ 2600468725 NM_DU_2_NL_Dimmung 0;
BA_ "GenSigSwitchedByIgnition" SG_ 2600468725 NM_DU_2_UDS_CC 0;
BA_ "GenSigSwitchedByIgnition" SG_ 2600468734 NM_DU_3_SNI 0;
BA_ "GenSigStartValue" SG_ 2600468734 NM_DU_3_SNI 254;
BA_ "GenSigSwitchedByIgnition" SG_ 2600468734 NM_DU_3_NM_State 0;
BA_ "GenSigSwitchedByIgnition" SG_ 2600468734 NM_DU_3_Car_Wakeup 0;
BA_ "GenSigSwitchedByIgnition" SG_ 2600468734 NM_DU_3_Wakeup 0;
BA_ "NWM-WakeupAllowed" SG_ 2600468734 NM_DU_3_Wakeup 1;
BA_ "GenSigSwitchedByIgnition" SG_ 2600468734 NM_DU_3_NM_aktiv_KL15 0;
BA_ "GenSigSwitchedByIgnition" SG_ 2600468734 NM_DU_3_NM_aktiv_Diagnose 0;
BA_ "GenSigSwitchedByIgnition" SG_ 2600468734 NM_DU_3_NM_aktiv_Tmin 0;
BA_ "GenSigSwitchedByIgnition" SG_ 2600468734 NM_DU_3_NL_Dimmung 0;
BA_ "GenSigSwitchedByIgnition" SG_ 2600468734 NM_DU_3_UDS_CC 0;
BA_ "GenSigSwitchedByIgnition" SG_ 2600468724 NM_DU_4_SNI 0;
BA_ "GenSigStartValue" SG_ 2600468724 NM_DU_4_SNI 245;
BA_ "GenSigSwitchedByIgnition" SG_ 2600468724 NM_DU_4_NM_State 0;
BA_ "GenSigSwitchedByIgnition" SG_ 2600468724 NM_DU_4_Car_Wakeup 0;
BA_ "GenSigSwitchedByIgnition" SG_ 2600468724 NM_DU_4_Wakeup 0;
BA_ "GenSigSwitchedByIgnition" SG_ 2600468724 NM_DU_4_NM_aktiv_KL15 0;
BA_ "GenSigSwitchedByIgnition" SG_ 2600468724 NM_DU_4_NM_aktiv_Diagnose 0;
BA_ "GenSigSwitchedByIgnition" SG_ 2600468724 NM_DU_4_NM_aktiv_Tmin 0;
BA_ "GenSigSwitchedByIgnition" SG_ 2600468724 NM_DU_4_NL_Dimmung 0;
BA_ "GenSigSwitchedByIgnition" SG_ 2600468724 NM_DU_4_UDS_CC 0;
BA_ "GenSigSwitchedByIgnition" SG_ 2600468723 NM_ExBox_SNI 0;
BA_ "GenSigStartValue" SG_ 2600468723 NM_ExBox_SNI 243;
BA_ "GenSigSwitchedByIgnition" SG_ 2600468723 NM_ExBox_NM_State 0;
BA_ "GenSigSwitchedByIgnition" SG_ 2600468723 NM_ExBox_Car_Wakeup 0;
BA_ "GenSigSwitchedByIgnition" SG_ 2600468723 NM_ExBox_Wakeup 0;
BA_ "NWM-WakeupAllowed" SG_ 2600468723 NM_ExBox_Wakeup 1;
BA_ "GenSigSwitchedByIgnition" SG_ 2600468723 NM_ExBox_NM_aktiv_KL15 0;
BA_ "GenSigSwitchedByIgnition" SG_ 2600468723 NM_ExBox_NM_aktiv_Diagnose 0;
BA_ "GenSigSwitchedByIgnition" SG_ 2600468723 NM_ExBox_NM_aktiv_Tmin 0;
BA_ "GenSigSwitchedByIgnition" SG_ 2600468723 NM_ExBox_UDS_CC 0;
BA_ "GenSigSwitchedByIgnition" SG_ 2600468595 NM_Info_El_SNI 0;
BA_ "GenSigStartValue" SG_ 2600468595 NM_Info_El_SNI 115;
BA_ "GenSigSwitchedByIgnition" SG_ 2600468595 NM_Info_El_NM_State 0;
BA_ "GenSigSwitchedByIgnition" SG_ 2600468595 NM_Info_El_Car_Wakeup 0;
BA_ "GenSigSwitchedByIgnition" SG_ 2600468595 NM_Info_El_Wakeup 0;
BA_ "NWM-WakeupAllowed" SG_ 2600468595 NM_Info_El_Wakeup 1;
BA_ "GenSigSwitchedByIgnition" SG_ 2600468595 NM_Info_El_NM_aktiv_KL15 0;
BA_ "GenSigSwitchedByIgnition" SG_ 2600468595 NM_Info_El_NM_aktiv_Diagnose 0;
BA_ "GenSigSwitchedByIgnition" SG_ 2600468595 NM_Info_El_NM_aktiv_Tmin 0;
BA_ "GenSigSwitchedByIgnition" SG_ 2600468595 NM_Info_El_NM_aktiv_MIBCAN 0;
BA_ "GenSigSwitchedByIgnition" SG_ 2600468595 NM_Info_El_NM_aktiv_BAP_Comm 0;
BA_ "GenSigSwitchedByIgnition" SG_ 2600468595 NM_Info_El_NL_MMI_ON 0;
BA_ "GenSigSwitchedByIgnition" SG_ 2600468595 NM_Info_El_NL_ICAN 0;
BA_ "GenSigSwitchedByIgnition" SG_ 2600468595 NM_Info_El_NL_SWDL 0;
BA_ "GenSigSwitchedByIgnition" SG_ 2600468595 NM_Info_El_NL_Dimmung 0;
BA_ "GenSigSwitchedByIgnition" SG_ 2600468595 NM_Info_El_NL_MMI_Standby 0;
BA_ "GenSigSwitchedByIgnition" SG_ 2600468595 NM_Info_El_UDS_CC 0;
BA_ "GenSigSwitchedByIgnition" SG_ 2600468500 NM_Kombi_SNI 0;
BA_ "GenSigStartValue" SG_ 2600468500 NM_Kombi_SNI 20;
BA_ "GenSigSwitchedByIgnition" SG_ 2600468500 NM_Kombi_NM_State 0;
BA_ "GenSigSwitchedByIgnition" SG_ 2600468500 NM_Kombi_Car_Wakeup 0;
BA_ "GenSigSwitchedByIgnition" SG_ 2600468500 NM_Kombi_Wakeup 0;
BA_ "NWM-WakeupAllowed" SG_ 2600468500 NM_Kombi_Wakeup 1;
BA_ "GenSigSwitchedByIgnition" SG_ 2600468500 NM_Kombi_NM_aktiv_KL15 0;
BA_ "GenSigSwitchedByIgnition" SG_ 2600468500 NM_Kombi_NM_aktiv_Diagnose 0;
BA_ "GenSigSwitchedByIgnition" SG_ 2600468500 NM_Kombi_NM_aktiv_Tmin 0;
BA_ "GenSigSwitchedByIgnition" SG_ 2600468500 NM_Kombi_NM_aktiv_Buzzer 0;
BA_ "GenSigSwitchedByIgnition" SG_ 2600468500 NM_Kombi_NM_aktiv_Schluesselkomm 0;
BA_ "GenSigSwitchedByIgnition" SG_ 2600468500 NM_Kombi_NM_aktiv_VLW 0;
BA_ "GenSigSwitchedByIgnition" SG_ 2600468500 NM_Kombi_NL_Beleuchtung 0;
BA_ "GenSigSwitchedByIgnition" SG_ 2600468500 NM_Kombi_UDS_CC 0;
BA_ "GenSigSwitchedByIgnition" SG_ 2600468726 NM_LSR_1_SNI 0;
BA_ "GenSigStartValue" SG_ 2600468726 NM_LSR_1_SNI 242;
BA_ "GenSigSwitchedByIgnition" SG_ 2600468726 NM_LSR_1_NM_State 0;
BA_ "GenSigSwitchedByIgnition" SG_ 2600468726 NM_LSR_1_Car_Wakeup 0;
BA_ "GenSigSwitchedByIgnition" SG_ 2600468726 NM_LSR_1_Wakeup 0;
BA_ "NWM-WakeupAllowed" SG_ 2600468726 NM_LSR_1_Wakeup 1;
BA_ "GenSigSwitchedByIgnition" SG_ 2600468726 NM_LSR_1_NM_aktiv_KL15 0;
BA_ "GenSigSwitchedByIgnition" SG_ 2600468726 NM_LSR_1_NM_aktiv_Diagnose 0;
BA_ "GenSigSwitchedByIgnition" SG_ 2600468726 NM_LSR_1_NM_aktiv_Tmin 0;
BA_ "GenSigSwitchedByIgnition" SG_ 2600468726 NM_LSR_1_NL_Dimmung 0;
BA_ "GenSigSwitchedByIgnition" SG_ 2600468726 NM_LSR_1_NL_WakeUp_Lock 0;
BA_ "GenSigSwitchedByIgnition" SG_ 2600468726 NM_LSR_1_UDS_CC 0;
BA_REL_ "GenSigTimeoutTime" BU_SG_REL_ ZR_High SG_ 2549088421 WLC1_Nachlauftyp 5000;
BA_REL_ "GenSigTimeoutTime" BU_SG_REL_ ZR_High_Korea SG_ 2549088421 WLC1_Nachlauftyp 5000;
BA_REL_ "GenSigTimeoutTime" BU_SG_REL_ ZR_MIB_OPTION_ab_Gen3 SG_ 2549088421 WLC1_Nachlauftyp 5000;
BA_REL_ "GenSigTimeoutTime" BU_SG_REL_ ZR_MIB_TOP_ab_Gen3 SG_ 2549088421 WLC1_Nachlauftyp 5000;
BA_REL_ "GenSigTimeoutTime" BU_SG_REL_ ZR_Standard SG_ 2549088421 WLC1_Nachlauftyp 5000;
BA_REL_ "GenSigTimeoutTime" BU_SG_REL_ ZR_High SG_ 2549088421 WLC1_SNI 5000;
BA_REL_ "GenSigTimeoutTime" BU_SG_REL_ ZR_High_Korea SG_ 2549088421 WLC1_SNI 5000;
BA_REL_ "GenSigTimeoutTime" BU_SG_REL_ ZR_MIB_OPTION_ab_Gen3 SG_ 2549088421 WLC1_SNI 5000;
BA_REL_ "GenSigTimeoutTime" BU_SG_REL_ ZR_MIB_TOP_ab_Gen3 SG_ 2549088421 WLC1_SNI 5000;
BA_REL_ "GenSigTimeoutTime" BU_SG_REL_ ZR_Standard SG_ 2549088421 WLC1_SNI 5000;
BA_REL_ "GenSigTimeoutTime" BU_SG_REL_ ZR_High SG_ 2549088421 NM_WLC1_Lokalaktiv 5000;
BA_REL_ "GenSigTimeoutTime" BU_SG_REL_ ZR_High_Korea SG_ 2549088421 NM_WLC1_Lokalaktiv 5000;
BA_REL_ "GenSigTimeoutTime" BU_SG_REL_ ZR_MIB_OPTION_ab_Gen3 SG_ 2549088421 NM_WLC1_Lokalaktiv 5000;
BA_REL_ "GenSigTimeoutTime" BU_SG_REL_ ZR_MIB_TOP_ab_Gen3 SG_ 2549088421 NM_WLC1_Lokalaktiv 5000;
BA_REL_ "GenSigTimeoutTime" BU_SG_REL_ ZR_Standard SG_ 2549088421 NM_WLC1_Lokalaktiv 5000;
BA_REL_ "GenSigTimeoutTime" BU_SG_REL_ ZR_High SG_ 2549088421 WLC1_KD_Fehler 5000;
BA_REL_ "GenSigTimeoutTime" BU_SG_REL_ ZR_High_Korea SG_ 2549088421 WLC1_KD_Fehler 5000;
BA_REL_ "GenSigTimeoutTime" BU_SG_REL_ ZR_MIB_OPTION_ab_Gen3 SG_ 2549088421 WLC1_KD_Fehler 5000;
BA_REL_ "GenSigTimeoutTime" BU_SG_REL_ ZR_MIB_TOP_ab_Gen3 SG_ 2549088421 WLC1_KD_Fehler 5000;
BA_REL_ "GenSigTimeoutTime" BU_SG_REL_ ZR_Standard SG_ 2549088421 WLC1_KD_Fehler 5000;
BA_REL_ "GenSigTimeoutTime" BU_SG_REL_ ZR_High SG_ 2549088422 WLC2_Nachlauftyp 5000;
BA_REL_ "GenSigTimeoutTime" BU_SG_REL_ ZR_High_Korea SG_ 2549088422 WLC2_Nachlauftyp 5000;
BA_REL_ "GenSigTimeoutTime" BU_SG_REL_ ZR_MIB_OPTION_ab_Gen3 SG_ 2549088422 WLC2_Nachlauftyp 5000;
BA_REL_ "GenSigTimeoutTime" BU_SG_REL_ ZR_MIB_TOP_ab_Gen3 SG_ 2549088422 WLC2_Nachlauftyp 5000;
BA_REL_ "GenSigTimeoutTime" BU_SG_REL_ ZR_Standard SG_ 2549088422 WLC2_Nachlauftyp 5000;
BA_REL_ "GenSigTimeoutTime" BU_SG_REL_ ZR_High SG_ 2549088422 WLC2_SNI 5000;
BA_REL_ "GenSigTimeoutTime" BU_SG_REL_ ZR_High_Korea SG_ 2549088422 WLC2_SNI 5000;
BA_REL_ "GenSigTimeoutTime" BU_SG_REL_ ZR_MIB_OPTION_ab_Gen3 SG_ 2549088422 WLC2_SNI 5000;
BA_REL_ "GenSigTimeoutTime" BU_SG_REL_ ZR_MIB_TOP_ab_Gen3 SG_ 2549088422 WLC2_SNI 5000;
BA_REL_ "GenSigTimeoutTime" BU_SG_REL_ ZR_Standard SG_ 2549088422 WLC2_SNI 5000;
BA_REL_ "GenSigTimeoutTime" BU_SG_REL_ ZR_High SG_ 2549088422 NM_WLC2_Lokalaktiv 5000;
BA_REL_ "GenSigTimeoutTime" BU_SG_REL_ ZR_High_Korea SG_ 2549088422 NM_WLC2_Lokalaktiv 5000;
BA_REL_ "GenSigTimeoutTime" BU_SG_REL_ ZR_MIB_OPTION_ab_Gen3 SG_ 2549088422 NM_WLC2_Lokalaktiv 5000;
BA_REL_ "GenSigTimeoutTime" BU_SG_REL_ ZR_MIB_TOP_ab_Gen3 SG_ 2549088422 NM_WLC2_Lokalaktiv 5000;
BA_REL_ "GenSigTimeoutTime" BU_SG_REL_ ZR_Standard SG_ 2549088422 NM_WLC2_Lokalaktiv 5000;
BA_REL_ "GenSigTimeoutTime" BU_SG_REL_ ZR_High SG_ 2549088422 WLC2_KD_Fehler 5000;
BA_REL_ "GenSigTimeoutTime" BU_SG_REL_ ZR_High_Korea SG_ 2549088422 WLC2_KD_Fehler 5000;
BA_REL_ "GenSigTimeoutTime" BU_SG_REL_ ZR_MIB_OPTION_ab_Gen3 SG_ 2549088422 WLC2_KD_Fehler 5000;
BA_REL_ "GenSigTimeoutTime" BU_SG_REL_ ZR_MIB_TOP_ab_Gen3 SG_ 2549088422 WLC2_KD_Fehler 5000;
BA_REL_ "GenSigTimeoutTime" BU_SG_REL_ ZR_Standard SG_ 2549088422 WLC2_KD_Fehler 5000;
BA_REL_ "GenSigTimeoutTime" BU_SG_REL_ ExBox SG_ 1720 KBI_Reifenumfang 5000;
BA_REL_ "GenSigTimeoutTime" BU_SG_REL_ ABT_1_MQB SG_ 1725 KBI_Fotosensor 5000;
BA_REL_ "GenSigTimeoutTime" BU_SG_REL_ ABT_1_MQB SG_ 1725 KBI_KL58s 5000;
BA_REL_ "GenSigTimeoutTime" BU_SG_REL_ ZR_High_TT3 SG_ 2527679493 KBI_Req_TID 5000;
BA_REL_ "GenSigTimeoutTime" BU_SG_REL_ ZR_High_TT3 SG_ 2527679493 KBI_LVDS_Lock 5000;
BA_REL_ "GenSigTimeoutTime" BU_SG_REL_ ZR_High_TT3 SG_ 2527679493 KBI_Req_Lastmode 5000;
BA_REL_ "GenSigTimeoutTime" BU_SG_REL_ ZR_High_TT3 SG_ 2527679493 KBI_Req_Focus 5000;
BA_REL_ "GenSigTimeoutTime" BU_SG_REL_ ZR_High_TT3 SG_ 2527679493 KBI_Req_ScreenFormat 5000;
BA_REL_ "GenSigTimeoutTime" BU_SG_REL_ ZR_High_TT3 SG_ 2527679493 KBI_Req_MainContext 5000;
BA_REL_ "GenSigTimeoutTime" BU_SG_REL_ ZR_High_TT3 SG_ 2527679493 KBI_Req_PopupContext 5000;
BA_REL_ "GenSigTimeoutTime" BU_SG_REL_ ZR_High_TT3 SG_ 2527679493 KBI_Req_MenuContext 5000;
BA_REL_ "GenSigTimeoutTime" BU_SG_REL_ ZR_High_TT3 SG_ 2527679493 KBI_Req_Animation_Screen_SubType 5000;
BA_REL_ "GenSigTimeoutTime" BU_SG_REL_ ZR_High_TT3 SG_ 2527679493 KBI_Req_Animation_Screen_Type 5000;
BA_REL_ "GenSigTimeoutTime" BU_SG_REL_ ZR_High_TT3 SG_ 2527679493 KBI_Req_Animation_Lead_Time 5000;
BA_REL_ "GenSigTimeoutTime" BU_SG_REL_ ZR_High_TT3 SG_ 2527679493 KBI_Req_Animation_Add_Info 5000;
BA_REL_ "GenSigTimeoutTime" BU_SG_REL_ ZR_High_TT3 SG_ 2527679492 KBI_Sta_TID 5000;
BA_REL_ "GenSigTimeoutTime" BU_SG_REL_ ZR_High_TT3 SG_ 2527679492 KBI_Sta_Animation 5000;
BA_REL_ "GenSigTimeoutTime" BU_SG_REL_ ZR_High_TT3 SG_ 2527679492 KBI_Sta_Focus 5000;
BA_REL_ "GenSigTimeoutTime" BU_SG_REL_ ZR_High_TT3 SG_ 2527679492 KBI_Sta_ScreenFormat 5000;
BA_REL_ "GenSigTimeoutTime" BU_SG_REL_ ZR_High_TT3 SG_ 2527679492 KBI_Sta_MainContext 5000;
BA_REL_ "GenSigTimeoutTime" BU_SG_REL_ ZR_High_TT3 SG_ 2527679492 KBI_Sta_PopupContext 5000;
BA_REL_ "GenSigTimeoutTime" BU_SG_REL_ ZR_High_TT3 SG_ 2527679492 KBI_Sta_MenuContext 5000;
BA_REL_ "GenSigTimeoutTime" BU_SG_REL_ ZR_High_TT3 SG_ 2527679492 KBI_Sta_Animation_Screen_SubType 5000;
BA_REL_ "GenSigTimeoutTime" BU_SG_REL_ ZR_High_TT3 SG_ 2527679492 KBI_Sta_Animation_Screen_Type 5000;
BA_REL_ "GenSigTimeoutTime" BU_SG_REL_ ZR_High_TT3 SG_ 2527679492 KBI_Sta_Animation_Lead_Time 5000;
BA_REL_ "GenSigTimeoutTime" BU_SG_REL_ ZR_High_TT3 SG_ 2527679492 KBI_Sta_Animation_Add_Info 5000;
BA_REL_ "GenSigTimeoutTime" BU_SG_REL_ ZR_High_TT3 SG_ 2527679502 KBI_Popup_TID 5000;
BA_REL_ "GenSigTimeoutTime" BU_SG_REL_ ZR_High_TT3 SG_ 2527679502 KBI_Popup_MMIPopupState 5000;
BA_REL_ "GenSigTimeoutTime" BU_SG_REL_ ZR_High_TT3 SG_ 2527679502 KBI_Popup_MMIPopupID 5000;
BA_REL_ "GenSigTimeoutTime" BU_SG_REL_ ZR_High_TT3 SG_ 2527679502 KBI_Popup_MMIPopupPriority 5000;
BA_REL_ "GenSigTimeoutTime" BU_SG_REL_ ZR_High_TT3 SG_ 2527679502 KBI_Popup_ZPMSlotID 5000;
BA_REL_ "GenSigTimeoutTime" BU_SG_REL_ ZR_High_TT3 SG_ 2527679502 KBI_Popup_ScreenFormat 5000;
BA_REL_ "GenSigTimeoutTime" BU_SG_REL_ ZR_High_TT3 SG_ 2527679502 KBI_Popup_Focus 5000;
BA_REL_ "GenSigTimeoutTime" BU_SG_REL_ ZR_High SG_ 1148 LSR_Variant 5000;
BA_REL_ "GenSigTimeoutTime" BU_SG_REL_ ZR_MIB_OPTION_ab_Gen3 SG_ 1148 LSR_Variant 5000;
BA_REL_ "GenSigTimeoutTime" BU_SG_REL_ ZR_MIB_TOP_ab_Gen3 SG_ 1148 LSR_Variant 5000;
BA_REL_ "GenSigTimeoutTime" BU_SG_REL_ ZR_Standard SG_ 1148 LSR_Variant 5000;
BA_REL_ "GenSigTimeoutTime" BU_SG_REL_ ZR_High SG_ 1148 LSR_SystemMode 5000;
BA_REL_ "GenSigTimeoutTime" BU_SG_REL_ ZR_MIB_OPTION_ab_Gen3 SG_ 1148 LSR_SystemMode 5000;
BA_REL_ "GenSigTimeoutTime" BU_SG_REL_ ZR_MIB_TOP_ab_Gen3 SG_ 1148 LSR_SystemMode 5000;
BA_REL_ "GenSigTimeoutTime" BU_SG_REL_ ZR_Standard SG_ 1148 LSR_SystemMode 5000;
BA_REL_ "GenSigTimeoutTime" BU_SG_REL_ ZR_High SG_ 1148 LSR_DKM_Kurzschluss_GND 5000;
BA_REL_ "GenSigTimeoutTime" BU_SG_REL_ ZR_MIB_OPTION_ab_Gen3 SG_ 1148 LSR_DKM_Kurzschluss_GND 5000;
BA_REL_ "GenSigTimeoutTime" BU_SG_REL_ ZR_MIB_TOP_ab_Gen3 SG_ 1148 LSR_DKM_Kurzschluss_GND 5000;
BA_REL_ "GenSigTimeoutTime" BU_SG_REL_ ZR_Standard SG_ 1148 LSR_DKM_Kurzschluss_GND 5000;
BA_REL_ "GenSigTimeoutTime" BU_SG_REL_ ZR_High SG_ 1148 LSR_DKM_Kurzschluss_Ubat 5000;
BA_REL_ "GenSigTimeoutTime" BU_SG_REL_ ZR_MIB_OPTION_ab_Gen3 SG_ 1148 LSR_DKM_Kurzschluss_Ubat 5000;
BA_REL_ "GenSigTimeoutTime" BU_SG_REL_ ZR_MIB_TOP_ab_Gen3 SG_ 1148 LSR_DKM_Kurzschluss_Ubat 5000;
BA_REL_ "GenSigTimeoutTime" BU_SG_REL_ ZR_Standard SG_ 1148 LSR_DKM_Kurzschluss_Ubat 5000;
BA_REL_ "GenSigTimeoutTime" BU_SG_REL_ ZR_High SG_ 1148 LSR_SW_inkonsistent 5000;
BA_REL_ "GenSigTimeoutTime" BU_SG_REL_ ZR_MIB_OPTION_ab_Gen3 SG_ 1148 LSR_SW_inkonsistent 5000;
BA_REL_ "GenSigTimeoutTime" BU_SG_REL_ ZR_MIB_TOP_ab_Gen3 SG_ 1148 LSR_SW_inkonsistent 5000;
BA_REL_ "GenSigTimeoutTime" BU_SG_REL_ ZR_Standard SG_ 1148 LSR_SW_inkonsistent 5000;
BA_REL_ "GenSigTimeoutTime" BU_SG_REL_ ZR_High SG_ 1148 LSR_DKM_Kurzschluss_Unterbrec000 5000;
BA_REL_ "GenSigTimeoutTime" BU_SG_REL_ ZR_MIB_OPTION_ab_Gen3 SG_ 1148 LSR_DKM_Kurzschluss_Unterbrec000 5000;
BA_REL_ "GenSigTimeoutTime" BU_SG_REL_ ZR_MIB_TOP_ab_Gen3 SG_ 1148 LSR_DKM_Kurzschluss_Unterbrec000 5000;
BA_REL_ "GenSigTimeoutTime" BU_SG_REL_ ZR_Standard SG_ 1148 LSR_DKM_Kurzschluss_Unterbrec000 5000;
BA_REL_ "GenSigTimeoutTime" BU_SG_REL_ ZR_High SG_ 1148 LSR_DKM_k_Hallsignal 5000;
BA_REL_ "GenSigTimeoutTime" BU_SG_REL_ ZR_MIB_OPTION_ab_Gen3 SG_ 1148 LSR_DKM_k_Hallsignal 5000;
BA_REL_ "GenSigTimeoutTime" BU_SG_REL_ ZR_MIB_TOP_ab_Gen3 SG_ 1148 LSR_DKM_k_Hallsignal 5000;
BA_REL_ "GenSigTimeoutTime" BU_SG_REL_ ZR_Standard SG_ 1148 LSR_DKM_k_Hallsignal 5000;
BA_REL_ "GenSigTimeoutTime" BU_SG_REL_ ZR_High SG_ 1148 LSR_DKM_Ueberlastung 5000;
BA_REL_ "GenSigTimeoutTime" BU_SG_REL_ ZR_MIB_OPTION_ab_Gen3 SG_ 1148 LSR_DKM_Ueberlastung 5000;
BA_REL_ "GenSigTimeoutTime" BU_SG_REL_ ZR_MIB_TOP_ab_Gen3 SG_ 1148 LSR_DKM_Ueberlastung 5000;
BA_REL_ "GenSigTimeoutTime" BU_SG_REL_ ZR_Standard SG_ 1148 LSR_DKM_Ueberlastung 5000;
BA_REL_ "GenSigTimeoutTime" BU_SG_REL_ ZR_High SG_ 1148 LSR_DKM_Mech_Flauf 5000;
BA_REL_ "GenSigTimeoutTime" BU_SG_REL_ ZR_MIB_OPTION_ab_Gen3 SG_ 1148 LSR_DKM_Mech_Flauf 5000;
BA_REL_ "GenSigTimeoutTime" BU_SG_REL_ ZR_MIB_TOP_ab_Gen3 SG_ 1148 LSR_DKM_Mech_Flauf 5000;
BA_REL_ "GenSigTimeoutTime" BU_SG_REL_ ZR_Standard SG_ 1148 LSR_DKM_Mech_Flauf 5000;
BA_REL_ "GenSigTimeoutTime" BU_SG_REL_ ZR_High SG_ 1148 LSR_DKM_El_Fehler 5000;
BA_REL_ "GenSigTimeoutTime" BU_SG_REL_ ZR_MIB_OPTION_ab_Gen3 SG_ 1148 LSR_DKM_El_Fehler 5000;
BA_REL_ "GenSigTimeoutTime" BU_SG_REL_ ZR_MIB_TOP_ab_Gen3 SG_ 1148 LSR_DKM_El_Fehler 5000;
BA_REL_ "GenSigTimeoutTime" BU_SG_REL_ ZR_Standard SG_ 1148 LSR_DKM_El_Fehler 5000;
BA_REL_ "GenSigTimeoutTime" BU_SG_REL_ ZR_High SG_ 1148 LSR_DKM_Manual_Operation 5000;
BA_REL_ "GenSigTimeoutTime" BU_SG_REL_ ZR_MIB_OPTION_ab_Gen3 SG_ 1148 LSR_DKM_Manual_Operation 5000;
BA_REL_ "GenSigTimeoutTime" BU_SG_REL_ ZR_MIB_TOP_ab_Gen3 SG_ 1148 LSR_DKM_Manual_Operation 5000;
BA_REL_ "GenSigTimeoutTime" BU_SG_REL_ ZR_Standard SG_ 1148 LSR_DKM_Manual_Operation 5000;
BA_REL_ "GenSigTimeoutTime" BU_SG_REL_ Kombi_TT3 SG_ 1471 MFL_Tastencode_1 5000;
BA_REL_ "GenSigTimeoutTime" BU_SG_REL_ ExBox SG_ 1471 MFL_Tastencode_2 5000;
BA_REL_ "GenSigTimeoutTime" BU_SG_REL_ Kombi_TT3 SG_ 1471 MFL_Tastencode_2 5000;
BA_REL_ "GenSigTimeoutTime" BU_SG_REL_ ExBox SG_ 1471 MFL_Eventcode_1 5000;
BA_REL_ "GenSigTimeoutTime" BU_SG_REL_ Kombi_TT3 SG_ 1471 MFL_Eventcode_1 5000;
BA_REL_ "GenSigTimeoutTime" BU_SG_REL_ ExBox SG_ 1471 MFL_Eventcode_2 5000;
BA_REL_ "GenSigTimeoutTime" BU_SG_REL_ Kombi_TT3 SG_ 1471 MFL_Eventcode_2 5000;
BA_REL_ "GenSigTimeoutTime" BU_SG_REL_ ExBox SG_ 1471 MFL_Marke 5000;
BA_REL_ "GenSigTimeoutTime" BU_SG_REL_ Kombi_TT3 SG_ 1471 MFL_Marke 5000;
BA_REL_ "GenSigTimeoutTime" BU_SG_REL_ ExBox SG_ 1471 MFL_Variante 5000;
BA_REL_ "GenSigTimeoutTime" BU_SG_REL_ Kombi_TT3 SG_ 1471 MFL_Variante 5000;
BA_REL_ "GenSigTimeoutTime" BU_SG_REL_ Kombi_TT3 SG_ 2527679491 ZR_Req_TID 5000;
BA_REL_ "GenSigTimeoutTime" BU_SG_REL_ Kombi_TT3 SG_ 2527679491 ZR_Req_Quit_Info 5000;
BA_REL_ "GenSigTimeoutTime" BU_SG_REL_ Kombi_TT3 SG_ 2527679491 ZR_Req_Focus 5000;
BA_REL_ "GenSigTimeoutTime" BU_SG_REL_ Kombi_TT3 SG_ 2527679491 ZR_Req_ScreenFormat 5000;
BA_REL_ "GenSigTimeoutTime" BU_SG_REL_ Kombi_TT3 SG_ 2527679491 ZR_Req_MainContext 5000;
BA_REL_ "GenSigTimeoutTime" BU_SG_REL_ Kombi_TT3 SG_ 2527679491 ZR_Req_PopupContext 5000;
BA_REL_ "GenSigTimeoutTime" BU_SG_REL_ Kombi_TT3 SG_ 2527679491 ZR_Req_MenuContext 5000;
BA_REL_ "GenSigTimeoutTime" BU_SG_REL_ Kombi_TT3 SG_ 2527679490 ZR_Sta_TID 5000;
BA_REL_ "GenSigTimeoutTime" BU_SG_REL_ Kombi_TT3 SG_ 2527679490 ZR_Sta_Animation 5000;
BA_REL_ "GenSigTimeoutTime" BU_SG_REL_ Kombi_TT3 SG_ 2527679490 ZR_Sta_Focus 5000;
BA_REL_ "GenSigTimeoutTime" BU_SG_REL_ Kombi_TT3 SG_ 2527679490 ZR_Sta_ScreenFormat 5000;
BA_REL_ "GenSigTimeoutTime" BU_SG_REL_ Kombi_TT3 SG_ 2527679490 ZR_Sta_MainContext 5000;
BA_REL_ "GenSigTimeoutTime" BU_SG_REL_ Kombi_TT3 SG_ 2527679490 ZR_Sta_PopupContext 5000;
BA_REL_ "GenSigTimeoutTime" BU_SG_REL_ Kombi_TT3 SG_ 2527679490 ZR_Sta_MenuContext 5000;
BA_REL_ "GenSigTimeoutTime" BU_SG_REL_ Kombi_TT3 SG_ 2527679490 ZR_Sta_AnimationInfo 5000;
BA_REL_ "GenSigTimeoutTime" BU_SG_REL_ Kombi_TT3 SG_ 2527679490 ZR_Sta_KDKOpacity 5000;
BA_REL_ "GenSigTimeoutTime" BU_SG_REL_ Kombi_TT3 SG_ 2527679490 ZR_Sta_KDK_PosInfo 5000;
BA_REL_ "GenSigTimeoutTime" BU_SG_REL_ Kombi_TT3 SG_ 2527679490 ZR_Sta_NavBargraph 5000;
BA_REL_ "GenSigTimeoutTime" BU_SG_REL_ Kombi_TT3 SG_ 2527679490 ZR_Sta_KDK 5000;
BA_REL_ "GenSigTimeoutTime" BU_SG_REL_ Kombi_TT3 SG_ 2527679501 ZR_Popup_TID 5000;
BA_REL_ "GenSigTimeoutTime" BU_SG_REL_ Kombi_TT3 SG_ 2527679501 ZR_Popup_MMIPopupReqState 5000;
BA_REL_ "GenSigTimeoutTime" BU_SG_REL_ Kombi_TT3 SG_ 2527679501 ZR_Popup_MMIIDReq 5000;
BA_REL_ "GenSigTimeoutTime" BU_SG_REL_ Kombi_TT3 SG_ 2527679501 ZR_Popup_MMIPopupPriorityReq 5000;
BA_REL_ "GenSigTimeoutTime" BU_SG_REL_ Kombi_TT3 SG_ 2527679501 ZR_Popup_ZPMSlotIDReq 5000;
BA_REL_ "GenSigTimeoutTime" BU_SG_REL_ Kombi_TT3 SG_ 2527679501 ZR_Popup_ScreenFormat 5000;
BA_REL_ "GenSigTimeoutTime" BU_SG_REL_ Kombi_TT3 SG_ 2527679501 ZR_Popup_Focus 5000;
BA_REL_ "GenSigTimeoutTime" BU_SG_REL_ Kombi_TT3 SG_ 2527679499 ZR_Sta_360_View 5000;
BA_REL_ "GenSigTimeoutTime" BU_SG_REL_ Kombi_TT3 SG_ 2527679499 ZR_Sta_Favoriten 5000;
BA_REL_ "GenSigTimeoutTime" BU_SG_REL_ Kombi_TT3 SG_ 2527679499 ZR_Sta_Laden 5000;
BA_REL_ "GenSigTimeoutTime" BU_SG_REL_ Kombi_TT3 SG_ 2527679499 ZR_Sta_FAS 5000;
BA_REL_ "GenSigTimeoutTime" BU_SG_REL_ Kombi_TT3 SG_ 2527679499 ZR_Sta_Fzg_Einst 5000;
BA_REL_ "GenSigTimeoutTime" BU_SG_REL_ Kombi_TT3 SG_ 2527679499 ZR_Sta_Klima 5000;
BA_REL_ "GenSigTimeoutTime" BU_SG_REL_ Kombi_TT3 SG_ 2527679499 ZR_Sta_Standhzg 5000;
BA_REL_ "GenSigTimeoutTime" BU_SG_REL_ Kombi_TT3 SG_ 2527679499 ZR_Sta_Service 5000;
BA_REL_ "GenSigTimeoutTime" BU_SG_REL_ Kombi_TT3 SG_ 2527679499 ZR_Sta_Fahrprofil 5000;
BA_REL_ "GenSigTimeoutTime" BU_SG_REL_ Kombi_TT3 SG_ 2527679499 ZR_Sta_Race 5000;
BA_REL_ "GenSigTimeoutTime" BU_SG_REL_ Kombi_TT3 SG_ 2527679499 ZR_Sta_Office 5000;
BA_REL_ "GenSigTimeoutTime" BU_SG_REL_ Kombi_TT3 SG_ 2527679499 ZR_Sta_Bordbuch 5000;
BA_REL_ "GenSigTimeoutTime" BU_SG_REL_ Kombi_TT3 SG_ 2527679499 ZR_Sta_Profile 5000;
BA_REL_ "GenSigTimeoutTime" BU_SG_REL_ Kombi_TT3 SG_ 2527679499 ZR_Sta_Connect 5000;
BA_REL_ "GenSigTimeoutTime" BU_SG_REL_ Kombi_TT3 SG_ 2527679499 ZR_Sta_Klang 5000;
BA_REL_ "GenSigTimeoutTime" BU_SG_REL_ Kombi_TT3 SG_ 2527679499 ZR_Sta_Systemeinst 5000;
BA_REL_ "GenSigTimeoutTime" BU_SG_REL_ Kombi_TT3 SG_ 2527679499 ZR_Sta_ConnectivityManager 5000;
BA_REL_ "GenSigTimeoutTime" BU_SG_REL_ Kombi_TT3 SG_ 2527679499 ZR_Sta_ETC 5000;
BA_REL_ "GenSigTimeoutTime" BU_SG_REL_ Kombi_TT3 SG_ 2527679499 ZR_Sta_SmartPhone 5000;
BA_REL_ "GenSigTimeoutTime" BU_SG_REL_ Kombi_TT3 SG_ 2527679499 ZR_Sta_B_Call 5000;
BA_REL_ "GenSigTimeoutTime" BU_SG_REL_ Kombi_TT3 SG_ 2527679499 ZR_Sta_C_Call 5000;
BA_REL_ "GenSigTimeoutTime" BU_SG_REL_ Kombi_TT3 SG_ 2527679499 ZR_Sta_VICS 5000;
BA_REL_ "GenSigTimeoutTime" BU_SG_REL_ Kombi_TT3 SG_ 2527679499 ZR_Sta_TPEG 5000;
BA_REL_ "GenSigTimeoutTime" BU_SG_REL_ WLC_01 SG_ 2527679647 NFC_Laden_unterbrechen 2000;
BA_REL_ "GenSigTimeoutTime" BU_SG_REL_ ABT_1_MIB_ab_Gen3 SG_ 2600468721 NM_ABT_1_NM_State 2000;
BA_REL_ "GenSigTimeoutTime" BU_SG_REL_ ABT_1_MQB SG_ 2600468721 NM_ABT_1_NM_State 2000;
BA_REL_ "GenSigTimeoutTime" BU_SG_REL_ BT_1_MQB SG_ 2600468721 NM_ABT_1_NM_State 2000;
BA_REL_ "GenSigTimeoutTime" BU_SG_REL_ DU_1_MQB SG_ 2600468721 NM_ABT_1_NM_State 2000;
BA_REL_ "GenSigTimeoutTime" BU_SG_REL_ DU_2 SG_ 2600468721 NM_ABT_1_NM_State 2000;
BA_REL_ "GenSigTimeoutTime" BU_SG_REL_ DU_3 SG_ 2600468721 NM_ABT_1_NM_State 2000;
BA_REL_ "GenSigTimeoutTime" BU_SG_REL_ DU_4 SG_ 2600468721 NM_ABT_1_NM_State 2000;
BA_REL_ "GenSigTimeoutTime" BU_SG_REL_ ExBox SG_ 2600468721 NM_ABT_1_NM_State 2000;
BA_REL_ "GenSigTimeoutTime" BU_SG_REL_ Kombi_TT3 SG_ 2600468721 NM_ABT_1_NM_State 2000;
BA_REL_ "GenSigTimeoutTime" BU_SG_REL_ LSR_1 SG_ 2600468721 NM_ABT_1_NM_State 2000;
BA_REL_ "GenSigTimeoutTime" BU_SG_REL_ SCC1 SG_ 2600468721 NM_ABT_1_NM_State 2000;
BA_REL_ "GenSigTimeoutTime" BU_SG_REL_ SCC2 SG_ 2600468721 NM_ABT_1_NM_State 2000;
BA_REL_ "GenSigTimeoutTime" BU_SG_REL_ SDC1 SG_ 2600468721 NM_ABT_1_NM_State 2000;
BA_REL_ "GenSigTimeoutTime" BU_SG_REL_ SDC2 SG_ 2600468721 NM_ABT_1_NM_State 2000;
BA_REL_ "GenSigTimeoutTime" BU_SG_REL_ SFA SG_ 2600468721 NM_ABT_1_NM_State 2000;
BA_REL_ "GenSigTimeoutTime" BU_SG_REL_ TVTuner_ab_Gen3_JPN SG_ 2600468721 NM_ABT_1_NM_State 2000;
BA_REL_ "GenSigTimeoutTime" BU_SG_REL_ WLC_01 SG_ 2600468721 NM_ABT_1_NM_State 2000;
BA_REL_ "GenSigTimeoutTime" BU_SG_REL_ WLC_02 SG_ 2600468721 NM_ABT_1_NM_State 2000;
BA_REL_ "GenSigTimeoutTime" BU_SG_REL_ ZR_Entry SG_ 2600468721 NM_ABT_1_NM_State 2000;
BA_REL_ "GenSigTimeoutTime" BU_SG_REL_ ZR_High SG_ 2600468721 NM_ABT_1_NM_State 2000;
BA_REL_ "GenSigTimeoutTime" BU_SG_REL_ ZR_High_Korea SG_ 2600468721 NM_ABT_1_NM_State 2000;
BA_REL_ "GenSigTimeoutTime" BU_SG_REL_ ZR_High_TT3 SG_ 2600468721 NM_ABT_1_NM_State 2000;
BA_REL_ "GenSigTimeoutTime" BU_SG_REL_ ZR_MIB_OPTION_ab_Gen3 SG_ 2600468721 NM_ABT_1_NM_State 2000;
BA_REL_ "GenSigTimeoutTime" BU_SG_REL_ ZR_MIB_TOP_ab_Gen3 SG_ 2600468721 NM_ABT_1_NM_State 2000;
BA_REL_ "GenSigTimeoutTime" BU_SG_REL_ ZR_Standard SG_ 2600468721 NM_ABT_1_NM_State 2000;
BA_REL_ "GenSigTimeoutTime" BU_SG_REL_ ABT_1_MIB_ab_Gen3 SG_ 2600468720 NM_BT_1_NM_State 2000;
BA_REL_ "GenSigTimeoutTime" BU_SG_REL_ ABT_1_MQB SG_ 2600468720 NM_BT_1_NM_State 2000;
BA_REL_ "GenSigTimeoutTime" BU_SG_REL_ BT_1_MQB SG_ 2600468720 NM_BT_1_NM_State 2000;
BA_REL_ "GenSigTimeoutTime" BU_SG_REL_ DU_1_MQB SG_ 2600468720 NM_BT_1_NM_State 2000;
BA_REL_ "GenSigTimeoutTime" BU_SG_REL_ DU_2 SG_ 2600468720 NM_BT_1_NM_State 2000;
BA_REL_ "GenSigTimeoutTime" BU_SG_REL_ DU_3 SG_ 2600468720 NM_BT_1_NM_State 2000;
BA_REL_ "GenSigTimeoutTime" BU_SG_REL_ DU_4 SG_ 2600468720 NM_BT_1_NM_State 2000;
BA_REL_ "GenSigTimeoutTime" BU_SG_REL_ ExBox SG_ 2600468720 NM_BT_1_NM_State 2000;
BA_REL_ "GenSigTimeoutTime" BU_SG_REL_ Kombi_TT3 SG_ 2600468720 NM_BT_1_NM_State 2000;
BA_REL_ "GenSigTimeoutTime" BU_SG_REL_ LSR_1 SG_ 2600468720 NM_BT_1_NM_State 2000;
BA_REL_ "GenSigTimeoutTime" BU_SG_REL_ SCC1 SG_ 2600468720 NM_BT_1_NM_State 2000;
BA_REL_ "GenSigTimeoutTime" BU_SG_REL_ SCC2 SG_ 2600468720 NM_BT_1_NM_State 2000;
BA_REL_ "GenSigTimeoutTime" BU_SG_REL_ SDC1 SG_ 2600468720 NM_BT_1_NM_State 2000;
BA_REL_ "GenSigTimeoutTime" BU_SG_REL_ SDC2 SG_ 2600468720 NM_BT_1_NM_State 2000;
BA_REL_ "GenSigTimeoutTime" BU_SG_REL_ SFA SG_ 2600468720 NM_BT_1_NM_State 2000;
BA_REL_ "GenSigTimeoutTime" BU_SG_REL_ TVTuner_ab_Gen3_JPN SG_ 2600468720 NM_BT_1_NM_State 2000;
BA_REL_ "GenSigTimeoutTime" BU_SG_REL_ WLC_01 SG_ 2600468720 NM_BT_1_NM_State 2000;
BA_REL_ "GenSigTimeoutTime" BU_SG_REL_ WLC_02 SG_ 2600468720 NM_BT_1_NM_State 2000;
BA_REL_ "GenSigTimeoutTime" BU_SG_REL_ ZR_Entry SG_ 2600468720 NM_BT_1_NM_State 2000;
BA_REL_ "GenSigTimeoutTime" BU_SG_REL_ ZR_High SG_ 2600468720 NM_BT_1_NM_State 2000;
BA_REL_ "GenSigTimeoutTime" BU_SG_REL_ ZR_High_Korea SG_ 2600468720 NM_BT_1_NM_State 2000;
BA_REL_ "GenSigTimeoutTime" BU_SG_REL_ ZR_High_TT3 SG_ 2600468720 NM_BT_1_NM_State 2000;
BA_REL_ "GenSigTimeoutTime" BU_SG_REL_ ZR_MIB_OPTION_ab_Gen3 SG_ 2600468720 NM_BT_1_NM_State 2000;
BA_REL_ "GenSigTimeoutTime" BU_SG_REL_ ZR_MIB_TOP_ab_Gen3 SG_ 2600468720 NM_BT_1_NM_State 2000;
BA_REL_ "GenSigTimeoutTime" BU_SG_REL_ ZR_Standard SG_ 2600468720 NM_BT_1_NM_State 2000;
BA_REL_ "GenSigTimeoutTime" BU_SG_REL_ ABT_1_MIB_ab_Gen3 SG_ 2600468722 NM_DU_1_NM_State 2000;
BA_REL_ "GenSigTimeoutTime" BU_SG_REL_ ABT_1_MQB SG_ 2600468722 NM_DU_1_NM_State 2000;
BA_REL_ "GenSigTimeoutTime" BU_SG_REL_ BT_1_MQB SG_ 2600468722 NM_DU_1_NM_State 2000;
BA_REL_ "GenSigTimeoutTime" BU_SG_REL_ DU_1_MQB SG_ 2600468722 NM_DU_1_NM_State 2000;
BA_REL_ "GenSigTimeoutTime" BU_SG_REL_ DU_2 SG_ 2600468722 NM_DU_1_NM_State 2000;
BA_REL_ "GenSigTimeoutTime" BU_SG_REL_ DU_3 SG_ 2600468722 NM_DU_1_NM_State 2000;
BA_REL_ "GenSigTimeoutTime" BU_SG_REL_ DU_4 SG_ 2600468722 NM_DU_1_NM_State 2000;
BA_REL_ "GenSigTimeoutTime" BU_SG_REL_ ExBox SG_ 2600468722 NM_DU_1_NM_State 2000;
BA_REL_ "GenSigTimeoutTime" BU_SG_REL_ Kombi_TT3 SG_ 2600468722 NM_DU_1_NM_State 2000;
BA_REL_ "GenSigTimeoutTime" BU_SG_REL_ LSR_1 SG_ 2600468722 NM_DU_1_NM_State 2000;
BA_REL_ "GenSigTimeoutTime" BU_SG_REL_ SCC1 SG_ 2600468722 NM_DU_1_NM_State 2000;
BA_REL_ "GenSigTimeoutTime" BU_SG_REL_ SCC2 SG_ 2600468722 NM_DU_1_NM_State 2000;
BA_REL_ "GenSigTimeoutTime" BU_SG_REL_ SDC1 SG_ 2600468722 NM_DU_1_NM_State 2000;
BA_REL_ "GenSigTimeoutTime" BU_SG_REL_ SDC2 SG_ 2600468722 NM_DU_1_NM_State 2000;
BA_REL_ "GenSigTimeoutTime" BU_SG_REL_ SFA SG_ 2600468722 NM_DU_1_NM_State 2000;
BA_REL_ "GenSigTimeoutTime" BU_SG_REL_ TVTuner_ab_Gen3_JPN SG_ 2600468722 NM_DU_1_NM_State 2000;
BA_REL_ "GenSigTimeoutTime" BU_SG_REL_ WLC_01 SG_ 2600468722 NM_DU_1_NM_State 2000;
BA_REL_ "GenSigTimeoutTime" BU_SG_REL_ WLC_02 SG_ 2600468722 NM_DU_1_NM_State 2000;
BA_REL_ "GenSigTimeoutTime" BU_SG_REL_ ZR_Entry SG_ 2600468722 NM_DU_1_NM_State 2000;
BA_REL_ "GenSigTimeoutTime" BU_SG_REL_ ZR_High SG_ 2600468722 NM_DU_1_NM_State 2000;
BA_REL_ "GenSigTimeoutTime" BU_SG_REL_ ZR_High_Korea SG_ 2600468722 NM_DU_1_NM_State 2000;
BA_REL_ "GenSigTimeoutTime" BU_SG_REL_ ZR_High_TT3 SG_ 2600468722 NM_DU_1_NM_State 2000;
BA_REL_ "GenSigTimeoutTime" BU_SG_REL_ ZR_MIB_OPTION_ab_Gen3 SG_ 2600468722 NM_DU_1_NM_State 2000;
BA_REL_ "GenSigTimeoutTime" BU_SG_REL_ ZR_MIB_TOP_ab_Gen3 SG_ 2600468722 NM_DU_1_NM_State 2000;
BA_REL_ "GenSigTimeoutTime" BU_SG_REL_ ZR_Standard SG_ 2600468722 NM_DU_1_NM_State 2000;
BA_REL_ "GenSigTimeoutTime" BU_SG_REL_ ABT_1_MIB_ab_Gen3 SG_ 2600468725 NM_DU_2_NM_State 2000;
BA_REL_ "GenSigTimeoutTime" BU_SG_REL_ ABT_1_MQB SG_ 2600468725 NM_DU_2_NM_State 2000;
BA_REL_ "GenSigTimeoutTime" BU_SG_REL_ BT_1_MQB SG_ 2600468725 NM_DU_2_NM_State 2000;
BA_REL_ "GenSigTimeoutTime" BU_SG_REL_ DU_1_MQB SG_ 2600468725 NM_DU_2_NM_State 2000;
BA_REL_ "GenSigTimeoutTime" BU_SG_REL_ DU_2 SG_ 2600468725 NM_DU_2_NM_State 2000;
BA_REL_ "GenSigTimeoutTime" BU_SG_REL_ DU_3 SG_ 2600468725 NM_DU_2_NM_State 2000;
BA_REL_ "GenSigTimeoutTime" BU_SG_REL_ DU_4 SG_ 2600468725 NM_DU_2_NM_State 2000;
BA_REL_ "GenSigTimeoutTime" BU_SG_REL_ ExBox SG_ 2600468725 NM_DU_2_NM_State 2000;
BA_REL_ "GenSigTimeoutTime" BU_SG_REL_ Kombi_TT3 SG_ 2600468725 NM_DU_2_NM_State 2000;
BA_REL_ "GenSigTimeoutTime" BU_SG_REL_ LSR_1 SG_ 2600468725 NM_DU_2_NM_State 2000;
BA_REL_ "GenSigTimeoutTime" BU_SG_REL_ SCC1 SG_ 2600468725 NM_DU_2_NM_State 2000;
BA_REL_ "GenSigTimeoutTime" BU_SG_REL_ SCC2 SG_ 2600468725 NM_DU_2_NM_State 2000;
BA_REL_ "GenSigTimeoutTime" BU_SG_REL_ SDC1 SG_ 2600468725 NM_DU_2_NM_State 2000;
BA_REL_ "GenSigTimeoutTime" BU_SG_REL_ SDC2 SG_ 2600468725 NM_DU_2_NM_State 2000;
BA_REL_ "GenSigTimeoutTime" BU_SG_REL_ SFA SG_ 2600468725 NM_DU_2_NM_State 2000;
BA_REL_ "GenSigTimeoutTime" BU_SG_REL_ TVTuner_ab_Gen3_JPN SG_ 2600468725 NM_DU_2_NM_State 2000;
BA_REL_ "GenSigTimeoutTime" BU_SG_REL_ WLC_01 SG_ 2600468725 NM_DU_2_NM_State 2000;
BA_REL_ "GenSigTimeoutTime" BU_SG_REL_ WLC_02 SG_ 2600468725 NM_DU_2_NM_State 2000;
BA_REL_ "GenSigTimeoutTime" BU_SG_REL_ ZR_Entry SG_ 2600468725 NM_DU_2_NM_State 2000;
BA_REL_ "GenSigTimeoutTime" BU_SG_REL_ ZR_High SG_ 2600468725 NM_DU_2_NM_State 2000;
BA_REL_ "GenSigTimeoutTime" BU_SG_REL_ ZR_High_Korea SG_ 2600468725 NM_DU_2_NM_State 2000;
BA_REL_ "GenSigTimeoutTime" BU_SG_REL_ ZR_High_TT3 SG_ 2600468725 NM_DU_2_NM_State 2000;
BA_REL_ "GenSigTimeoutTime" BU_SG_REL_ ZR_MIB_OPTION_ab_Gen3 SG_ 2600468725 NM_DU_2_NM_State 2000;
BA_REL_ "GenSigTimeoutTime" BU_SG_REL_ ZR_MIB_TOP_ab_Gen3 SG_ 2600468725 NM_DU_2_NM_State 2000;
BA_REL_ "GenSigTimeoutTime" BU_SG_REL_ ZR_Standard SG_ 2600468725 NM_DU_2_NM_State 2000;
BA_REL_ "GenSigTimeoutTime" BU_SG_REL_ ABT_1_MIB_ab_Gen3 SG_ 2600468734 NM_DU_3_NM_State 2000;
BA_REL_ "GenSigTimeoutTime" BU_SG_REL_ ABT_1_MQB SG_ 2600468734 NM_DU_3_NM_State 2000;
BA_REL_ "GenSigTimeoutTime" BU_SG_REL_ BT_1_MQB SG_ 2600468734 NM_DU_3_NM_State 2000;
BA_REL_ "GenSigTimeoutTime" BU_SG_REL_ DU_1_MQB SG_ 2600468734 NM_DU_3_NM_State 2000;
BA_REL_ "GenSigTimeoutTime" BU_SG_REL_ DU_2 SG_ 2600468734 NM_DU_3_NM_State 2000;
BA_REL_ "GenSigTimeoutTime" BU_SG_REL_ DU_3 SG_ 2600468734 NM_DU_3_NM_State 2000;
BA_REL_ "GenSigTimeoutTime" BU_SG_REL_ DU_4 SG_ 2600468734 NM_DU_3_NM_State 2000;
BA_REL_ "GenSigTimeoutTime" BU_SG_REL_ ExBox SG_ 2600468734 NM_DU_3_NM_State 2000;
BA_REL_ "GenSigTimeoutTime" BU_SG_REL_ Kombi_TT3 SG_ 2600468734 NM_DU_3_NM_State 2000;
BA_REL_ "GenSigTimeoutTime" BU_SG_REL_ LSR_1 SG_ 2600468734 NM_DU_3_NM_State 2000;
BA_REL_ "GenSigTimeoutTime" BU_SG_REL_ SCC1 SG_ 2600468734 NM_DU_3_NM_State 2000;
BA_REL_ "GenSigTimeoutTime" BU_SG_REL_ SCC2 SG_ 2600468734 NM_DU_3_NM_State 2000;
BA_REL_ "GenSigTimeoutTime" BU_SG_REL_ SDC1 SG_ 2600468734 NM_DU_3_NM_State 2000;
BA_REL_ "GenSigTimeoutTime" BU_SG_REL_ SDC2 SG_ 2600468734 NM_DU_3_NM_State 2000;
BA_REL_ "GenSigTimeoutTime" BU_SG_REL_ SFA SG_ 2600468734 NM_DU_3_NM_State 2000;
BA_REL_ "GenSigTimeoutTime" BU_SG_REL_ TVTuner_ab_Gen3_JPN SG_ 2600468734 NM_DU_3_NM_State 2000;
BA_REL_ "GenSigTimeoutTime" BU_SG_REL_ WLC_01 SG_ 2600468734 NM_DU_3_NM_State 2000;
BA_REL_ "GenSigTimeoutTime" BU_SG_REL_ WLC_02 SG_ 2600468734 NM_DU_3_NM_State 2000;
BA_REL_ "GenSigTimeoutTime" BU_SG_REL_ ZR_Entry SG_ 2600468734 NM_DU_3_NM_State 2000;
BA_REL_ "GenSigTimeoutTime" BU_SG_REL_ ZR_High SG_ 2600468734 NM_DU_3_NM_State 2000;
BA_REL_ "GenSigTimeoutTime" BU_SG_REL_ ZR_High_Korea SG_ 2600468734 NM_DU_3_NM_State 2000;
BA_REL_ "GenSigTimeoutTime" BU_SG_REL_ ZR_High_TT3 SG_ 2600468734 NM_DU_3_NM_State 2000;
BA_REL_ "GenSigTimeoutTime" BU_SG_REL_ ZR_MIB_OPTION_ab_Gen3 SG_ 2600468734 NM_DU_3_NM_State 2000;
BA_REL_ "GenSigTimeoutTime" BU_SG_REL_ ZR_MIB_TOP_ab_Gen3 SG_ 2600468734 NM_DU_3_NM_State 2000;
BA_REL_ "GenSigTimeoutTime" BU_SG_REL_ ZR_Standard SG_ 2600468734 NM_DU_3_NM_State 2000;
BA_REL_ "GenSigTimeoutTime" BU_SG_REL_ ABT_1_MIB_ab_Gen3 SG_ 2600468724 NM_DU_4_NM_State 2000;
BA_REL_ "GenSigTimeoutTime" BU_SG_REL_ ABT_1_MQB SG_ 2600468724 NM_DU_4_NM_State 2000;
BA_REL_ "GenSigTimeoutTime" BU_SG_REL_ BT_1_MQB SG_ 2600468724 NM_DU_4_NM_State 2000;
BA_REL_ "GenSigTimeoutTime" BU_SG_REL_ DU_1_MQB SG_ 2600468724 NM_DU_4_NM_State 2000;
BA_REL_ "GenSigTimeoutTime" BU_SG_REL_ DU_2 SG_ 2600468724 NM_DU_4_NM_State 2000;
BA_REL_ "GenSigTimeoutTime" BU_SG_REL_ DU_3 SG_ 2600468724 NM_DU_4_NM_State 2000;
BA_REL_ "GenSigTimeoutTime" BU_SG_REL_ DU_4 SG_ 2600468724 NM_DU_4_NM_State 2000;
BA_REL_ "GenSigTimeoutTime" BU_SG_REL_ ExBox SG_ 2600468724 NM_DU_4_NM_State 2000;
BA_REL_ "GenSigTimeoutTime" BU_SG_REL_ Kombi_TT3 SG_ 2600468724 NM_DU_4_NM_State 2000;
BA_REL_ "GenSigTimeoutTime" BU_SG_REL_ LSR_1 SG_ 2600468724 NM_DU_4_NM_State 2000;
BA_REL_ "GenSigTimeoutTime" BU_SG_REL_ SCC1 SG_ 2600468724 NM_DU_4_NM_State 2000;
BA_REL_ "GenSigTimeoutTime" BU_SG_REL_ SCC1 SG_ 2600468724 NM_DU_4_NM_State 2000;
BA_REL_ "GenSigTimeoutTime" BU_SG_REL_ SCC2 SG_ 2600468724 NM_DU_4_NM_State 2000;
BA_REL_ "GenSigTimeoutTime" BU_SG_REL_ SCC2 SG_ 2600468724 NM_DU_4_NM_State 2000;
BA_REL_ "GenSigTimeoutTime" BU_SG_REL_ SDC1 SG_ 2600468724 NM_DU_4_NM_State 2000;
BA_REL_ "GenSigTimeoutTime" BU_SG_REL_ SDC1 SG_ 2600468724 NM_DU_4_NM_State 2000;
BA_REL_ "GenSigTimeoutTime" BU_SG_REL_ SDC2 SG_ 2600468724 NM_DU_4_NM_State 2000;
BA_REL_ "GenSigTimeoutTime" BU_SG_REL_ SFA SG_ 2600468724 NM_DU_4_NM_State 2000;
BA_REL_ "GenSigTimeoutTime" BU_SG_REL_ TVTuner_ab_Gen3_JPN SG_ 2600468724 NM_DU_4_NM_State 2000;
BA_REL_ "GenSigTimeoutTime" BU_SG_REL_ WLC_01 SG_ 2600468724 NM_DU_4_NM_State 2000;
BA_REL_ "GenSigTimeoutTime" BU_SG_REL_ WLC_02 SG_ 2600468724 NM_DU_4_NM_State 2000;
BA_REL_ "GenSigTimeoutTime" BU_SG_REL_ ZR_Entry SG_ 2600468724 NM_DU_4_NM_State 2000;
BA_REL_ "GenSigTimeoutTime" BU_SG_REL_ ZR_High SG_ 2600468724 NM_DU_4_NM_State 2000;
BA_REL_ "GenSigTimeoutTime" BU_SG_REL_ ZR_High_Korea SG_ 2600468724 NM_DU_4_NM_State 2000;
BA_REL_ "GenSigTimeoutTime" BU_SG_REL_ ZR_High_TT3 SG_ 2600468724 NM_DU_4_NM_State 2000;
BA_REL_ "GenSigTimeoutTime" BU_SG_REL_ ZR_MIB_OPTION_ab_Gen3 SG_ 2600468724 NM_DU_4_NM_State 2000;
BA_REL_ "GenSigTimeoutTime" BU_SG_REL_ ZR_MIB_TOP_ab_Gen3 SG_ 2600468724 NM_DU_4_NM_State 2000;
BA_REL_ "GenSigTimeoutTime" BU_SG_REL_ ZR_Standard SG_ 2600468724 NM_DU_4_NM_State 2000;
BA_REL_ "GenSigTimeoutTime" BU_SG_REL_ ABT_1_MIB_ab_Gen3 SG_ 2600468723 NM_ExBox_NM_State 2000;
BA_REL_ "GenSigTimeoutTime" BU_SG_REL_ ABT_1_MQB SG_ 2600468723 NM_ExBox_NM_State 2000;
BA_REL_ "GenSigTimeoutTime" BU_SG_REL_ BT_1_MQB SG_ 2600468723 NM_ExBox_NM_State 2000;
BA_REL_ "GenSigTimeoutTime" BU_SG_REL_ DU_1_MQB SG_ 2600468723 NM_ExBox_NM_State 2000;
BA_REL_ "GenSigTimeoutTime" BU_SG_REL_ DU_2 SG_ 2600468723 NM_ExBox_NM_State 2000;
BA_REL_ "GenSigTimeoutTime" BU_SG_REL_ DU_3 SG_ 2600468723 NM_ExBox_NM_State 2000;
BA_REL_ "GenSigTimeoutTime" BU_SG_REL_ DU_4 SG_ 2600468723 NM_ExBox_NM_State 2000;
BA_REL_ "GenSigTimeoutTime" BU_SG_REL_ ExBox SG_ 2600468723 NM_ExBox_NM_State 2000;
BA_REL_ "GenSigTimeoutTime" BU_SG_REL_ Kombi_TT3 SG_ 2600468723 NM_ExBox_NM_State 2000;
BA_REL_ "GenSigTimeoutTime" BU_SG_REL_ LSR_1 SG_ 2600468723 NM_ExBox_NM_State 2000;
BA_REL_ "GenSigTimeoutTime" BU_SG_REL_ SCC1 SG_ 2600468723 NM_ExBox_NM_State 2000;
BA_REL_ "GenSigTimeoutTime" BU_SG_REL_ SCC2 SG_ 2600468723 NM_ExBox_NM_State 2000;
BA_REL_ "GenSigTimeoutTime" BU_SG_REL_ SDC1 SG_ 2600468723 NM_ExBox_NM_State 2000;
BA_REL_ "GenSigTimeoutTime" BU_SG_REL_ SDC2 SG_ 2600468723 NM_ExBox_NM_State 2000;
BA_REL_ "GenSigTimeoutTime" BU_SG_REL_ SFA SG_ 2600468723 NM_ExBox_NM_State 2000;
BA_REL_ "GenSigTimeoutTime" BU_SG_REL_ TVTuner_ab_Gen3_JPN SG_ 2600468723 NM_ExBox_NM_State 2000;
BA_REL_ "GenSigTimeoutTime" BU_SG_REL_ WLC_01 SG_ 2600468723 NM_ExBox_NM_State 2000;
BA_REL_ "GenSigTimeoutTime" BU_SG_REL_ WLC_02 SG_ 2600468723 NM_ExBox_NM_State 2000;
BA_REL_ "GenSigTimeoutTime" BU_SG_REL_ ZR_Entry SG_ 2600468723 NM_ExBox_NM_State 2000;
BA_REL_ "GenSigTimeoutTime" BU_SG_REL_ ZR_High SG_ 2600468723 NM_ExBox_NM_State 2000;
BA_REL_ "GenSigTimeoutTime" BU_SG_REL_ ZR_High_Korea SG_ 2600468723 NM_ExBox_NM_State 2000;
BA_REL_ "GenSigTimeoutTime" BU_SG_REL_ ZR_High_TT3 SG_ 2600468723 NM_ExBox_NM_State 2000;
BA_REL_ "GenSigTimeoutTime" BU_SG_REL_ ZR_MIB_OPTION_ab_Gen3 SG_ 2600468723 NM_ExBox_NM_State 2000;
BA_REL_ "GenSigTimeoutTime" BU_SG_REL_ ZR_MIB_TOP_ab_Gen3 SG_ 2600468723 NM_ExBox_NM_State 2000;
BA_REL_ "GenSigTimeoutTime" BU_SG_REL_ ZR_Standard SG_ 2600468723 NM_ExBox_NM_State 2000;
BA_REL_ "GenSigTimeoutTime" BU_SG_REL_ ABT_1_MIB_ab_Gen3 SG_ 2600468595 NM_Info_El_NM_State 2000;
BA_REL_ "GenSigTimeoutTime" BU_SG_REL_ ABT_1_MQB SG_ 2600468595 NM_Info_El_NM_State 2000;
BA_REL_ "GenSigTimeoutTime" BU_SG_REL_ BT_1_MQB SG_ 2600468595 NM_Info_El_NM_State 2000;
BA_REL_ "GenSigTimeoutTime" BU_SG_REL_ DU_1_MQB SG_ 2600468595 NM_Info_El_NM_State 2000;
BA_REL_ "GenSigTimeoutTime" BU_SG_REL_ DU_2 SG_ 2600468595 NM_Info_El_NM_State 2000;
BA_REL_ "GenSigTimeoutTime" BU_SG_REL_ DU_3 SG_ 2600468595 NM_Info_El_NM_State 2000;
BA_REL_ "GenSigTimeoutTime" BU_SG_REL_ DU_4 SG_ 2600468595 NM_Info_El_NM_State 2000;
BA_REL_ "GenSigTimeoutTime" BU_SG_REL_ ExBox SG_ 2600468595 NM_Info_El_NM_State 2000;
BA_REL_ "GenSigTimeoutTime" BU_SG_REL_ Kombi_TT3 SG_ 2600468595 NM_Info_El_NM_State 2000;
BA_REL_ "GenSigTimeoutTime" BU_SG_REL_ LSR_1 SG_ 2600468595 NM_Info_El_NM_State 2000;
BA_REL_ "GenSigTimeoutTime" BU_SG_REL_ SCC1 SG_ 2600468595 NM_Info_El_NM_State 2000;
BA_REL_ "GenSigTimeoutTime" BU_SG_REL_ SCC2 SG_ 2600468595 NM_Info_El_NM_State 2000;
BA_REL_ "GenSigTimeoutTime" BU_SG_REL_ SDC1 SG_ 2600468595 NM_Info_El_NM_State 2000;
BA_REL_ "GenSigTimeoutTime" BU_SG_REL_ SDC2 SG_ 2600468595 NM_Info_El_NM_State 2000;
BA_REL_ "GenSigTimeoutTime" BU_SG_REL_ SFA SG_ 2600468595 NM_Info_El_NM_State 2000;
BA_REL_ "GenSigTimeoutTime" BU_SG_REL_ TVTuner_ab_Gen3_JPN SG_ 2600468595 NM_Info_El_NM_State 2000;
BA_REL_ "GenSigTimeoutTime" BU_SG_REL_ WLC_01 SG_ 2600468595 NM_Info_El_NM_State 2000;
BA_REL_ "GenSigTimeoutTime" BU_SG_REL_ WLC_02 SG_ 2600468595 NM_Info_El_NM_State 2000;
BA_REL_ "GenSigTimeoutTime" BU_SG_REL_ ZR_Entry SG_ 2600468595 NM_Info_El_NM_State 2000;
BA_REL_ "GenSigTimeoutTime" BU_SG_REL_ ZR_High SG_ 2600468595 NM_Info_El_NM_State 2000;
BA_REL_ "GenSigTimeoutTime" BU_SG_REL_ ZR_High_Korea SG_ 2600468595 NM_Info_El_NM_State 2000;
BA_REL_ "GenSigTimeoutTime" BU_SG_REL_ ZR_High_TT3 SG_ 2600468595 NM_Info_El_NM_State 2000;
BA_REL_ "GenSigTimeoutTime" BU_SG_REL_ ZR_MIB_OPTION_ab_Gen3 SG_ 2600468595 NM_Info_El_NM_State 2000;
BA_REL_ "GenSigTimeoutTime" BU_SG_REL_ ZR_MIB_TOP_ab_Gen3 SG_ 2600468595 NM_Info_El_NM_State 2000;
BA_REL_ "GenSigTimeoutTime" BU_SG_REL_ ZR_Standard SG_ 2600468595 NM_Info_El_NM_State 2000;
BA_REL_ "GenSigTimeoutTime" BU_SG_REL_ ABT_1_MIB_ab_Gen3 SG_ 2600468500 NM_Kombi_NM_State 2000;
BA_REL_ "GenSigTimeoutTime" BU_SG_REL_ ABT_1_MQB SG_ 2600468500 NM_Kombi_NM_State 2000;
BA_REL_ "GenSigTimeoutTime" BU_SG_REL_ BT_1_MQB SG_ 2600468500 NM_Kombi_NM_State 2000;
BA_REL_ "GenSigTimeoutTime" BU_SG_REL_ DU_1_MQB SG_ 2600468500 NM_Kombi_NM_State 2000;
BA_REL_ "GenSigTimeoutTime" BU_SG_REL_ DU_2 SG_ 2600468500 NM_Kombi_NM_State 2000;
BA_REL_ "GenSigTimeoutTime" BU_SG_REL_ DU_3 SG_ 2600468500 NM_Kombi_NM_State 2000;
BA_REL_ "GenSigTimeoutTime" BU_SG_REL_ DU_4 SG_ 2600468500 NM_Kombi_NM_State 2000;
BA_REL_ "GenSigTimeoutTime" BU_SG_REL_ ExBox SG_ 2600468500 NM_Kombi_NM_State 2000;
BA_REL_ "GenSigTimeoutTime" BU_SG_REL_ Kombi_TT3 SG_ 2600468500 NM_Kombi_NM_State 2000;
BA_REL_ "GenSigTimeoutTime" BU_SG_REL_ LSR_1 SG_ 2600468500 NM_Kombi_NM_State 2000;
BA_REL_ "GenSigTimeoutTime" BU_SG_REL_ SCC1 SG_ 2600468500 NM_Kombi_NM_State 2000;
BA_REL_ "GenSigTimeoutTime" BU_SG_REL_ SCC2 SG_ 2600468500 NM_Kombi_NM_State 2000;
BA_REL_ "GenSigTimeoutTime" BU_SG_REL_ SDC1 SG_ 2600468500 NM_Kombi_NM_State 2000;
BA_REL_ "GenSigTimeoutTime" BU_SG_REL_ SDC2 SG_ 2600468500 NM_Kombi_NM_State 2000;
BA_REL_ "GenSigTimeoutTime" BU_SG_REL_ SFA SG_ 2600468500 NM_Kombi_NM_State 2000;
BA_REL_ "GenSigTimeoutTime" BU_SG_REL_ TVTuner_ab_Gen3_JPN SG_ 2600468500 NM_Kombi_NM_State 2000;
BA_REL_ "GenSigTimeoutTime" BU_SG_REL_ WLC_01 SG_ 2600468500 NM_Kombi_NM_State 2000;
BA_REL_ "GenSigTimeoutTime" BU_SG_REL_ WLC_02 SG_ 2600468500 NM_Kombi_NM_State 2000;
BA_REL_ "GenSigTimeoutTime" BU_SG_REL_ ZR_Entry SG_ 2600468500 NM_Kombi_NM_State 2000;
BA_REL_ "GenSigTimeoutTime" BU_SG_REL_ ZR_High SG_ 2600468500 NM_Kombi_NM_State 2000;
BA_REL_ "GenSigTimeoutTime" BU_SG_REL_ ZR_High_Korea SG_ 2600468500 NM_Kombi_NM_State 2000;
BA_REL_ "GenSigTimeoutTime" BU_SG_REL_ ZR_High_TT3 SG_ 2600468500 NM_Kombi_NM_State 2000;
BA_REL_ "GenSigTimeoutTime" BU_SG_REL_ ZR_MIB_OPTION_ab_Gen3 SG_ 2600468500 NM_Kombi_NM_State 2000;
BA_REL_ "GenSigTimeoutTime" BU_SG_REL_ ZR_MIB_TOP_ab_Gen3 SG_ 2600468500 NM_Kombi_NM_State 2000;
BA_REL_ "GenSigTimeoutTime" BU_SG_REL_ ZR_Standard SG_ 2600468500 NM_Kombi_NM_State 2000;
BA_REL_ "GenSigTimeoutTime" BU_SG_REL_ ABT_1_MIB_ab_Gen3 SG_ 2600468726 NM_LSR_1_NM_State 2000;
BA_REL_ "GenSigTimeoutTime" BU_SG_REL_ ABT_1_MQB SG_ 2600468726 NM_LSR_1_NM_State 2000;
BA_REL_ "GenSigTimeoutTime" BU_SG_REL_ BT_1_MQB SG_ 2600468726 NM_LSR_1_NM_State 2000;
BA_REL_ "GenSigTimeoutTime" BU_SG_REL_ DU_1_MQB SG_ 2600468726 NM_LSR_1_NM_State 2000;
BA_REL_ "GenSigTimeoutTime" BU_SG_REL_ DU_2 SG_ 2600468726 NM_LSR_1_NM_State 2000;
BA_REL_ "GenSigTimeoutTime" BU_SG_REL_ DU_3 SG_ 2600468726 NM_LSR_1_NM_State 2000;
BA_REL_ "GenSigTimeoutTime" BU_SG_REL_ DU_4 SG_ 2600468726 NM_LSR_1_NM_State 2000;
BA_REL_ "GenSigTimeoutTime" BU_SG_REL_ ExBox SG_ 2600468726 NM_LSR_1_NM_State 2000;
BA_REL_ "GenSigTimeoutTime" BU_SG_REL_ Kombi_TT3 SG_ 2600468726 NM_LSR_1_NM_State 2000;
BA_REL_ "GenSigTimeoutTime" BU_SG_REL_ LSR_1 SG_ 2600468726 NM_LSR_1_NM_State 2000;
BA_REL_ "GenSigTimeoutTime" BU_SG_REL_ SCC1 SG_ 2600468726 NM_LSR_1_NM_State 2000;
BA_REL_ "GenSigTimeoutTime" BU_SG_REL_ SCC2 SG_ 2600468726 NM_LSR_1_NM_State 2000;
BA_REL_ "GenSigTimeoutTime" BU_SG_REL_ SDC1 SG_ 2600468726 NM_LSR_1_NM_State 2000;
BA_REL_ "GenSigTimeoutTime" BU_SG_REL_ SDC2 SG_ 2600468726 NM_LSR_1_NM_State 2000;
BA_REL_ "GenSigTimeoutTime" BU_SG_REL_ SFA SG_ 2600468726 NM_LSR_1_NM_State 2000;
BA_REL_ "GenSigTimeoutTime" BU_SG_REL_ TVTuner_ab_Gen3_JPN SG_ 2600468726 NM_LSR_1_NM_State 2000;
BA_REL_ "GenSigTimeoutTime" BU_SG_REL_ WLC_01 SG_ 2600468726 NM_LSR_1_NM_State 2000;
BA_REL_ "GenSigTimeoutTime" BU_SG_REL_ WLC_02 SG_ 2600468726 NM_LSR_1_NM_State 2000;
BA_REL_ "GenSigTimeoutTime" BU_SG_REL_ ZR_Entry SG_ 2600468726 NM_LSR_1_NM_State 2000;
BA_REL_ "GenSigTimeoutTime" BU_SG_REL_ ZR_High SG_ 2600468726 NM_LSR_1_NM_State 2000;
BA_REL_ "GenSigTimeoutTime" BU_SG_REL_ ZR_High_Korea SG_ 2600468726 NM_LSR_1_NM_State 2000;
BA_REL_ "GenSigTimeoutTime" BU_SG_REL_ ZR_High_TT3 SG_ 2600468726 NM_LSR_1_NM_State 2000;
BA_REL_ "GenSigTimeoutTime" BU_SG_REL_ ZR_MIB_OPTION_ab_Gen3 SG_ 2600468726 NM_LSR_1_NM_State 2000;
BA_REL_ "GenSigTimeoutTime" BU_SG_REL_ ZR_MIB_TOP_ab_Gen3 SG_ 2600468726 NM_LSR_1_NM_State 2000;
BA_REL_ "GenSigTimeoutTime" BU_SG_REL_ ZR_Standard SG_ 2600468726 NM_LSR_1_NM_State 2000;
VAL_ 2549088421 WLC1_KompSchutz 0 "inaktiv" 1 "aktiv" ;
VAL_ 2549088421 WLC1_Abschaltstufe 0 "keine_Einschraenkung" 1 "Funktionseinschraenkung" ;
VAL_ 2549088421 WLC1_Transport_Mode 0 "keine_Einschraenkung" 1 "Funktionseinschraenkung" ;
VAL_ 2549088421 WLC1_Nachlauftyp 0 "Komm_bei_KL15_EIN" 1 "Komm_nach_KL15_AUS" 2 "Komm_bei_KL15_AUS" ;
VAL_ 2549088421 WLC1_SNI 165 "WLC1" ;
VAL_ 2549088421 WLC1_BusKnockOutTimer 255 "BusKnockOut_deaktiviert" ;
VAL_ 2549088421 NM_WLC1_Wakeup 0 "Peripherie_Wakeup__Ursache_nicht_bekannt" 1 "Bus_Wakeup" 2 "KL15_HW" ;
VAL_ 2549088421 NM_WLC1_Lokalaktiv 0 "war_nicht_lokal_aktiv" 1 "war_lokal_aktiv" ;
VAL_ 2549088421 WLC1_KD_Fehler 0 "kein_KD_Fehler" 1 "KD_Fehler" ;
VAL_ 2549088422 WLC2_KompSchutz 0 "inaktiv" 1 "aktiv" ;
VAL_ 2549088422 WLC2_Abschaltstufe 0 "keine_Einschraenkung" 1 "Funktionseinschraenkung" ;
VAL_ 2549088422 WLC2_Transport_Mode 0 "keine_Einschraenkung" 1 "Funktionseinschraenkung" ;
VAL_ 2549088422 WLC2_Nachlauftyp 0 "Komm_bei_KL15_EIN" 1 "Komm_nach_KL15_AUS" 2 "Komm_bei_KL15_AUS" ;
VAL_ 2549088422 WLC2_SNI 166 "WLC2" ;
VAL_ 2549088422 WLC2_BusKnockOutTimer 255 "BusKnockOut_deaktiviert" ;
VAL_ 2549088422 NM_WLC2_Wakeup 0 "Peripherie_Wakeup__Ursache_nicht_bekannt" 1 "Bus_Wakeup" 2 "KL15_HW" ;
VAL_ 2549088422 NM_WLC2_Lokalaktiv 0 "war_nicht_lokal_aktiv" 1 "war_lokal_aktiv" ;
VAL_ 2549088422 WLC2_KD_Fehler 0 "kein_KD_Fehler" 1 "KD_Fehler" ;
VAL_ 1720 KBI_Variante_USA 0 "keine USA-Variante" 1 "USA-Variante" ;
VAL_ 1720 KBI_Variante 0 "Zeiger Kombiinstrument" 1 "Volldisplay Kombiinstrument" ;
VAL_ 1720 KBI_GAP_Warn_Zeit_abgelaufen 0 "Zaehler_nicht_abgelaufen" 1 "Zaehler_abgelaufen" ;
VAL_ 1720 KBI_Quittierung_Naesse 0 "nicht_quittiert" 1 "quittiert" ;
VAL_ 1720 KBI_BCmE_aktiv 0 "Anzeige_nicht_aktiv" 1 "Anzeige_aktiv" ;
VAL_ 1720 KBI_Sparhinweis_quittiert 0 "nicht_quittiert" 1 "quittiert" ;
VAL_ 1720 KBI_Tankfuellstand_Prozent 126 "Init" 127 "Fehler" ;
VAL_ 1720 KBI_Nachtanken_erkannt 0 "Geberbetrieb" 1 "Nachtankmodus" ;
VAL_ 1720 KBI_Tankinhalt_hochaufl 16382 "Init" 16383 "Fehler" ;
VAL_ 1720 KBI_Max_Tankinhalt 254 "Init" 255 "Fehler" ;
VAL_ 1720 KBI_Quittierung_cAQP 0 "nicht_quittiert" 1 "quittiert" ;
VAL_ 1725 KBI_Fotosensor 254 "Init" 255 "Fehler" ;
VAL_ 1725 KBI_KL58d 255 "Fehler" ;
VAL_ 1725 KBI_KL58s 126 "Init" 127 "Fehler" ;
VAL_ 1725 KBI_Uhr_Verstellung 1 "sofortige Synchronisation der Uhrzeit im Gateway" ;
VAL_ 2527679493 KBI_Req_TID 0 "Init" ;
VAL_ 2527679493 KBI_LVDS_Lock 0 "Init_LVDS_nicht_gelockt" 1 "LVDS_gelockt" ;
VAL_ 2527679493 KBI_Req_Lastmode 0 "Init_MainContext_als_Request" 1 "MainContext_als_Lastmode_Info" ;
VAL_ 2527679493 KBI_Req_Focus 0 "Init" 1 "Kombi_alle_Tasten_ohne_Hardkey" 2 "MMI_ohne_Pfeil_und_View_Taste" 3 "MMI_alle_Taster" 4 "MMI_incl_Pfeil_Tasten" 5 "Kombi_alle_Tasten_ohne_MMI_Func" 6 "Kombi_alle_Tasten_mit_MMI_Func" ;
VAL_ 2527679493 KBI_Req_ScreenFormat 0 "Init" 1 "Small" 2 "Large" ;
VAL_ 2527679493 KBI_Req_MainContext 0 "Init_Disp_aus" 16 "Navi_allgemein" 20 "Navi_Karte" 22 "Navi_Ziele" 32 "Madia_oder_Radio_lt_History" 36 "Radio" 39 "Media" 48 "Telefon" 62 "Telefon_B_Call" 63 "Telefon_C_Call" 80 "Klangeinstellung" 81 "Setup_MMI" 96 "Apps" 112 "Connect" 113 "Office" 114 "Connectivity_Manager" 115 "VICS" 116 "TPEG" 117 "Apple_CarPlay" 118 "Google_Android_Auto" 128 "CAR_Kontext" 129 "Car_360_View" 130 "Car_Favoriten" 131 "Car_Fahrerassistenz" 132 "CAR_Fahrzeugeinstellungen" 133 "Klima" 134 "Standheizung" 135 "Service_und_Kontrolle" 136 "Drive_Select" 137 "Laden" 138 "Einparkhilfe" 139 "Bordbuch" 140 "Electronic_Toll_Collect" 176 "Kombi_Kontext_allgemein" 177 "Bordcomputer" 179 "Bordcomputer_Uebersicht" 181 "FAS_Screen" 182 "Laptimer" 184 "Nightvision" 185 "beruhigter_Screen" 186 "Verkehrszeichenanzeige" ;
VAL_ 2527679493 KBI_Req_PopupContext 0 "Init_Disp_aus" 1 "Kombi_PopUp" ;
VAL_ 2527679493 KBI_Req_MenuContext 1 "OptionsMenu" 2 "SelectionMenu" 4 "Partial_Popup" 8 "2ndStatusLine" ;
VAL_ 2527679493 KBI_Req_Animation_Screen_SubType 0 "Init" ;
VAL_ 2527679493 KBI_Req_Animation_Screen_Type 0 "Init" ;
VAL_ 2527679493 KBI_Req_Animation_Lead_Time 255 "Init" ;
VAL_ 2527679493 KBI_Req_Animation_Add_Info 0 "Init" ;
VAL_ 2527679492 KBI_Sta_TID 0 "Init" ;
VAL_ 2527679492 KBI_Sta_Focus 0 "Init" 1 "Kombi_alle_Tasten_ohne_Hardkey" 2 "MMI_ohne_Pfeil_und_View_Taste" 3 "MMI_alle_Tasten" 4 "MMI_incl_Pfeil_Tasten" 5 "Kombi_alle_Tasten_ohne_MMI_Func" 6 "Kombi_alle_Tasten_mit_MMI_Func" ;
VAL_ 2527679492 KBI_Sta_ScreenFormat 0 "Init" 1 "Small" 2 "Large" ;
VAL_ 2527679492 KBI_Sta_MainContext 0 "Init_Disp_aus" 16 "Navi_01" 17 "Navi_02" 18 "Navi_03" 19 "Navi_04" 20 "Navi_05_Karte_Weltkugelsymbol" 21 "Navi_06" 22 "Navi_07_Ziele_Zielflaggensymbol" 23 "Navi_08" 24 "Navi_09" 25 "Navi_10" 26 "Navi_11" 27 "Navi_12" 28 "Navi_13" 29 "Navi_14" 30 "Navi_15" 31 "Navi_16" 32 "Media_01" 33 "Media_02" 34 "Media_03" 35 "Media_04" 36 "Media_05_Radio" 37 "Media_06" 38 "Media_07" 39 "Media_08_Media" 40 "Media_09" 41 "Media_10" 42 "Media_11" 43 "Media_12" 44 "Media_13" 45 "Media_14" 46 "Media_15" 47 "Media_16" 48 "Telefon_01" 49 "Telefon_02" 50 "Telefon_03" 51 "Telefon_04" 52 "Telefon_05" 53 "Telefon_06" 54 "Telefon_07" 55 "Telefon_08" 56 "Telefon_09" 57 "Telefon_10" 58 "Telefon_11" 59 "Telefon_12" 60 "Telefon_13" 61 "Telefon_14" 62 "Telefon_15_B_Call" 63 "Telefon_16_C_Call" 74 "Entwicklerframe_MMI" 75 "SW_Download_Frame_MMI" 80 "Klangeinstellung" 81 "Systemeinstellung" 82 "MMI_Einstellung_03" 83 "MMI_Einstellung_04" 84 "MMI_Einstellung_05" 85 "MMI_Einstellung_06" 86 "MMI_Einstellung_07" 87 "MMI_Einstellung_08" 88 "MMI_Einstellung_09" 89 "MMI_Einstellung_10" 90 "MMI_Einstellung_11" 91 "MMI_Einstellung_12" 92 "MMI_Einstellung_13" 93 "MMI_Einstellung_14" 94 "MMI_Einstellung_15" 95 "MMI_Einstellung_16" 96 "Apps_01" 97 "Apps_02" 98 "Apps_03" 99 "Apps_04" 100 "Apps_05" 101 "Apps_06" 102 "Apps_07" 103 "Apps_08" 104 "Apps_09" 105 "Apps_10" 106 "Apps_11" 107 "Apps_12" 108 "Apps_13" 109 "Apps_14" 110 "Apps_15" 111 "Apps_16" 112 "Connect" 113 "Office" 114 "Connectivity_Manager" 115 "VICS" 116 "TPEG" 117 "Apple_CarPlay" 118 "Google_Android_Auto" 129 "Car_360_View" 130 "Car_Favoriten" 131 "Car_Fahrerassistenz" 132 "Car_Fahrzeugeinstellungen" 133 "Klima" 134 "Standheizung" 135 "Service_und_Kontrolle" 136 "Drive_Select" 137 "Laden" 138 "Einparkhilfe" 139 "Bordbuch" 140 "Electronic_Toll_Collect" 161 "Kombi_Meldung_01" 162 "Kombi_Meldung_02" 163 "Kombi_Meldung_03" 164 "Kombi_Meldung_04" 165 "Kombi_Meldung_05" 166 "Kombi_Meldung_06" 167 "Kombi_Meldung_07" 168 "Kombi_Meldung_08" 174 "Layoutauswahl" 175 "Kombi_Hauptmenue" 176 "Auswahl_Optionsmenu_Kombikontext" 177 "Bordcomputer" 179 "Bordcomputer_Uebersicht" 181 "FAS_Screen" 182 "Laptimer" 183 "Bordcomputer_Sonderanzeigen" 184 "Nightvision" 185 "beruhigter_Screen" 186 "Verkehrszeichenanzeige" 187 "Einparkhilfe_Meldungen" 192 "Kombi_Welcome_Screen" 193 "Kombi_Goodbye_Screen" 237 "Kombi_Entwicklungsframe_01" 238 "Kombi_Entwicklungsframe_02" 240 "Kombi_Meldungskontext_01" 241 "Kombi_Meldungskontext_02" 242 "Kombi_Meldungskontext_03" 243 "Kombi_Meldungskontext_04" 244 "Kombi_Meldungskontext_05" 245 "Kombi_Meldungskontext_06" 246 "Kombi_Meldungskontext_07" 247 "Kombi_Meldungskontext_08" 248 "Kombi_Meldungskontext_09" ;
VAL_ 2527679492 KBI_Sta_PopupContext 0 "Init_NoPopUp" 1 "Kombi_PopUp" ;
VAL_ 2527679492 KBI_Sta_MenuContext 1 "OptionsMenu" 2 "SelectionMenu" 4 "Partial_Popup" 8 "2ndStatusLine" ;
VAL_ 2527679492 KBI_Sta_Animation_Screen_SubType 0 "Init" ;
VAL_ 2527679492 KBI_Sta_Animation_Screen_Type 0 "Init" ;
VAL_ 2527679492 KBI_Sta_Animation_Lead_Time 255 "Init" ;
VAL_ 2527679492 KBI_Sta_Animation_Add_Info 0 "Init" ;
VAL_ 2527679502 KBI_Popup_TID 0 "Init_Aktion_ohne_Request" ;
VAL_ 2527679502 KBI_Popup_MMIPopupState 0 "gelöscht, zurückgenommen" 1 "PopUp_angemeldet" ;
VAL_ 2527679502 KBI_Popup_MMIPopupID 0 "Init_keine_gueltige_ID" 1 "Kombi_ID" ;
VAL_ 2527679502 KBI_Popup_MMIPopupPriority 0 "Init" ;
VAL_ 2527679502 KBI_Popup_ZPMSlotID 0 "ungültige Anforderung" 1 "ZPM-ID 0x8A00 für z. B. Einparkhilfe (RVC, Sideview (Japan))" 2 "ZPM-ID 0x4A00 z. B. für Entwicklermenü MMI" 3 " ZPM-ID 0x4B00 z. B. für SW-Download MMI" 4 "ZPM-ID 0x4100 z. B. für MMI-Meldungen (mittlere Prio)" 5 "ZPM-ID 0x3000 z. B. für Telefon-Pop-Ups" 6 "ZPM-ID 0x1000 z. B. für Navi-Pop-Ups" 7 "ZPM-ID 0x7000 z. B. für Connect-/Office-Pop-Ups" 8 "ZPM-ID 0x6000 z. B. für Pop-Ups zu Apps" 9 "ZPM-ID 0x2000 z. B. für Media-Pop-Ups" 10 "ZPM-ID 0x4200 z. B. für MMI-Meldungen (niedrige Prio)" 11 "ZPM-ID 0x1200 z. B. für Navi-Zielführungs-Pop-Up" 12 "ZPM_ID_0x3001" ;
VAL_ 2527679502 KBI_Popup_ScreenFormat 0 "Init" 1 "Small_kleine_Buehne" 2 "Large_grosse_Buehne" ;
VAL_ 2527679502 KBI_Popup_Focus 0 "Init" 1 "KI_all" 2 "MMI" 3 "MMI_all" 4 "MMI_o_V" 5 "KI_HKQ" 6 "KI_HKQF" ;
VAL_ 1148 LSR_Variant 0 "Init" ;
VAL_ 1148 LSR_SystemMode 0 "bootloader" 1 "applikation" ;
VAL_ 1148 LSR_DKM_Kurzschluss_GND 0 "normal" 1 "Fehler" ;
VAL_ 1148 LSR_DKM_Kurzschluss_Ubat 0 "normal" 1 "Fehler" ;
VAL_ 1148 LSR_SW_inkonsistent 0 "kein_Fehler" 1 "Fehler" ;
VAL_ 1148 LSR_DKM_Kurzschluss_Unterbrec000 0 "normal" 1 "Fehler" ;
VAL_ 1148 LSR_DKM_k_Hallsignal 0 "normal" 1 "Fehler" ;
VAL_ 1148 LSR_DKM_Ueberlastung 0 "normal" 1 "Fehler" ;
VAL_ 1148 LSR_DKM_Mech_Flauf 0 "normal" 1 "Fehler" ;
VAL_ 1148 LSR_DKM_El_Fehler 0 "normal" 1 "Fehler" ;
VAL_ 1148 LSR_DKM_Manual_Operation 0 "Display_in_Ruhe" 1 "Display_per_Hand_geschlossen" 2 "Display_per_Hand_geoeffnet" 3 "reserviert" ;
VAL_ 1471 MFL_Tastencode_1 0 "Key_Released__No_Key" 1 "Context_Menu" 2 "Menu_Up__Next_Screen" 3 "Menu_Down__Previous_Screen" 4 "Up" 5 "Down" 6 "Up__Down_ThumbWheel" 7 "OK__ThumbWheel_Button" 8 "Cancel__Escape" 9 "Main_Menu" 10 "Side_Menu_left" 11 "Side_Menu_right" 12 "FAS_Menu" 13 "Left__Right_ThumbWheel" 16 "Volume_Up" 17 "Volume_Down" 18 "Volume_Up__Down_ThumbWheel" 19 "Volume_ThumbWheel_Button" 20 "Audio_Source" 21 "Arrow_A_Up__Right" 22 "Arrow_A_Down__Left" 23 "Arrow_B_Up__Right" 24 "Arrow_B_Down__Left" 25 "PTT__PushToTalk" 26 "PTT_Cancel" 27 "Route_Info" 28 "Hook" 29 "Hang_Up" 30 "Off_Hook" 31 "Light_On__Off" 32 "Mute" 33 "Joker1" 34 "Joker2" 35 "View" 36 "Arrow_A_Up__Down_ThumbWheel" 37 "Lenkradheizung" 38 "Rekuperation" 39 "Tube_Toggle" 100 "MAP" 101 "MAP_Boost" 102 "Turn_signal_left" 103 "Turn_signal_right" 104 "Turn_signal_off" 105 "Flashlight" 106 "Highbeam" 107 "Washer_button" 108 "Wiper_button_left" 109 "Wiper_button_right" 110 "Wiper_button_cancel" 111 "Exhaust_Sound" 112 "Drive_Select_button" 113 "Sport_button" 114 "ESP_Drift_Selection_ThumbWheel" 115 "PTT_special_vehicle" 116 "TravelAssist" 240 "Startup_Reset" 241 "Initialization" ;
VAL_ 1471 MFL_Tastencode_2 0 "Key_Released__No_Key" 1 "Context_Menu" 2 "Menu_Up__Next_Screen" 3 "Menu_Down__Previous_Screen" 4 "Up" 5 "Down" 6 "Up__Down_ThumbWheel" 7 "OK__ThumbWheel_Button" 8 "Cancel__Escape" 9 "Main_Menu" 10 "Side_Menu_left" 11 "Side_Menu_right" 12 "FAS_Menu" 13 "Left__Right_ThumbWheel" 16 "Volume_Up" 17 "Volume_Down" 18 "Volume_Up__Down_ThumbWheel" 19 "Volume_ThumbWheel_Button" 20 "Audio_Source" 21 "Arrow_A_Up__Right" 22 "Arrow_A_Down__Left" 23 "Arrow_B_Up__Right" 24 "Arrow_B_Down__Left" 25 "PTT__PushToTalk" 26 "PTT_Cancel" 27 "Route_Info" 28 "Hook" 29 "Hang_Up" 30 "Off_Hook" 31 "Light_On__Off" 32 "Mute" 33 "Joker1" 34 "Joker2" 35 "View" 36 "Arrow_A_Up_Right_Down_Left_ThumbWheel" 37 "Lenkradheizung" 38 "Rekuperation" 39 "Tube_Toggle" 100 "MAP" 101 "MAP_Boost" 102 "Turn_signal_left" 103 "Turn_signal_right" 104 "Turn_signal_off" 105 "Flashlight" 106 "Highbeam" 107 "Washer_button" 108 "Wiper_button_left" 109 "Wiper_button_right" 110 "Wiper_button_cancel" 111 "Exhaust_Sound" 112 "Drive_Select_button" 113 "Sport_button" 114 "ESP_Drift_Selection_ThumbWheel" 115 "PTT_special_vehicle" 116 "TravelAssist" 240 "Startup_Reset" 241 "Initialization" ;
VAL_ 1471 MFL_Eventcode_1 0 "W_no_event____T_no_event" 1 "W_1_Tick_up__T_pressed_normal" 2 "W_2_Ticks_up__T_touched" 3 "W_3_Ticks_up__T_double_click_nor" 4 "W_4_Ticks_up__T_long_press_nor_1" 5 "W_5_Ticks_up__T_long_press_nor_2" 6 "W_6_Ticks_up__T_long_press_nor_3" 7 "W_7_Ticks_up" 9 "W_7_Ticks_dn__T_pressed_strong" 10 "W_6_Ticks_dn" 11 "W_5_Ticks_dn__T_double_click_str" 12 "W_4_Ticks_dn__T_long_press_str_1" 13 "W_3_Ticks_dn__T_long_press_str_2" 14 "W_2_Ticks_dn__T_long_press_str_3" 15 "W_1_Tick_dn" ;
VAL_ 1471 MFL_Eventcode_2 0 "W_no_event____T_no_event" 1 "W_1_Tick_up__T_pressed_normal" 2 "W_2_Ticks_up__T_touched" 3 "W_3_Ticks_up__T_double_click_nor" 4 "W_4_Ticks_up__T_long_press_nor_1" 5 "W_5_Ticks_up__T_long_press_nor_2" 6 "W_6_Ticks_up__T_long_press_nor_3" 7 "W_7_Ticks_up" 9 "W_7_Ticks_dn__T_pressed_strong" 10 "W_6_Ticks_dn" 11 "W_5_Ticks_dn__T_double_click_str" 12 "W_4_Ticks_dn__T_long_press_str_1" 13 "W_3_Ticks_dn__T_long_press_str_2" 14 "W_2_Ticks_dn__T_long_press_str_3" 15 "W_1_Tick_dn" ;
VAL_ 1471 MFL_Marke 0 "VW" 1 "Audi" 2 "Seat" 3 "Skoda" 4 "VW_Nutzf" 5 "Bugatti" 6 "Lamborghini" 7 "Bentley" 8 "Rolls Royce" 9 "Quattro" 10 "kein_Hersteller_1" 11 "kein_Hersteller_2" 12 "kein_Hersteller_3" 13 "kein_Hersteller_4" 14 "Ford" 15 "Porsche" ;
VAL_ 2527679491 ZR_Req_TID 0 "Init" ;
VAL_ 2527679491 ZR_Req_Quit_Info 0 "Init_keine_Quit_angefordert" 1 "zusaetz_Quittierung" ;
VAL_ 2527679491 ZR_Req_Focus 0 "Init " 1 "Kombi_alle_Tasten_ohne_Hardkey" 2 "MMI_ohne_Pfeil_und_View_Taste" 3 "MMI_alle_Tasten" 4 "MMI_incl_Pfeil_Tasten" 5 "Kombi_alle_Tasten_ohne_MMI_Func" 6 "Kombi_alle_Tasten_mit_MMI_Func" ;
VAL_ 2527679491 ZR_Req_ScreenFormat 0 "Init" 1 "Small" 2 "Large" ;
VAL_ 2527679491 ZR_Req_MainContext 0 "Init_Disp_aus" 20 "Navi_Karte_Weltkugelsymbol" 22 "Navi_Ziele_Zielflaggensymbol" 32 "Audio_Media_oder_Radio" 36 "Radio" 39 "Media" 48 "Telefon" 62 "Telefon_B_Call" 63 "Telefon_C_Call" 65 "vollfl_PupUp_mittlere_Prio" 66 "vollfl_PupUp_niedrige_Prio" 74 "Entwicklerframe_MMI" 75 "SW_Download_Frame_MMI" 80 "Klangeinstellung" 81 "Systemeinstellung" 96 "Apps" 112 "Connect" 113 "Office" 114 "Connectivity_Manager" 115 "VICS" 116 "TPEG" 129 "Car_360_View" 130 "Car_Favoriten" 131 "Car_Fahrerassistenz" 132 "Car_Fahrzeugeinstellungen" 133 "Klima" 134 "Standheizung" 135 "Service_und_Kontrolle" 136 "Drive_Select" 137 "Laden" 138 "Einparkhilfe" 139 "Bordbuch" 140 "Electronic_Toll_Collect" 175 "Hauptmenue" 176 "Bordcomputer" 182 "Laptimer" 184 "Nightvison" 185 "beruhighter_Screen" 186 "Verkehrszeichenanzeige" 193 "Kombi_Goodbye_Screen" 254 "Kombi_Historie_MMI_an" 255 "Kombi_Historie_MMI_aus" ;
VAL_ 2527679491 ZR_Req_PopupContext 0 "kein_PopUp_gefordert" 1 "Kombi_Popup_beibehalten" 2 "MMI_Popup_beibehalten" 65 "Vollfl_Pupup_mittlere_Prio" 66 "Vollfl_Popup_niedrige_Prio" ;
VAL_ 2527679491 ZR_Req_MenuContext 1 "OptionsMenu" 2 "SelectionMenu" 4 "Partial_Popup" 8 "2ndStatusLine" ;
VAL_ 2527679490 ZR_Sta_TID 0 "Init" ;
VAL_ 2527679490 ZR_Sta_Focus 0 "Init" 1 "Kombi_alle_Tasten_ohne_Hardkey" 2 "MMI_ohne_Pfeil_und_View_Taste" 3 "MMI_alle_Tasten" 4 "MMI_incl_Pfeil_Tasten" 5 "MMI_alle_Tasten_ohne_MMI_Func" 6 "Kombi_alle_Tasten_mit_MMI_Func" ;
VAL_ 2527679490 ZR_Sta_ScreenFormat 0 "Init" 1 "Small" 2 "Large" ;
VAL_ 2527679490 ZR_Sta_MainContext 0 "Init_Disp_aus" 20 "Navi_Karte_Weltkugelsymbol" 22 "Navi_Ziele_Zielflaggensymbol" 32 "Audio_Media_oder_Radio" 36 "Radio" 39 "Media" 48 "Telefon" 62 "Telefon_B_Call" 63 "Telefon_C_Call" 65 "MMI_Popup_vollfl_mittlere_Prio" 66 "MMI_Popup_vollfl_niedere_Prio" 74 "Entwicklerframe_MMI" 75 "SW_Download_Frame_MMI" 80 "Klangeinstellung" 81 "Systemeinstellung" 96 "Apps" 112 "Connect" 113 "Office" 114 "Connectivity_Manager" 115 "VICS" 116 "TPEG" 129 "Car_360_View" 130 "Car_Favoriten" 131 "Car_Fahrerassistenz" 132 "Car_Fahrzeugeinstellungen" 133 "Klima" 134 "Standheizung" 135 "Service_und_Kontrolle" 136 "Drive_Select" 137 "Laden" 138 "Einparkhilfe" 139 "Bordbuch" 140 "Electronic_Toll_Collect" 255 "MMI_aus_Screen" ;
VAL_ 2527679490 ZR_Sta_PopupContext 0 "Init_NoPopUp" 1 "Kombi_PopUp" ;
VAL_ 2527679490 ZR_Sta_MenuContext 0 "OptionsMenu" 1 "SelectionMenu" 2 "Partial_Popup" 8 "2ndStatusLine" ;
VAL_ 2527679490 ZR_Sta_AnimationInfo 0 "Init" ;
VAL_ 2527679490 ZR_Sta_KDKOpacity 0 "Init" ;
VAL_ 2527679490 ZR_Sta_KDK_PosInfo 0 "Init" ;
VAL_ 2527679490 ZR_Sta_NavBargraph 0 "Init_nicht_in_Anzeige" 1 "in_Anzeige" ;
VAL_ 2527679490 ZR_Sta_KDK 0 "Init_KDK_inaktiv" 1 "KDK_aktiv" ;
VAL_ 2527679501 ZR_Popup_TID 0 "Init_Aktion_ohne_Request" ;
VAL_ 2527679501 ZR_Popup_MMIPopupReqState 0 "loeschen_oder_zuruecknehmen" 1 "anfordern_oder_setzen" ;
VAL_ 2527679501 ZR_Popup_MMIIDReq 0 "Init_keine_gueltige_ID" 1 "Kombi_ID" ;
VAL_ 2527679501 ZR_Popup_MMIPopupPriorityReq 0 "Init" ;
VAL_ 2527679501 ZR_Popup_ZPMSlotIDReq 0 "Init" 1 "ZPM-ID 0x8A00 für z. B. Einparkhilfe (RVC, Sideview (Japan))" 2 "ZPM-ID 0x4A00 z. B. für Entwicklermenü MMI" 3 "ZPM-ID 0x4B00 z. B. für SW-Download MMI" 4 "ZPM-ID 0x4100 z. B. für MMI-Meldungen (mittlere Prio)" 5 "ZPM-ID 0x3000 z. B. für Telefon-Pop-Ups" 6 "ZPM-ID 0x1000 z. B. für Navi-Pop-Ups" 7 "ZPM-ID 0x7000 z. B. für Connect-/Office-Pop-Ups" 8 "ZPM-ID 0x6000 z. B. für Pop-Ups zu Apps" 9 "ZPM-ID 0x2000 z. B. für Media-Pop-Ups" 10 "ZPM-ID 0x4200 z. B. für MMI-Meldungen (niedrige Prio)" 11 "ZPMID_0x1300_zB_Navi_Ziel_PopUp" 12 "ZPM_ID_0x3001" ;
VAL_ 2527679501 ZR_Popup_ScreenFormat 0 "Init" 1 "Small_kleine_Buehne" 2 "Large_grosse_Buehne" ;
VAL_ 2527679501 ZR_Popup_Focus 0 "Init" 1 "KI_all" 2 "MMI" 3 "MMI_all" 4 "MMI_o_V" 5 "KI_HKQ" 6 "KI_HKQF" ;
VAL_ 2527679499 ZR_Sta_360_View 0 "Init" 1 "verbaut und nicht bereit" 2 "verbaut und bereit" 3 "nicht verbaut" ;
VAL_ 2527679499 ZR_Sta_Favoriten 0 "Init" 1 "verbaut und nicht bereit" 2 "verbaut und bereit" 3 "nicht verbaut" ;
VAL_ 2527679499 ZR_Sta_Laden 0 "Init" 1 "verbaut und nicht bereit" 2 "verbaut und bereit" 3 "nicht verbaut" ;
VAL_ 2527679499 ZR_Sta_FAS 0 "Init" 1 "verbaut und nicht bereit" 2 "verbaut und bereit" 3 "nicht verbaut" ;
VAL_ 2527679499 ZR_Sta_Fzg_Einst 0 "Init" 1 "verbaut und nicht bereit" 2 "verbaut und bereit" 3 "nicht verbaut" ;
VAL_ 2527679499 ZR_Sta_Klima 0 "Init" 1 "verbaut und nicht bereit" 2 "verbaut und bereit" 3 "nicht verbaut" ;
VAL_ 2527679499 ZR_Sta_Standhzg 0 "Init" 1 "verbaut und nicht bereit" 2 "verbaut und bereit" 3 "nicht verbaut" ;
VAL_ 2527679499 ZR_Sta_Service 0 "Init" 1 "verbaut und nicht bereit" 2 "verbaut und bereit" 3 "nicht verbaut" ;
VAL_ 2527679499 ZR_Sta_Fahrprofil 0 "Init" 1 "verbaut und nicht bereit" 2 "verbaut und bereit" 3 "nicht verbaut" ;
VAL_ 2527679499 ZR_Sta_Race 0 "Init" 1 "verbaut und nicht bereit" 2 "verbaut und bereit" 3 "nicht verbaut" ;
VAL_ 2527679499 ZR_Sta_Office 0 "Init" 1 "verbaut und nicht bereit" 2 "verbaut und bereit" 3 "nicht verbaut" ;
VAL_ 2527679499 ZR_Sta_Bordbuch 0 "Init" 1 "verbaut und nicht bereit" 2 "verbaut und bereit" 3 "nicht verbaut" ;
VAL_ 2527679499 ZR_Sta_Profile 0 "Init" 1 "verbaut_nicht_bereit" 2 "verbaut_und_bereit" 3 "nicht_verbaut" ;
VAL_ 2527679499 ZR_Sta_Connect 0 "Init" 1 "verbaut_nicht_bereit" 2 "verbaut_und_bereit" 3 "nicht_verbaut" ;
VAL_ 2527679499 ZR_Sta_Klang 0 "Init" 1 "verbaut_nicht_bereit" 2 "verbaut_und_bereit" 3 "nicht_verbaut" ;
VAL_ 2527679499 ZR_Sta_Systemeinst 0 "Init" 1 "verbaut_nicht_bereit" 2 "verbaut_und_bereit" 3 "nicht_verbaut" ;
VAL_ 2527679499 ZR_Sta_ConnectivityManager 0 "Init" 1 "verbaut und nicht bereit" 2 "verbaut und bereit" 3 "nicht verbaut" ;
VAL_ 2527679499 ZR_Sta_ETC 0 "Init" 1 "verbaut_nicht_bereit" 2 "verbaut_und_bereit" 3 "nicht_verbaut" ;
VAL_ 2527679499 ZR_Sta_SmartPhone 0 "Init" 1 "verbaut_nicht_bereit" 2 "verbaut_und_bereit" 3 "nicht_verbaut" ;
VAL_ 2527679499 ZR_Sta_B_Call 0 "Init" 1 "verbaut_nicht_bereit" 2 "verbaut_und_bereit" 3 "nicht_verbaut" ;
VAL_ 2527679499 ZR_Sta_C_Call 0 "Init" 1 "verbaut_nicht_bereit" 2 "verbaut_und_bereit" 3 "nicht_verbaut" ;
VAL_ 2527679499 ZR_Sta_VICS 0 "Init" 1 "verbaut_nicht_bereit" 2 "verbaut_und_bereit" 3 "nicht_verbaut" ;
VAL_ 2527679499 ZR_Sta_TPEG 0 "Init" 1 "verbaut_nicht_bereit" 2 "verbaut_und_bereit" 3 "nicht_verbaut" ;
VAL_ 1156 ND_VDOP 1022 "Init" 1023 "Fehler" ;
VAL_ 1156 ND_TDOP 1022 "Init" 1023 "Fehler" ;
VAL_ 1156 ND_HDOP 1022 "Init" 1023 "Fehler" ;
VAL_ 1156 ND_GDOP 1022 "Init" 1023 "Fehler" ;
VAL_ 1156 ND_PDOP 1022 "Init" 1023 "Fehler" ;
VAL_ 1156 ND_Heading 4094 "Init" 4095 "Fehler" ;
VAL_ 1156 ND_Init 0 "nicht_Initialisiert" 1 "Initialisiert" ;
VAL_ 1157 ND_SatInUse 30 "Init" 31 "Fehler" ;
VAL_ 1157 POS_Guete_horizontal_verfuegbar 0 "nicht_verfuegbar" 1 "verfuegbar" ;
VAL_ 1157 ND_SatInView 30 "Init" 31 "Fehler" ;
VAL_ 1157 POS_Guete_horizontal 124 "von_248m_bis_400m" 125 "mehr_als_400m" 126 "Init" 127 "Fehler" ;
VAL_ 1157 NP_Altitude 4094 "Init" 4095 "Fehler" ;
VAL_ 1158 NP_LatDegree 134217726 "Init" 134217727 "Fehler" ;
VAL_ 1158 NP_LongDegree 268435454 "Init" 268435455 "Fehler" ;
VAL_ 1158 NP_LatDirection 0 "Nord" 1 "Sued" ;
VAL_ 1158 NP_LongDirection 0 "Ost" 1 "West" ;
VAL_ 1158 NP_Sat 30 "Init" 31 "Fehler" ;
VAL_ 1158 NP_Fix 0 "Init" 1 "No_Fix" 2 "2D_Fix" 3 "3D_Fix" ;
VAL_ 2589283496 POS_MUX 0 "MUX_0" 1 "MUX_1" 2 "reserved" 3 "Init" ;
VAL_ 2589283496 POS_ODD_EVEN 0 "ODD" 1 "EVEN" ;
VAL_ 2589283496 POS_PosStati 0 "Init" 1 "NoNavAvailable" 2 "NoMapAvailable" 3 "NavBooting" 4 "NavError" 5 "NavCalibrating" 6 "NavNoGpsResyncSince1h" 7 "NavOffroadParkgarageRampOffset2" 8 "DeadReckoningWithoutGps" 9 "DeadReckoningWithGps" 10 "MapMatchedLowConfidence" 11 "MapMatchedLimitedConfidence" 12 "OffroadHighConfidence" 13 "MapMatchedHighConfidence" 14 "PosInSyncWithGpsAndMAP" ;
VAL_ 2589283496 POS_LatDirection 0 "North" 1 "South" ;
VAL_ 2589283496 POS_LatDegree 134217726 "Init" 134217727 "Fehler" ;
VAL_ 2589283496 POS_Heading_Trust 0 "Init" 1 "TrustLevel01" 2 "TrustLevel02" 3 "Fehler" ;
VAL_ 2589283496 POS_LongDirection 0 "East" 1 "West" ;
VAL_ 2589283496 POS_LongDegree 268435454 "Init" 268435455 "Fehler" ;
VAL_ 2527679647 Stellgliedtest_NFC 0 "Init_kein_Stellgliedtest" 1 "Stellgliedtest_angefordert" ;
VAL_ 2527679647 NFC_ESM_aktivieren 0 "Init_kein_ESM" 1 "ESM_aktivieren" ;
VAL_ 2527679647 ZV_auf_NFC 0 "Init_keine_Meldung" 1 "ZV_auf_NFC" ;
VAL_ 2527679647 ZV_zu_NFC 0 "Init_keine_Meldung" 1 "ZV_zu_NFC" ;
VAL_ 2527679647 MDK_Anf_Start_Auth 0 "nicht_angefordert" 1 "angefordert" ;
VAL_ 2527679647 MDK_BTLE_Spielschutz_aktivieren 0 "Init_kein_BTLE_Spielschutz" 1 "BTLE_Spielschutz_aktiv" ;
VAL_ 2527679647 MDK_NFC_Spielschutz_aktivieren 0 "Init_kein_NFC_Spielschutz" 1 "NFC_Spielschutz_aktiv" ;
VAL_ 2527679647 MDK_01_alt 0 "aktuell" 1 "veraltet" ;
VAL_ 2527679647 NFC_Front_Verr_Authorisiert 0 "kein_NFC_Handy_erkannt" 1 "NFC_Handy_erkannt_und_authorisiert" ;
VAL_ 2527679647 NFC_Front_Entr_Authorisiert 0 "kein_NFC_Handy_erkannt" 1 "NFC_Handy_erkannt_und_authorisiert" ;
VAL_ 2527679647 NFC_HD_Verriegelung_Authorisiert 0 "kein_NFC_Handy_erkannt" 1 "NFC_Handy_erkannt_und_authorisiert" ;
VAL_ 2527679647 NFC_HD_Entriegelung_Authorisiert 0 "kein_NFC_Handy_erkannt" 1 "NFC_Handy_erkannt_und_authorisiert" ;
VAL_ 2527679647 NFC_aktiv 0 "NFC_nicht_aktiv" 1 "NFC_Kommunikation_aktiv" ;
VAL_ 2527679647 NFC_Laden_unterbrechen 0 "Laden_nicht_unterbrechen" 1 "Laden_unterbrechen" ;
VAL_ 2527679647 NFC_FT_Entriegelung_Authorisiert 0 "kein_NFC_Handy_erkannt" 1 "NFC_Handy_erkannt_und_authorisiert" ;
VAL_ 2527679647 NFC_FT_Verriegelung_Authorisiert 0 "kein_NFC_Handy_erkannt" 1 "NFC_Handy_erkannt_und_authorisiert" ;
VAL_ 2600468721 NM_ABT_1_SNI 241 "ABT" ;
VAL_ 2600468721 NM_ABT_1_NM_State 0 "Init" 1 "NM_RM_aus_BSM" 2 "NM_RM_aus_PBSM" 4 "NM_NO_aus_RM" 8 "NM_NO_aus_RS" 16 "NM_RM_aus_RS" 32 "NM_RM_aus_NO" ;
VAL_ 2600468721 NM_ABT_1_Car_Wakeup 0 "Inaktiv" 1 "Car_Wakeup" ;
VAL_ 2600468721 NM_ABT_1_Wakeup 0 "Peripherie_Wakeup__Ursache_nicht_bekannt" 1 "Bus_Wakeup" 2 "KL15_HW" 3 "Hardkey" ;
VAL_ 2600468721 NM_ABT_1_NM_aktiv_KL15 0 "Inaktiv" 1 "KL15_EIN" ;
VAL_ 2600468721 NM_ABT_1_NM_aktiv_Diagnose 0 "Init" 1 "Diagnose_aktiv" ;
VAL_ 2600468721 NM_ABT_1_NM_aktiv_Tmin 0 "Inaktiv" 1 "Mindestaktivzeit" ;
VAL_ 2600468721 NM_ABT_1_NL_Dimmung 1 "Dimmung_aktiv" ;
VAL_ 2600468721 NM_ABT_1_NL_WakeUp_Lock 1 "WakeUp_Lock_aktiv" ;
VAL_ 2600468721 NM_ABT_1_UDS_CC 0 "Init" 1 "CC_aktiv" ;
VAL_ 2600468720 NM_BT_1_SNI 240 "BT_1" ;
VAL_ 2600468720 NM_BT_1_NM_State 0 "Init" 1 "NM_RM_aus_BSM" 2 "NM_RM_aus_PBSM" 4 "NM_NO_aus_RM" 8 "NM_NO_aus_RS" 16 "NM_RM_aus_RS" 32 "NM_RM_aus_NO" ;
VAL_ 2600468720 NM_BT_1_Car_Wakeup 0 "Inaktiv" 1 "Car_Wakeup" ;
VAL_ 2600468720 NM_BT_1_Wakeup 0 "Peripherie_Wakeup__Ursache_nicht_bekannt" 1 "Bus_Wakeup" 2 "KL15_HW" 3 "Media" 4 "Telefon" 5 "Navigation" 6 "Car" 7 "Tone" 8 "Radio" 9 "Menu" 10 "On_Off" ;
VAL_ 2600468720 NM_BT_1_NM_aktiv_KL15 0 "Inaktiv" 1 "KL15_EIN" ;
VAL_ 2600468720 NM_BT_1_NM_aktiv_Diagnose 0 "Init" 1 "Diagnose_aktiv" ;
VAL_ 2600468720 NM_BT_1_NM_aktiv_Tmin 0 "Inaktiv" 1 "Mindestaktivzeit" ;
VAL_ 2600468720 NM_BT_1_NL_Dimmung 1 "Dimmung_aktiv" ;
VAL_ 2600468720 NM_BT_1_NL_WakeUp_Lock 1 "WakeUp_Lock_aktiv" ;
VAL_ 2600468720 NM_BT_1_UDS_CC 0 "Init" 1 "CC_aktiv" ;
VAL_ 2600468722 NM_DU_1_SNI 242 "" ;
VAL_ 2600468722 NM_DU_1_NM_State 0 "Init" 1 "NM_RM_aus_BSM" 2 "NM_RM_aus_PBSM" 4 "NM_NO_aus_RM" 8 "NM_NO_aus_RS" 16 "NM_RM_aus_RS" 32 "NM_RM_aus_NO" ;
VAL_ 2600468722 NM_DU_1_Car_Wakeup 0 "Inaktiv" 1 "Car_Wakeup" ;
VAL_ 2600468722 NM_DU_1_Wakeup 0 "Peripherie_Wakeup__Ursache_nicht_bekannt" 1 "Bus_Wakeup" 2 "KL15_HW" 3 "Externer_Taster1" 4 "Externer_Taster2" 5 "Touchpad" ;
VAL_ 2600468722 NM_DU_1_NM_aktiv_KL15 0 "Inaktiv" 1 "KL15_EIN" ;
VAL_ 2600468722 NM_DU_1_NM_aktiv_Diagnose 0 "Init" 1 "Diagnose_aktiv" ;
VAL_ 2600468722 NM_DU_1_NM_aktiv_Tmin 0 "Inaktiv" 1 "Mindestaktivzeit" ;
VAL_ 2600468722 NM_DU_1_NL_Dimmung 1 "Dimmung_aktiv" ;
VAL_ 2600468722 NM_DU_1_UDS_CC 0 "Init" 1 "CC_aktiv" ;
VAL_ 2600468725 NM_DU_2_SNI 245 "DU_2" ;
VAL_ 2600468725 NM_DU_2_NM_State 0 "Init" 1 "NM_RM_aus_BSM" 2 "NM_RM_aus_PBSM" 4 "NM_NO_aus_RM" 8 "NM_NO_aus_RS" 16 "NM_RM_aus_RS" 32 "NM_RM_aus_NO" ;
VAL_ 2600468725 NM_DU_2_Car_Wakeup 0 "Inaktiv" 1 "Car_Wakeup" ;
VAL_ 2600468725 NM_DU_2_Wakeup 0 "Peripherie_Wakeup__Ursache_nicht_bekannt" 1 "Bus_Wakeup" 2 "KL15_HW" 3 "Externer_Taster1" 4 "Externer_Taster2" 5 "Tochpad" ;
VAL_ 2600468725 NM_DU_2_NM_aktiv_KL15 0 "Inaktiv" 1 "KL15_EIN" ;
VAL_ 2600468725 NM_DU_2_NM_aktiv_Diagnose 0 "Init" 1 "Diagnose_aktiv" ;
VAL_ 2600468725 NM_DU_2_NM_aktiv_Tmin 0 "Inaktiv" 1 "Mindestaktivzeit" ;
VAL_ 2600468725 NM_DU_2_NL_Dimmung 1 "Dimmung_aktiv" ;
VAL_ 2600468725 NM_DU_2_UDS_CC 0 "Init" 1 "CC_aktiv" ;
VAL_ 2600468734 NM_DU_3_SNI 254 "DU_3" ;
VAL_ 2600468734 NM_DU_3_NM_State 0 "Init" 1 "NM_RM_aus_BSM" 2 "NM_RM_aus_PBSM" 4 "NM_NO_aus_RM" 8 "NM_NO_aus_RS" 16 "NM_RM_aus_RS" 32 "NM_RM_aus_NO" ;
VAL_ 2600468734 NM_DU_3_Car_Wakeup 0 "Inaktiv" 1 "Car_Wakeup" ;
VAL_ 2600468734 NM_DU_3_Wakeup 0 "Peripherie_Wakeup__Ursache_nicht_bekannt" 1 "Bus_Wakeup" 2 "KL15_HW" 3 "Externer_Taster1" 4 "Externer_Taster2" 5 "Tochpad" ;
VAL_ 2600468734 NM_DU_3_NM_aktiv_KL15 0 "Inaktiv" 1 "KL15_EIN" ;
VAL_ 2600468734 NM_DU_3_NM_aktiv_Diagnose 0 "Init" 1 "Diagnose_aktiv" ;
VAL_ 2600468734 NM_DU_3_NM_aktiv_Tmin 0 "Inaktiv" 1 "Mindestaktivzeit" ;
VAL_ 2600468734 NM_DU_3_NL_Dimmung 1 "Dimmung_aktiv" ;
VAL_ 2600468734 NM_DU_3_UDS_CC 0 "Init" 1 "CC_aktiv" ;
VAL_ 2600468724 NM_DU_4_SNI 244 "DU_4" ;
VAL_ 2600468724 NM_DU_4_NM_State 0 "Init" 1 "NM_RM_aus_BSM" 2 "NM_RM_aus_PBSM" 4 "NM_NO_aus_RM" 8 "NM_NO_aus_RS" 16 "reserved" 32 "reserved" ;
VAL_ 2600468724 NM_DU_4_Car_Wakeup 0 "Inaktiv" 1 "Car_Wakeup" ;
VAL_ 2600468724 NM_DU_4_Wakeup 0 "Inaktiv" 1 "KL15_EIN" ;
VAL_ 2600468724 NM_DU_4_NM_aktiv_KL15 0 "Inaktiv" 1 "KL15_EIN" ;
VAL_ 2600468724 NM_DU_4_NM_aktiv_Diagnose 0 "Init" 1 "Diagnose_aktiv" ;
VAL_ 2600468724 NM_DU_4_NM_aktiv_Tmin 0 "Inaktiv" 1 "Mindestaktivzeit" ;
VAL_ 2600468724 NM_DU_4_NL_Dimmung 1 "Dimmung_aktiv" ;
VAL_ 2600468724 NM_DU_4_UDS_CC 0 "Init" 1 "CC_aktiv" ;
VAL_ 2600468723 NM_ExBox_SNI 243 "ExBox" ;
VAL_ 2600468723 NM_ExBox_NM_State 0 "Init" 1 "NM_RM_aus_BSM" 2 "NM_RM_aus_PBSM" 4 "NM_NO_aus_RM" 8 "NM_NO_aus_RS" ;
VAL_ 2600468723 NM_ExBox_Car_Wakeup 0 "Inaktiv" 1 "Car_Wakeup" ;
VAL_ 2600468723 NM_ExBox_Wakeup 0 "Peripherie_Wakeup__Ursache_nicht_bekannt" 1 "Bus_Wakeup" 2 "KL15_HW" ;
VAL_ 2600468723 NM_ExBox_NM_aktiv_KL15 0 "Inaktiv" 1 "KL15_EIN" ;
VAL_ 2600468723 NM_ExBox_NM_aktiv_Diagnose 0 "Init" 1 "Diagnose_aktiv" ;
VAL_ 2600468723 NM_ExBox_NM_aktiv_Tmin 0 "Inaktiv" 1 "Mindestaktivzeit" ;
VAL_ 2600468723 NM_ExBox_UDS_CC 0 "Init" 1 "CC_aktiv" ;
VAL_ 2600468595 NM_Info_El_SNI 115 "Info_El" ;
VAL_ 2600468595 NM_Info_El_NM_State 0 "Init" 1 "NM_RM_aus_BSM" 2 "NM_RM_aus_PBSM" 4 "NM_NO_aus_RM" 8 "NM_NO_aus_RS" 16 "NM_RM_aus_RS" 32 "NM_RM_aus_NO" ;
VAL_ 2600468595 NM_Info_El_Car_Wakeup 0 "Inaktiv" 1 "Car_Wakeup" ;
VAL_ 2600468595 NM_Info_El_Wakeup 0 "Peripherie_Wakeup__Ursache_nicht_bekannt" 1 "Bus_Wakeup" 2 "KL15_HW" 3 "Eject_Button" 4 "Remote_Lock_Unlock" 5 "Remote_Standheizung" 128 "WakeUp_Lock_Anf" 129 "Display_On_Anf" 130 "HMI_OnlineUpdate" ;
VAL_ 2600468595 NM_Info_El_NM_aktiv_KL15 0 "Inaktiv" 1 "KL15_EIN" ;
VAL_ 2600468595 NM_Info_El_NM_aktiv_Diagnose 0 "Init" 1 "Diagnose_aktiv" ;
VAL_ 2600468595 NM_Info_El_NM_aktiv_Tmin 0 "Inaktiv" 1 "Mindestaktivzeit" ;
VAL_ 2600468595 NM_Info_El_NM_aktiv_MIBCAN 0 "Init" 1 "MIB_CAN_aktiv" ;
VAL_ 2600468595 NM_Info_El_NM_aktiv_BAP_Comm 0 "Init" 1 "BAP_Sound_aktiv" ;
VAL_ 2600468595 NM_Info_El_NL_MMI_ON 1 "MIBCAN_aktiv" ;
VAL_ 2600468595 NM_Info_El_NL_ICAN 1 "ICAN_aktiv" ;
VAL_ 2600468595 NM_Info_El_NL_SWDL 1 "SWDL_aktiv" ;
VAL_ 2600468595 NM_Info_El_NL_Dimmung 1 "Dimmung_aktiv" ;
VAL_ 2600468595 NM_Info_El_NL_MMI_Standby 1 "MMI_Standby" ;
VAL_ 2600468595 NM_Info_El_UDS_CC 0 "Init" 1 "CC_aktiv" ;
VAL_ 2600468500 NM_Kombi_SNI 20 "Kombi" ;
VAL_ 2600468500 NM_Kombi_NM_State 0 "Init" 1 "NM_RM_aus_BSM" 2 "NM_RM_aus_PBSM" 4 "NM_NO_aus_RM" 8 "NM_NO_aus_RS" 16 "NM_RM_aus_RS" 32 "NM_RM_aus_NO" ;
VAL_ 2600468500 NM_Kombi_Car_Wakeup 0 "Inaktiv" 1 "Car_Wakeup" ;
VAL_ 2600468500 NM_Kombi_Wakeup 0 "Peripherie_Wakeup__Ursache_nicht_bekannt" 1 "Bus_Wakeup" 2 "KL15_HW" 3 "KL30_Reset" 128 "Timer_abgelaufen" ;
VAL_ 2600468500 NM_Kombi_NM_aktiv_KL15 0 "Inaktiv" 1 "KL15_EIN" ;
VAL_ 2600468500 NM_Kombi_NM_aktiv_Diagnose 0 "Init" 1 "Diagnose_aktiv" ;
VAL_ 2600468500 NM_Kombi_NM_aktiv_Tmin 0 "Inaktiv" 1 "Mindestaktivzeit" ;
VAL_ 2600468500 NM_Kombi_NM_aktiv_Buzzer 1 "Buzzer_aktiv" ;
VAL_ 2600468500 NM_Kombi_NM_aktiv_Schluesselkomm 1 "Schluesselkomm_aktiv" ;
VAL_ 2600468500 NM_Kombi_NM_aktiv_VLW 0 "Init" 1 "VLW_aktiv" ;
VAL_ 2600468500 NM_Kombi_NL_Beleuchtung 1 "Beleuchtung_aktiv" ;
VAL_ 2600468500 NM_Kombi_UDS_CC 0 "Init" 1 "CC_aktiv" ;
VAL_ 2600468726 NM_LSR_1_SNI 242 "LSR_1" ;
VAL_ 2600468726 NM_LSR_1_NM_State 0 "Init" 1 "NM_RM_aus_BSM" 2 "NM_RM_aus_PBSM" 4 "NM_NO_aus_RM" 8 "NM_NO_aus_RS" 16 "NM_RM_aus_RS" 32 "NM_RM_aus_NO" ;
VAL_ 2600468726 NM_LSR_1_Car_Wakeup 0 "Inaktiv" 1 "Car_Wakeup" ;
VAL_ 2600468726 NM_LSR_1_Wakeup 0 "Peripherie_Wakeup__Ursache_nicht_bekannt" 1 "Bus_Wakeup" 2 "KL15_HW" 16 "On_Off" ;
VAL_ 2600468726 NM_LSR_1_NM_aktiv_KL15 0 "Inaktiv" 1 "KL15_EIN" ;
VAL_ 2600468726 NM_LSR_1_NM_aktiv_Diagnose 0 "Init" 1 "Diagnose_aktiv" ;
VAL_ 2600468726 NM_LSR_1_NM_aktiv_Tmin 0 "Inaktiv" 1 "Mindestaktivzeit" ;
VAL_ 2600468726 NM_LSR_1_NL_Dimmung 1 "Dimmung_aktiv" ;
VAL_ 2600468726 NM_LSR_1_NL_WakeUp_Lock 1 "WakeUp_Lock_aktiv" ;
VAL_ 2600468726 NM_LSR_1_UDS_CC 0 "Init" 1 "CC_aktiv" ;
